VERSION ""

NS_ :

BS_:

BU_: ADAS MRR_L MRR_M MPC CMRR_RL CMRR_RR CMRR_FL CMRR_FR MRR GW AVAP

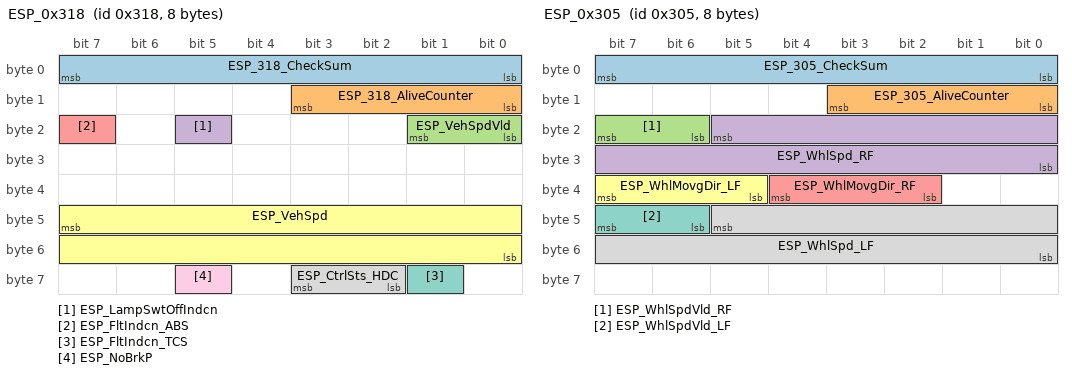
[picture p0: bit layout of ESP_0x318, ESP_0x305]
BO_ 792 ESP_0x318: 8 GW
 SG_ ESP_318_CheckSum : 7|8@0+ (1,0) [0|255] "" ADAS,MRR_L,MRR_M,MPC,CMRR_RL,CMRR_RR,CMRR_FL,CMRR_FR,MRR,AVAP
 SG_ ESP_318_AliveCounter : 11|4@0+ (1,0) [0|15] "" ADAS,MRR_L,MRR_M,MPC,CMRR_RL,CMRR_RR,CMRR_FL,CMRR_FR,MRR,AVAP
 SG_ ESP_VehSpdVld : 17|2@0+ (1,0) [0|3] "" ADAS,MRR_L,MRR_M,MPC,CMRR_RL,CMRR_RR,CMRR_FL,CMRR_FR,MRR,AVAP
 SG_ ESP_LampSwtOffIndcn : 21|1@0+ (1,0) [0|1] "" ADAS,MRR_L,MRR_M,CMRR_RL,CMRR_RR,CMRR_FL,CMRR_FR,MRR,AVAP
 SG_ ESP_FltIndcn_ABS : 23|1@0+ (1,0) [0|1] "" ADAS,MRR_L,MRR_M,MPC,CMRR_RL,CMRR_RR,CMRR_FL,CMRR_FR,MRR
 SG_ ESP_VehSpd : 47|16@0+ (0.1,0) [0|300] "km/h" ADAS,MRR_L,MRR_M,MPC,CMRR_RL,CMRR_RR,CMRR_FL,CMRR_FR,MRR,AVAP
 SG_ ESP_FltIndcn_TCS : 57|1@0+ (1,0) [0|1] "" ADAS,MRR_L,MRR_M,MPC,CMRR_RL,CMRR_RR,CMRR_FL,CMRR_FR,MRR
 SG_ ESP_CtrlSts_HDC : 59|2@0+ (1,0) [0|3] "" ADAS,MRR_L,MRR_M,CMRR_RL,CMRR_RR,CMRR_FL,CMRR_FR,MRR
 SG_ ESP_NoBrkP : 61|1@0+ (1,0) [0|1] "" ADAS,MRR_L,MRR_M,CMRR_RL,CMRR_RR,CMRR_FL,CMRR_FR,MRR

BO_ 609 ESP_0x261: 8 GW
 SG_ ESP_261_CheckSum : 7|8@0+ (1,0) [0|255] "" ADAS,MRR_L,MRR_M,MPC,CMRR_RL,CMRR_RR,CMRR_FL,CMRR_FR,MRR,AVAP
 SG_ ESP_261_AliveCounter : 11|4@0+ (1,0) [0|15] "" ADAS,MRR_L,MRR_M,MPC,CMRR_RL,CMRR_RR,CMRR_FL,CMRR_FR,MRR,AVAP
 SG_ ESP_ActvSig : 16|1@0+ (1,0) [0|1] "" ADAS,MRR_L,MRR_M,MPC,CMRR_RL,CMRR_RR,CMRR_FL,CMRR_FR,MRR,AVAP
 SG_ ESP_ActvSig_TCS : 17|1@0+ (1,0) [0|1] "" ADAS,MRR_L,MRR_M,CMRR_RL,CMRR_RR,CMRR_FL,CMRR_FR,MRR,AVAP
 SG_ ESP_ActvSig_EBD : 19|1@0+ (1,0) [0|1] "" ADAS,MRR_L,MRR_M,CMRR_RL,CMRR_RR,CMRR_FL,CMRR_FR,MRR,AVAP
 SG_ ESP_ActvSig_DTC : 20|1@0+ (1,0) [0|1] "" ADAS,MRR_L,MRR_M,CMRR_RL,CMRR_RR,CMRR_FL,CMRR_FR,MRR
 SG_ ESP_Actvndcn_CDD : 24|1@0+ (1,0) [0|1] "" ADAS,MRR_L,MRR_M
 SG_ ESP_FltIndcn_CDD : 25|1@0+ (1,0) [0|1] "" ADAS,MRR_L,MRR_M
 SG_ ESP_ActvIndcn_ABA : 26|1@0+ (1,0) [0|1] "" ADAS,MRR_L,MRR_M,MRR
 SG_ ESP_FltIndcn_ABA : 27|1@0+ (1,0) [0|1] "" ADAS,MRR_L,MRR_M,MRR
 SG_ ESP_ActvIndcn_ABP : 28|1@0+ (1,0) [0|1] "" ADAS,MRR_L,MRR_M,MRR
 SG_ ESP_FltIndcn_ABP : 29|1@0+ (1,0) [0|1] "" ADAS,MRR_L,MRR_M,MRR
 SG_ ESP_ActvIndcn_AEB : 30|1@0+ (1,0) [0|1] "" ADAS,MRR_L,MRR_M,CMRR_RL,CMRR_RR,MRR
 SG_ ESP_FltIndcn_AEB : 31|1@0+ (1,0) [0|1] "" ADAS,MRR_L,MRR_M,CMRR_RL,CMRR_RR,MRR
 SG_ ESP_ActvIndcn_AWB : 32|1@0+ (1,0) [0|1] "" ADAS,MRR_L,MRR_M,MRR
 SG_ ESP_FltIndcn_AWB : 33|1@0+ (1,0) [0|1] "" ADAS,MRR_L,MRR_M,MRR
 SG_ ESP_VehStandstillIndcn : 35|2@0+ (1,0) [0|3] "" ADAS,MRR_L,MRR_M,CMRR_RL,CMRR_RR,CMRR_FL,CMRR_FR,MRR
 SG_ ESP_BrkOverTIndcn : 36|1@0+ (1,0) [0|1] "" ADAS,MRR_L,MRR_M,MRR

BO_ 773 ESP_0x305: 8 GW
 SG_ ESP_305_CheckSum : 7|8@0+ (1,0) [0|255] "" ADAS,MRR_L,MRR_M,MPC,CMRR_RL,CMRR_RR,CMRR_FL,CMRR_FR,MRR,AVAP
 SG_ ESP_305_AliveCounter : 11|4@0+ (1,0) [0|15] "" ADAS,MRR_L,MRR_M,MPC,CMRR_RL,CMRR_RR,CMRR_FL,CMRR_FR,MRR,AVAP
 SG_ ESP_WhlSpdVld_RF : 23|2@0+ (1,0) [0|3] "" ADAS,MRR_L,MRR_M,MPC,CMRR_RL,CMRR_RR,CMRR_FL,CMRR_FR,MRR,AVAP
 SG_ ESP_WhlSpd_RF : 21|14@0+ (0.0625,0) [0|300] "km/h" ADAS,MRR_L,MRR_M,MPC,CMRR_RL,CMRR_RR,CMRR_FL,CMRR_FR,MRR,AVAP
 SG_ ESP_WhlMovgDir_RF : 36|3@0+ (1,0) [0|7] "" ADAS,MRR_L,MRR_M,MPC,CMRR_RL,CMRR_RR,CMRR_FL,CMRR_FR,MRR,AVAP
 SG_ ESP_WhlMovgDir_LF : 39|3@0+ (1,0) [0|7] "" ADAS,MRR_L,MRR_M,MPC,CMRR_RL,CMRR_RR,CMRR_FL,CMRR_FR,MRR,AVAP
 SG_ ESP_WhlSpdVld_LF : 47|2@0+ (1,0) [0|3] "" ADAS,MRR_L,MRR_M,MPC,CMRR_RL,CMRR_RR,CMRR_FL,CMRR_FR,MRR,AVAP
 SG_ ESP_WhlSpd_LF : 45|14@0+ (0.0625,0) [0|300] "km/h" ADAS,MRR_L,MRR_M,MPC,CMRR_RL,CMRR_RR,CMRR_FL,CMRR_FR,MRR,AVAP

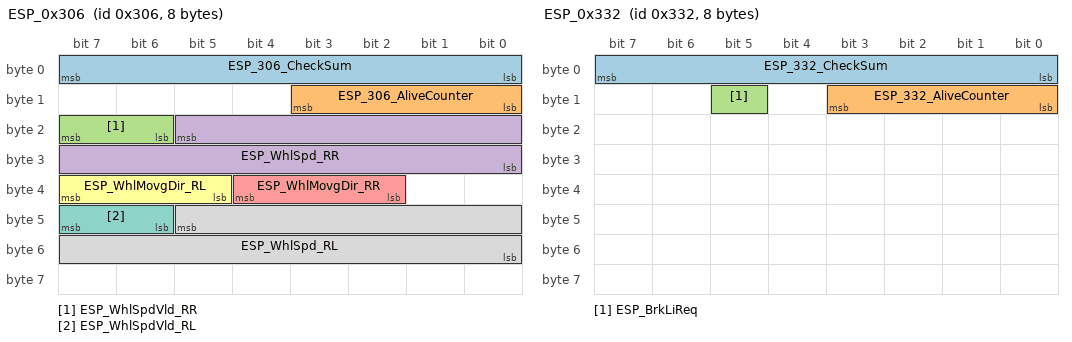
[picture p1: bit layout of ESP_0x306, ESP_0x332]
BO_ 774 ESP_0x306: 8 GW
 SG_ ESP_306_CheckSum : 7|8@0+ (1,0) [0|255] "" ADAS,MRR_L,MRR_M,MPC,CMRR_RL,CMRR_RR,CMRR_FL,CMRR_FR,MRR,AVAP
 SG_ ESP_306_AliveCounter : 11|4@0+ (1,0) [0|15] "" ADAS,MRR_L,MRR_M,MPC,CMRR_RL,CMRR_RR,CMRR_FL,CMRR_FR,MRR,AVAP
 SG_ ESP_WhlSpdVld_RR : 23|2@0+ (1,0) [0|3] "" ADAS,MRR_L,MRR_M,MPC,CMRR_RL,CMRR_RR,CMRR_FL,CMRR_FR,MRR,AVAP
 SG_ ESP_WhlSpd_RR : 21|14@0+ (0.0625,0) [0|300] "km/h" ADAS,MRR_L,MRR_M,MPC,CMRR_RL,CMRR_RR,CMRR_FL,CMRR_FR,MRR,AVAP
 SG_ ESP_WhlMovgDir_RR : 36|3@0+ (1,0) [0|7] "" ADAS,MRR_L,MRR_M,MPC,CMRR_RL,CMRR_RR,CMRR_FL,CMRR_FR,MRR,AVAP
 SG_ ESP_WhlMovgDir_RL : 39|3@0+ (1,0) [0|7] "" ADAS,MRR_L,MRR_M,MPC,CMRR_RL,CMRR_RR,CMRR_FL,CMRR_FR,MRR,AVAP
 SG_ ESP_WhlSpdVld_RL : 47|2@0+ (1,0) [0|3] "" ADAS,MRR_L,MRR_M,MPC,CMRR_RL,CMRR_RR,CMRR_FL,CMRR_FR,MRR,AVAP
 SG_ ESP_WhlSpd_RL : 45|14@0+ (0.0625,0) [0|300] "km/h" ADAS,MRR_L,MRR_M,MPC,CMRR_RL,CMRR_RR,CMRR_FL,CMRR_FR,MRR,AVAP

BO_ 818 ESP_0x332: 8 GW
 SG_ ESP_332_CheckSum : 7|8@0+ (1,0) [0|255] "" ADAS,MRR_L,MRR_M,MRR,AVAP
 SG_ ESP_332_AliveCounter : 11|4@0+ (1,0) [0|15] "" ADAS,MRR_L,MRR_M,MRR,AVAP
 SG_ ESP_BrkLiReq : 13|1@0+ (1,0) [0|1] "" ADAS,MRR_L,MRR_M,MRR

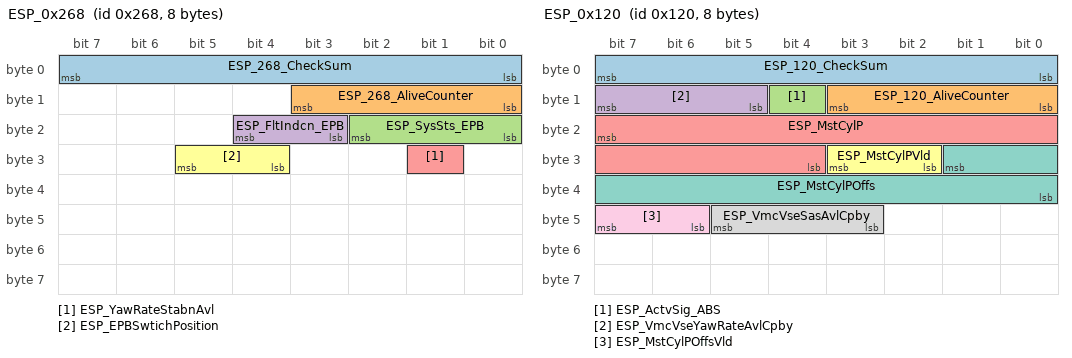
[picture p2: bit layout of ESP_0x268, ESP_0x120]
BO_ 616 ESP_0x268: 8 GW
 SG_ ESP_268_CheckSum : 7|8@0+ (1,0) [0|255] "" ADAS,MRR_L,MRR_M,MRR,AVAP
 SG_ ESP_268_AliveCounter : 11|4@0+ (1,0) [0|15] "" ADAS,MRR_L,MRR_M,MRR,AVAP
 SG_ ESP_SysSts_EPB : 18|3@0+ (1,0) [0|7] "" ADAS,MRR_L,MRR_M,AVAP
 SG_ ESP_FltIndcn_EPB : 20|2@0+ (1,0) [0|3] "" ADAS,MRR_L,MRR_M,AVAP
 SG_ ESP_YawRateStabnAvl : 25|1@0+ (1,0) [0|1] "" ADAS,MRR_L,MRR_M,MRR
 SG_ ESP_EPBSwtichPosition : 29|2@0+ (1,0) [0|3] "" ADAS,MRR_L,MRR_M,AVAP

BO_ 288 ESP_0x120: 8 GW
 SG_ ESP_120_CheckSum : 7|8@0+ (1,0) [0|255] "" ADAS,MRR_L,MRR_M,MPC,CMRR_RL,CMRR_RR,CMRR_FL,CMRR_FR,MRR,AVAP
 SG_ ESP_120_AliveCounter : 11|4@0+ (1,0) [0|15] "" ADAS,MRR_L,MRR_M,MPC,CMRR_RL,CMRR_RR,CMRR_FL,CMRR_FR,MRR,AVAP
 SG_ ESP_ActvSig_ABS : 12|1@0+ (1,0) [0|1] "" ADAS,MRR_L,MRR_M,MPC,CMRR_RL,CMRR_RR,CMRR_FL,CMRR_FR,MRR,AVAP
 SG_ ESP_VmcVseYawRateAvlCpby : 15|3@0+ (1,0) [0|7] "" ADAS,MRR_L,MRR_M,MRR
 SG_ ESP_MstCylP : 23|12@0+ (0.1,-30) [-30|276.6] "bar" ADAS,MRR_L,MRR_M,MPC,CMRR_RL,CMRR_RR,CMRR_FL,CMRR_FR,MRR,AVAP
 SG_ ESP_MstCylPVld : 27|2@0+ (1,0) [0|3] "" ADAS,MRR_L,MRR_M,MPC,CMRR_RL,CMRR_RR,CMRR_FL,CMRR_FR,MRR,AVAP
 SG_ ESP_MstCylPOffs : 25|10@0+ (0.1,-15) [-15|15] "bar" ADAS,MRR_L,MRR_M,MPC,CMRR_RL,CMRR_RR,CMRR_FL,CMRR_FR,MRR,AVAP
 SG_ ESP_VmcVseSasAvlCpby : 45|3@0+ (1,0) [0|7] "" ADAS,MRR_L,MRR_M,MRR
 SG_ ESP_MstCylPOffsVld : 47|2@0+ (1,0) [0|3] "" ADAS,MRR_L,MRR_M,MPC,CMRR_RL,CMRR_RR,CMRR_FL,CMRR_FR,MRR,AVAP

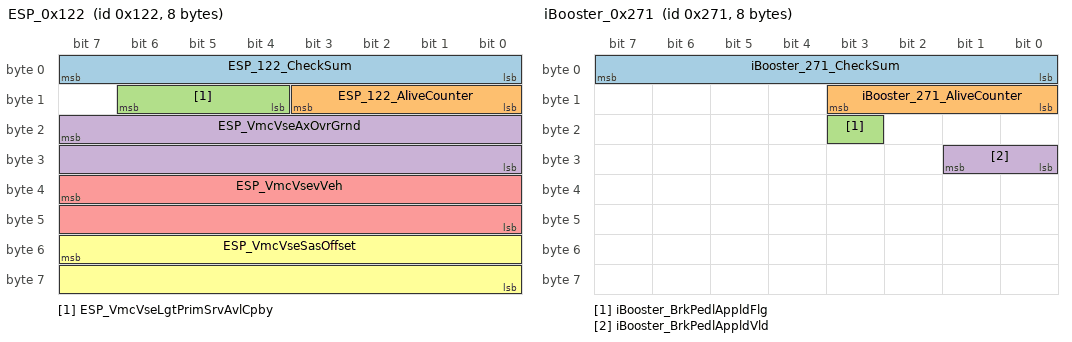
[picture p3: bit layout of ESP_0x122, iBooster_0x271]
BO_ 290 ESP_0x122: 8 GW
 SG_ ESP_122_CheckSum : 7|8@0+ (1,0) [0|255] "" ADAS,MRR_L,MRR_M,MRR,AVAP
 SG_ ESP_122_AliveCounter : 11|4@0+ (1,0) [0|15] "" ADAS,MRR_L,MRR_M,MRR,AVAP
 SG_ ESP_VmcVseLgtPrimSrvAvlCpby : 14|3@0+ (1,0) [0|7] "" ADAS,MRR_L,MRR_M,MRR,AVAP
 SG_ ESP_VmcVseAxOvrGrnd : 23|16@0+ (0.00125,-40.96) [-40.96|40.9575] "m/s2" ADAS,MRR_L,MRR_M,MRR,AVAP
 SG_ ESP_VmcVsevVeh : 39|16@0+ (0.01,-100) [-100|400] "kph" ADAS,MRR_L,MRR_M,MRR,AVAP
 SG_ ESP_VmcVseSasOffset : 55|16@0+ (0.1,-780) [-780|780] "°" ADAS,MRR_L,MRR_M,MRR

BO_ 625 iBooster_0x271: 8 GW
 SG_ iBooster_271_CheckSum : 7|8@0+ (1,0) [0|255] "" ADAS,MRR_L,MRR_M,MPC,CMRR_RL,CMRR_RR,CMRR_FL,CMRR_FR,MRR,AVAP
 SG_ iBooster_271_AliveCounter : 11|4@0+ (1,0) [0|15] "" ADAS,MRR_L,MRR_M,MPC,CMRR_RL,CMRR_RR,CMRR_FL,CMRR_FR,MRR,AVAP
 SG_ iBooster_BrkPedlAppldFlg : 19|1@0+ (1,0) [0|1] "" ADAS,MRR_L,MRR_M,MPC,CMRR_RL,CMRR_RR,CMRR_FL,CMRR_FR,MRR,AVAP
 SG_ iBooster_BrkPedlAppldVld : 25|2@0+ (1,0) [0|3] "" ADAS,MRR_L,MRR_M,MPC,CMRR_RL,CMRR_RR,CMRR_FL,CMRR_FR,MRR,AVAP

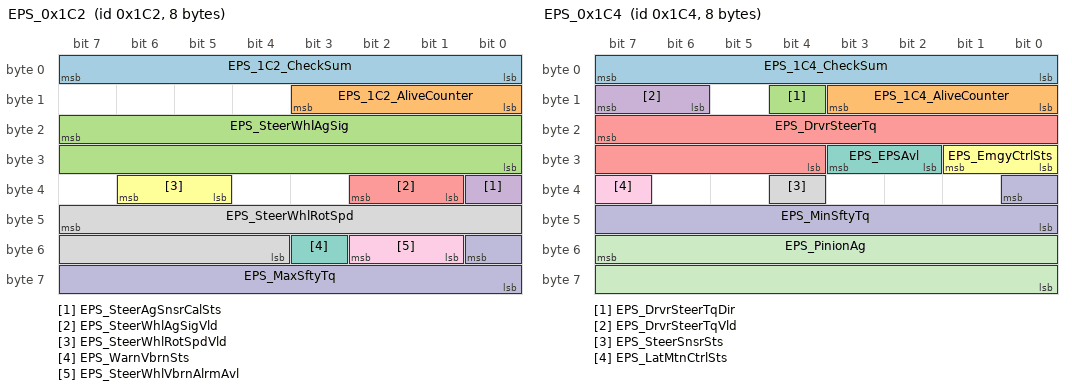
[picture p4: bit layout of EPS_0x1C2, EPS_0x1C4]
BO_ 450 EPS_0x1C2: 8 GW
 SG_ EPS_1C2_CheckSum : 7|8@0+ (1,0) [0|255] "" ADAS,MRR_L,MRR_M,MPC,CMRR_RL,CMRR_RR,CMRR_FL,CMRR_FR,MRR,AVAP
 SG_ EPS_1C2_AliveCounter : 11|4@0+ (1,0) [0|15] "" ADAS,MRR_L,MRR_M,MPC,CMRR_RL,CMRR_RR,CMRR_FL,CMRR_FR,MRR,AVAP
 SG_ EPS_SteerWhlAgSig : 23|16@0+ (0.0625,-780) [-780|780] "°" ADAS,MRR_L,MRR_M,MPC,CMRR_RL,CMRR_RR,CMRR_FL,CMRR_FR,MRR,AVAP
 SG_ EPS_SteerAgSnsrCalSts : 32|1@0+ (1,0) [0|1] "" ADAS,MRR_L,MRR_M,MPC,CMRR_RL,CMRR_RR,CMRR_FL,CMRR_FR,MRR,AVAP
 SG_ EPS_SteerWhlAgSigVld : 34|2@0+ (1,0) [0|3] "" ADAS,MRR_L,MRR_M,MPC,CMRR_RL,CMRR_RR,CMRR_FL,CMRR_FR,MRR,AVAP
 SG_ EPS_SteerWhlRotSpdVld : 38|2@0+ (1,0) [0|3] "" ADAS,MRR_L,MRR_M,MPC,CMRR_RL,CMRR_RR,CMRR_FL,CMRR_FR,MRR
 SG_ EPS_WarnVbrnSts : 51|1@0+ (1,0) [0|1] "" ADAS,MRR_L,MRR_M
 SG_ EPS_SteerWhlRotSpd : 47|12@0+ (0.5,-1016) [-1016|1016] "°/s" ADAS,MRR_L,MRR_M,MPC,CMRR_RL,CMRR_RR,CMRR_FL,CMRR_FR,MRR
 SG_ EPS_SteerWhlVbrnAlrmAvl : 50|2@0+ (1,0) [0|3] "" ADAS,MRR_L,MRR_M
 SG_ EPS_MaxSftyTq : 48|9@0+ (0.02,0) [0|10.22] "N·m" ADAS,MRR_L,MRR_M

BO_ 452 EPS_0x1C4: 8 GW
 SG_ EPS_1C4_CheckSum : 7|8@0+ (1,0) [0|255] "" ADAS,MRR_L,MRR_M,MPC,CMRR_RL,CMRR_RR,CMRR_FL,CMRR_FR,MRR,AVAP
 SG_ EPS_1C4_AliveCounter : 11|4@0+ (1,0) [0|15] "" ADAS,MRR_L,MRR_M,MPC,CMRR_RL,CMRR_RR,CMRR_FL,CMRR_FR,MRR,AVAP
 SG_ EPS_DrvrSteerTqDir : 12|1@0+ (1,0) [0|1] "" ADAS,MRR_L,MRR_M
 SG_ EPS_DrvrSteerTqVld : 15|2@0+ (1,0) [0|3] "" ADAS,MRR_L,MRR_M
 SG_ EPS_DrvrSteerTq : 23|12@0+ (0.01,0) [0|8] "N·m" ADAS,MRR_L,MRR_M
 SG_ EPS_EmgyCtrlSts : 25|2@0+ (1,0) [0|3] "" ADAS,MRR_L,MRR_M
 SG_ EPS_EPSAvl : 27|2@0+ (1,0) [0|3] "" ADAS,MRR_L,MRR_M
 SG_ EPS_SteerSnsrSts : 36|1@0+ (1,0) [0|1] "" ADAS,MRR_L,MRR_M,MPC,CMRR_RL,CMRR_RR,CMRR_FL,CMRR_FR,MRR,AVAP
 SG_ EPS_LatMtnCtrlSts : 39|1@0+ (1,0) [0|1] "" ADAS,MRR_L,MRR_M
 SG_ EPS_MinSftyTq : 32|9@0+ (0.02,-10.22) [-10.22|0] "N·m" ADAS,MRR_L,MRR_M
 SG_ EPS_PinionAg : 55|16@0+ (0.0625,-780) [-780|780] "°" ADAS,MRR_L,MRR_M

BO_ 1141 EPS_0x475: 8 GW
 SG_ EPS_ModSts : 10|2@0+ (1,0) [0|3] "" ADAS,MRR_L,MRR_M

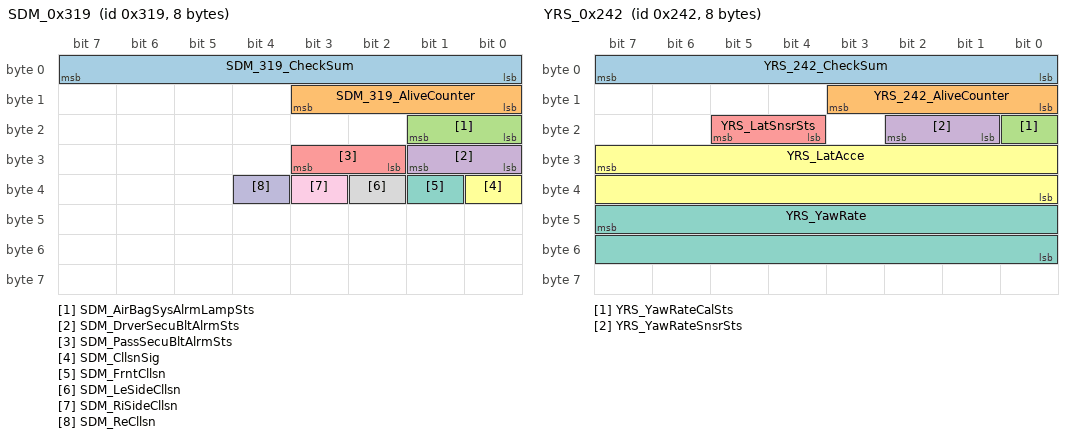
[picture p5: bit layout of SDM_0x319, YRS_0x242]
BO_ 793 SDM_0x319: 8 GW
 SG_ SDM_319_CheckSum : 7|8@0+ (1,0) [0|255] "" ADAS,MRR,AVAP
 SG_ SDM_319_AliveCounter : 11|4@0+ (1,0) [0|15] "" ADAS,MRR,AVAP
 SG_ SDM_AirBagSysAlrmLampSts : 17|2@0+ (1,0) [0|3] "" ADAS
 SG_ SDM_DrverSecuBltAlrmSts : 25|2@0+ (1,0) [0|3] "" ADAS,MRR_L,MRR_M,MRR,AVAP
 SG_ SDM_PassSecuBltAlrmSts : 27|2@0+ (1,0) [0|3] "" ADAS,AVAP
 SG_ SDM_CllsnSig : 32|1@0+ (1,0) [0|1] "" ADAS
 SG_ SDM_FrntCllsn : 33|1@0+ (1,0) [0|1] "" ADAS
 SG_ SDM_LeSideCllsn : 34|1@0+ (1,0) [0|1] "" ADAS
 SG_ SDM_RiSideCllsn : 35|1@0+ (1,0) [0|1] "" ADAS
 SG_ SDM_ReCllsn : 36|1@0+ (1,0) [0|1] "" ADAS

BO_ 578 YRS_0x242: 8 GW
 SG_ YRS_242_CheckSum : 7|8@0+ (1,0) [0|255] "" ADAS,MRR_L,MRR_M,MPC,CMRR_RL,CMRR_RR,CMRR_FL,CMRR_FR,MRR,AVAP
 SG_ YRS_242_AliveCounter : 11|4@0+ (1,0) [0|15] "" ADAS,MRR_L,MRR_M,MPC,CMRR_RL,CMRR_RR,CMRR_FL,CMRR_FR,MRR,AVAP
 SG_ YRS_YawRateCalSts : 16|1@0+ (1,0) [0|1] "" ADAS,MRR_L,MRR_M,CMRR_RL,CMRR_RR,CMRR_FL,CMRR_FR,MRR,AVAP
 SG_ YRS_YawRateSnsrSts : 18|2@0+ (1,0) [0|3] "" ADAS,MRR_L,MRR_M,MPC,CMRR_RL,CMRR_RR,CMRR_FL,CMRR_FR,MRR,AVAP
 SG_ YRS_LatSnsrSts : 21|2@0+ (1,0) [0|3] "" ADAS,MRR_L,MRR_M,MPC,CMRR_RL,CMRR_RR,CMRR_FL,CMRR_FR,MRR,AVAP
 SG_ YRS_LatAcce : 31|16@0+ (0.001,-2) [-2|2] "g" ADAS,MRR_L,MRR_M,MPC,CMRR_RL,CMRR_RR,CMRR_FL,CMRR_FR,MRR,AVAP
 SG_ YRS_YawRate : 47|16@0+ (0.01,-180) [-180|180] "°/s" ADAS,MRR_L,MRR_M,MPC,CMRR_RL,CMRR_RR,CMRR_FL,CMRR_FR,MRR,AVAP

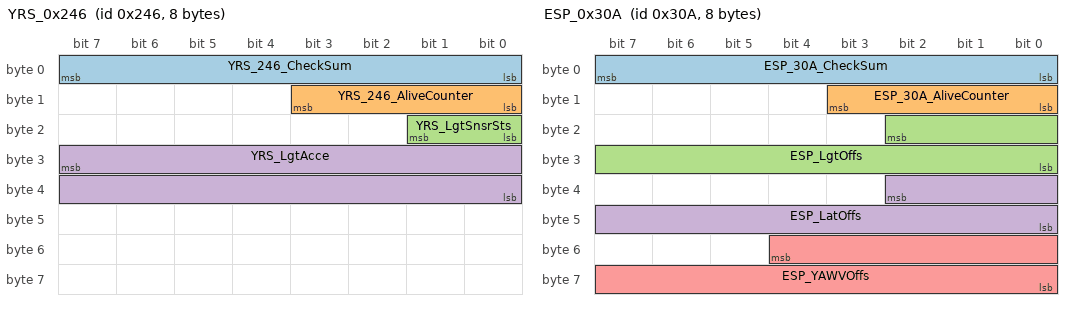
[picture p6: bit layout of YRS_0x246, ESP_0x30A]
BO_ 582 YRS_0x246: 8 GW
 SG_ YRS_246_CheckSum : 7|8@0+ (1,0) [0|255] "" ADAS,MRR_L,MRR_M,MPC,CMRR_RL,CMRR_RR,CMRR_FL,CMRR_FR,MRR,AVAP
 SG_ YRS_246_AliveCounter : 11|4@0+ (1,0) [0|15] "" ADAS,MRR_L,MRR_M,MPC,CMRR_RL,CMRR_RR,CMRR_FL,CMRR_FR,MRR,AVAP
 SG_ YRS_LgtSnsrSts : 17|2@0+ (1,0) [0|3] "" ADAS,MRR_L,MRR_M,MPC,CMRR_RL,CMRR_RR,CMRR_FL,CMRR_FR,MRR,AVAP
 SG_ YRS_LgtAcce : 31|16@0+ (0.001,-2) [-2|2] "g" ADAS,MRR_L,MRR_M,MPC,CMRR_RL,CMRR_RR,CMRR_FL,CMRR_FR,MRR,AVAP

BO_ 778 ESP_0x30A: 8 GW
 SG_ ESP_30A_CheckSum : 7|8@0+ (1,0) [0|255] "" ADAS,MRR_L,MRR_M,MPC,CMRR_RL,CMRR_RR,CMRR_FL,CMRR_FR,MRR,AVAP
 SG_ ESP_30A_AliveCounter : 11|4@0+ (1,0) [0|15] "" ADAS,MRR_L,MRR_M,MPC,CMRR_RL,CMRR_RR,CMRR_FL,CMRR_FR,MRR,AVAP
 SG_ ESP_LgtOffs : 18|11@0+ (0.0027127,-2.15928) [-2.15928|2.15928] "g" ADAS,MRR_L,MRR_M,MPC,MRR,AVAP
 SG_ ESP_LatOffs : 34|11@0+ (0.0027127,-2.15928) [-2.15928|2.15928] "g" ADAS,MRR_L,MRR_M,MPC,MRR,AVAP
 SG_ ESP_YAWVOffs : 52|13@0+ (0.056,-120) [-120|120] "°/s" ADAS,MRR_L,MRR_M,MPC,MRR,AVAP

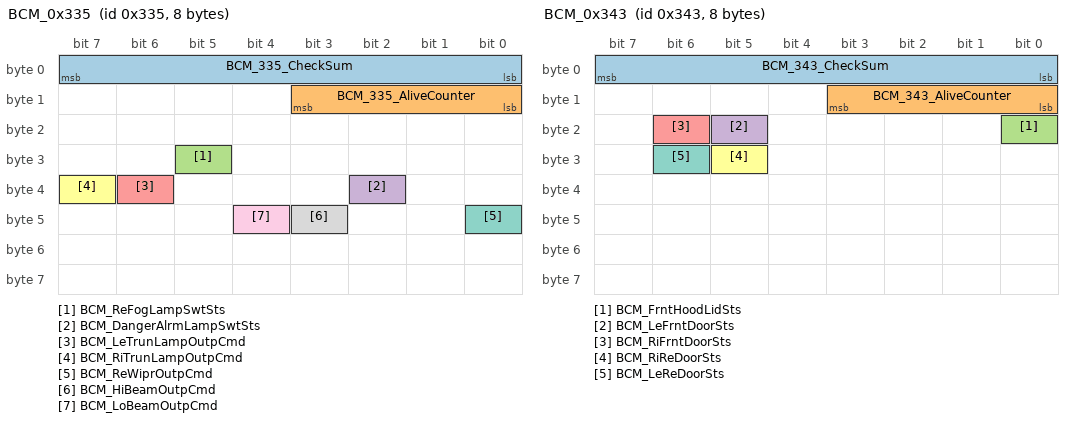
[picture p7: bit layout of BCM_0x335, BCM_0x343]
BO_ 821 BCM_0x335: 8 GW
 SG_ BCM_335_CheckSum : 7|8@0+ (1,0) [0|255] "" ADAS,MRR_L,MRR_M,MPC,CMRR_RL,CMRR_RR,MRR,AVAP
 SG_ BCM_335_AliveCounter : 11|4@0+ (1,0) [0|15] "" ADAS,MRR_L,MRR_M,MPC,CMRR_RL,CMRR_RR,MRR,AVAP
 SG_ BCM_ReFogLampSwtSts : 29|1@0+ (1,0) [0|1] "" ADAS,MPC
 SG_ BCM_DangerAlrmLampSwtSts : 34|1@0+ (1,0) [0|1] "" ADAS,MRR_L,MRR_M,MRR,AVAP
 SG_ BCM_LeTrunLampOutpCmd : 38|1@0+ (1,0) [0|1] "" ADAS,AVAP
 SG_ BCM_RiTrunLampOutpCmd : 39|1@0+ (1,0) [0|1] "" ADAS,AVAP
 SG_ BCM_ReWiprOutpCmd : 40|1@0+ (1,0) [0|1] "" ADAS,AVAP
 SG_ BCM_HiBeamOutpCmd : 43|1@0+ (1,0) [0|1] "" ADAS,MPC,AVAP
 SG_ BCM_LoBeamOutpCmd : 44|1@0+ (1,0) [0|1] "" ADAS,MPC,AVAP

BO_ 835 BCM_0x343: 8 GW
 SG_ BCM_343_CheckSum : 7|8@0+ (1,0) [0|255] "" ADAS,MRR_L,MRR_M,CMRR_RL,CMRR_RR,MRR,AVAP
 SG_ BCM_343_AliveCounter : 11|4@0+ (1,0) [0|15] "" ADAS,MRR_L,MRR_M,CMRR_RL,CMRR_RR,MRR,AVAP
 SG_ BCM_FrntHoodLidSts : 16|1@0+ (1,0) [0|1] "" ADAS,MRR_L,MRR_M,AVAP
 SG_ BCM_LeFrntDoorSts : 21|1@0+ (1,0) [0|1] "" ADAS,MRR_L,MRR_M,CMRR_RL,MRR,AVAP
 SG_ BCM_RiFrntDoorSts : 22|1@0+ (1,0) [0|1] "" ADAS,MRR_L,MRR_M,CMRR_RR,AVAP
 SG_ BCM_RiReDoorSts : 29|1@0+ (1,0) [0|1] "" ADAS,MRR_L,MRR_M,CMRR_RR,AVAP
 SG_ BCM_LeReDoorSts : 30|1@0+ (1,0) [0|1] "" ADAS,MRR_L,MRR_M,CMRR_RL,AVAP

BO_ 883 ECC_0x373: 8 GW
 SG_ ECC_OutdT : 47|8@0+ (0.5,-48) [-48|79.5] "℃" ADAS,MRR_L,MRR_M,MPC,CMRR_RL,CMRR_RR,CMRR_FL,CMRR_FR,MRR,AVAP
 SG_ ECC_OutdTVld : 49|2@0+ (1,0) [0|3] "" ADAS,MRR_L,MRR_M,MPC,CMRR_RL,CMRR_RR,CMRR_FL,CMRR_FR,MRR,AVAP

BO_ 1410 ECC_0x582: 8 GW
 SG_ ECC_InsdT : 7|8@0+ (0.5,-48) [-48|79] "℃" ADAS

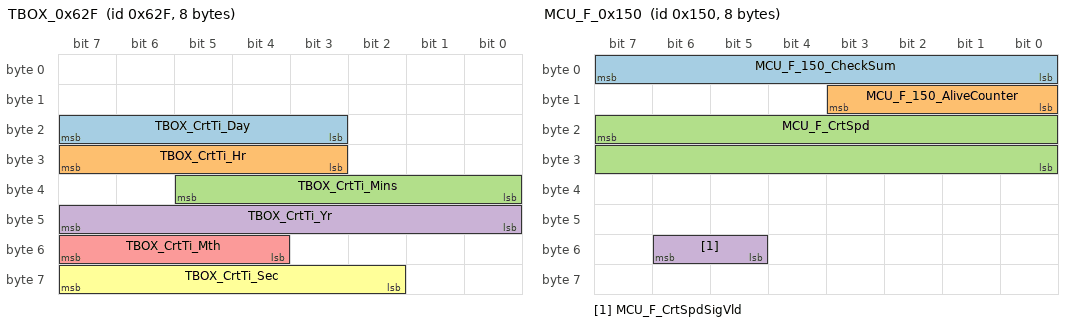
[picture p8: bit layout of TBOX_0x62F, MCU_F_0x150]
BO_ 1583 TBOX_0x62F: 8 GW
 SG_ TBOX_CrtTi_Day : 23|5@0+ (1,1) [1|31] "day" ADAS,MRR_L,MRR_M,MPC,CMRR_RL,CMRR_RR,CMRR_FL,CMRR_FR,MRR,AVAP
 SG_ TBOX_CrtTi_Hr : 31|5@0+ (1,0) [0|23] "hour" ADAS,MRR_L,MRR_M,MPC,CMRR_RL,CMRR_RR,CMRR_FL,CMRR_FR,MRR,AVAP
 SG_ TBOX_CrtTi_Mins : 37|6@0+ (1,0) [0|59] "mintue" ADAS,MRR_L,MRR_M,MPC,CMRR_RL,CMRR_RR,CMRR_FL,CMRR_FR,MRR,AVAP
 SG_ TBOX_CrtTi_Yr : 47|8@0+ (1,2015) [2015|2270] "year" ADAS,MRR_L,MRR_M,MPC,CMRR_RL,CMRR_RR,CMRR_FL,CMRR_FR,MRR,AVAP
 SG_ TBOX_CrtTi_Mth : 55|4@0+ (1,1) [1|12] "month" ADAS,MRR_L,MRR_M,MPC,CMRR_RL,CMRR_RR,CMRR_FL,CMRR_FR,MRR,AVAP
 SG_ TBOX_CrtTi_Sec : 63|6@0+ (1,0) [0|59] "second" ADAS,MRR_L,MRR_M,MPC,CMRR_RL,CMRR_RR,CMRR_FL,CMRR_FR,MRR,AVAP

BO_ 336 MCU_F_0x150: 8 GW
 SG_ MCU_F_150_CheckSum : 7|8@0+ (1,0) [0|255] "" ADAS,MRR_L,MRR_M
 SG_ MCU_F_150_AliveCounter : 11|4@0+ (1,0) [0|15] "" ADAS,MRR_L,MRR_M
 SG_ MCU_F_CrtSpd : 23|16@0+ (1,-32768) [-32768|32767] "rpm" ADAS,MRR_L,MRR_M
 SG_ MCU_F_CrtSpdSigVld : 54|2@0+ (1,0) [0|3] "" ADAS,MRR_L,MRR_M

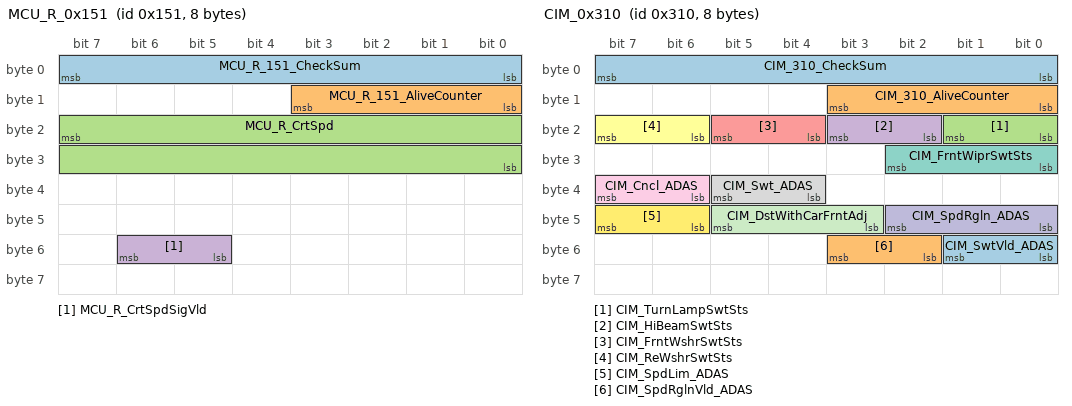
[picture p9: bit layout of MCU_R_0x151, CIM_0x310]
BO_ 337 MCU_R_0x151: 8 GW
 SG_ MCU_R_151_CheckSum : 7|8@0+ (1,0) [0|255] "" ADAS
 SG_ MCU_R_151_AliveCounter : 11|4@0+ (1,0) [0|15] "" ADAS
 SG_ MCU_R_CrtSpd : 23|16@0+ (1,-32768) [-32768|32767] "rpm" ADAS
 SG_ MCU_R_CrtSpdSigVld : 54|2@0+ (1,0) [0|3] "" ADAS

BO_ 1137 PLG_0x471: 8 GW
 SG_ PLG_TrSwtStsIndcn : 36|3@0+ (1,0) [0|7] "" ADAS,MRR_L,MRR_M,MRR,AVAP

BO_ 784 CIM_0x310: 8 GW
 SG_ CIM_310_CheckSum : 7|8@0+ (1,0) [0|255] "" ADAS,MRR_L,MRR_M,MPC,CMRR_RL,CMRR_RR,CMRR_FL,CMRR_FR,MRR,AVAP
 SG_ CIM_310_AliveCounter : 11|4@0+ (1,0) [0|15] "" ADAS,MRR_L,MRR_M,MPC,CMRR_RL,CMRR_RR,CMRR_FL,CMRR_FR,MRR,AVAP
 SG_ CIM_TurnLampSwtSts : 17|2@0+ (1,0) [0|3] "" ADAS,MRR_L,MRR_M,MPC,CMRR_RL,CMRR_RR,CMRR_FL,CMRR_FR,MRR,AVAP
 SG_ CIM_HiBeamSwtSts : 19|2@0+ (1,0) [0|3] "" ADAS,MPC
 SG_ CIM_FrntWshrSwtSts : 21|2@0+ (1,0) [0|3] "" ADAS,MPC
 SG_ CIM_ReWshrSwtSts : 23|2@0+ (1,0) [0|3] "" ADAS
 SG_ CIM_FrntWiprSwtSts : 26|3@0+ (1,0) [0|7] "" ADAS,MPC
 SG_ CIM_Swt_ADAS : 37|2@0+ (1,0) [0|3] "" ADAS,MRR_L,MRR_M
 SG_ CIM_Cncl_ADAS : 39|2@0+ (1,0) [0|3] "" ADAS,MRR_L,MRR_M
 SG_ CIM_SpdRgln_ADAS : 42|3@0+ (1,0) [0|7] "" ADAS,MRR_L,MRR_M
 SG_ CIM_DstWithCarFrntAdj : 45|3@0+ (1,0) [0|7] "" ADAS,MRR_L,MRR_M
 SG_ CIM_SpdLim_ADAS : 47|2@0+ (1,0) [0|3] "" ADAS,MRR_L,MRR_M,MPC
 SG_ CIM_SwtVld_ADAS : 49|2@0+ (1,0) [0|3] "" ADAS,MRR_L,MRR_M
 SG_ CIM_SpdRglnVld_ADAS : 51|2@0+ (1,0) [0|3] "" ADAS,MRR_L,MRR_M

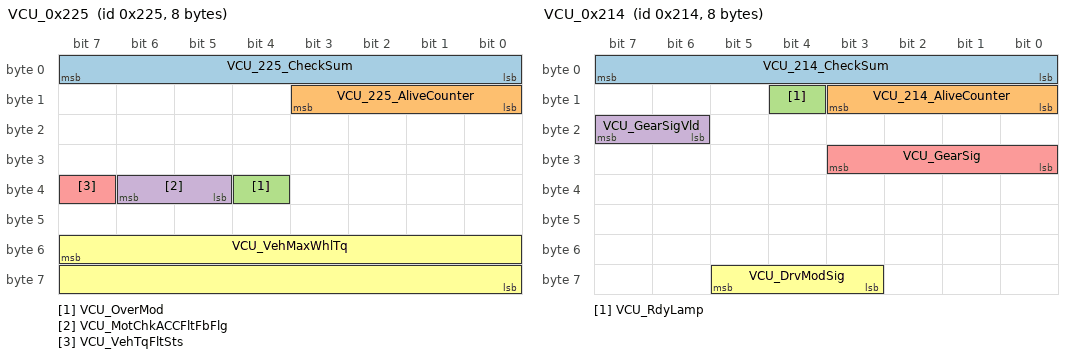
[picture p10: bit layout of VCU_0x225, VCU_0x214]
BO_ 549 VCU_0x225: 8 GW
 SG_ VCU_225_CheckSum : 7|8@0+ (1,0) [0|255] "" ADAS,MRR_L,MRR_M,MRR,AVAP
 SG_ VCU_225_AliveCounter : 11|4@0+ (1,0) [0|15] "" ADAS,MRR_L,MRR_M,MRR,AVAP
 SG_ VCU_OverMod : 36|1@0+ (1,0) [0|1] "" ADAS,MRR_L,MRR_M,MRR
 SG_ VCU_MotChkACCFltFbFlg : 38|2@0+ (1,0) [0|3] "" ADAS,MRR_L,MRR_M
 SG_ VCU_VehTqFltSts : 39|1@0+ (1,0) [0|1] "" ADAS,MRR_L,MRR_M
 SG_ VCU_VehMaxWhlTq : 55|16@0+ (1,-32768) [-32768|32767] "N·m" ADAS,MRR_L,MRR_M

BO_ 532 VCU_0x214: 8 GW
 SG_ VCU_214_CheckSum : 7|8@0+ (1,0) [0|255] "" ADAS,MRR_L,MRR_M,CMRR_RL,CMRR_RR,CMRR_FL,CMRR_FR,MRR,AVAP
 SG_ VCU_214_AliveCounter : 11|4@0+ (1,0) [0|15] "" ADAS,MRR_L,MRR_M,CMRR_RL,CMRR_RR,CMRR_FL,CMRR_FR,MRR,AVAP
 SG_ VCU_RdyLamp : 12|1@0+ (1,0) [0|1] "" ADAS,MRR_L,MRR_M,CMRR_RL,CMRR_RR,CMRR_FL,CMRR_FR,MRR,AVAP
 SG_ VCU_GearSigVld : 23|2@0+ (1,0) [0|3] "" ADAS,MRR_L,MRR_M,CMRR_RL,CMRR_RR,CMRR_FL,CMRR_FR,MRR,AVAP
 SG_ VCU_GearSig : 27|4@0+ (1,0) [0|15] "" ADAS,MRR_L,MRR_M,CMRR_RL,CMRR_RR,CMRR_FL,CMRR_FR,MRR,AVAP
 SG_ VCU_DrvModSig : 61|3@0+ (1,0) [0|7] "" ADAS,MRR_L,MRR_M

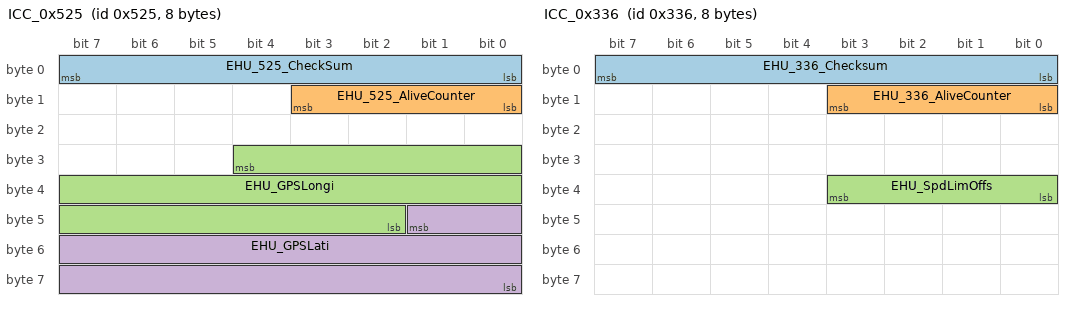
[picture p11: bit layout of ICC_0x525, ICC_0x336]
BO_ 1317 ICC_0x525: 8 GW
 SG_ EHU_525_CheckSum : 7|8@0+ (1,0) [0|255] "" ADAS,MRR_L,MRR_M,MRR
 SG_ EHU_525_AliveCounter : 11|4@0+ (1,0) [0|15] "" ADAS,MRR_L,MRR_M,MRR
 SG_ EHU_GPSLongi : 28|19@0+ (0.001,-180) [-180|179.99] "°" ADAS,MRR_L,MRR_M,MRR
 SG_ EHU_GPSLati : 41|18@0+ (0.001,-90) [-90|90] "°" ADAS,MRR_L,MRR_M,MRR

BO_ 822 ICC_0x336: 8 GW
 SG_ EHU_336_Checksum : 7|8@0+ (1,0) [0|255] "" ADAS,MRR_L,MRR_M,MPC
 SG_ EHU_336_AliveCounter : 11|4@0+ (1,0) [0|15] "" ADAS,MRR_L,MRR_M,MPC
 SG_ EHU_SpdLimOffs : 35|4@0+ (1,0) [0|15] "" ADAS,MRR_L,MRR_M,MPC

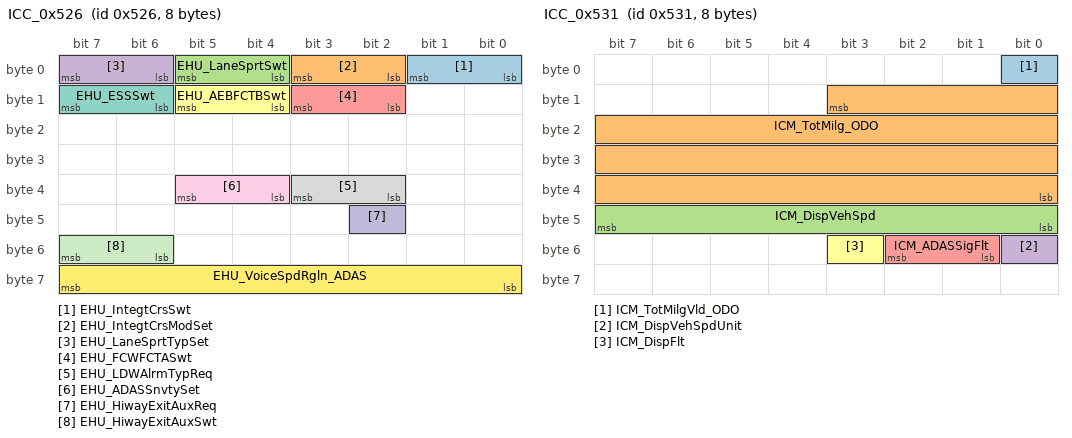
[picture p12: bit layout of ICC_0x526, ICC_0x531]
BO_ 1318 ICC_0x526: 8 GW
 SG_ EHU_IntegtCrsSwt : 1|2@0+ (1,0) [0|3] "" ADAS,MRR_L,MRR_M
 SG_ EHU_IntegtCrsModSet : 3|2@0+ (1,0) [0|3] "" ADAS,MRR_L,MRR_M
 SG_ EHU_LaneSprtSwt : 5|2@0+ (1,0) [0|3] "" ADAS,MRR_L,MRR_M
 SG_ EHU_LaneSprtTypSet : 7|2@0+ (1,0) [0|3] "" ADAS,MRR_L,MRR_M
 SG_ EHU_FCWFCTASwt : 11|2@0+ (1,0) [0|3] "" ADAS,MRR_L,MRR_M,CMRR_FL,CMRR_FR,MRR
 SG_ EHU_AEBFCTBSwt : 13|2@0+ (1,0) [0|3] "" ADAS,MRR_L,MRR_M,CMRR_FL,CMRR_FR,MRR,AVAP
 SG_ EHU_ESSSwt : 15|2@0+ (1,0) [0|3] "" ADAS
 SG_ EHU_LDWAlrmTypReq : 35|2@0+ (1,0) [0|3] "" ADAS,MRR_L,MRR_M
 SG_ EHU_ADASSnvtySet : 37|2@0+ (1,0) [0|3] "" ADAS,MRR_L,MRR_M,MPC
 SG_ EHU_HiwayExitAuxReq : 42|1@0+ (1,0) [0|1] "" ADAS
 SG_ EHU_HiwayExitAuxSwt : 55|2@0+ (1,0) [0|3] "" ADAS
 SG_ EHU_VoiceSpdRgln_ADAS : 63|8@0+ (1,20) [20|275] "" ADAS,MRR_L,MRR_M

BO_ 1329 ICC_0x531: 8 GW
 SG_ ICM_TotMilgVld_ODO : 0|1@0+ (1,0) [0|1] "" ADAS,MRR_L,MRR_M,MPC,CMRR_RL,CMRR_RR,CMRR_FL,CMRR_FR,MRR,AVAP
 SG_ ICM_TotMilg_ODO : 11|28@0+ (0.01,0) [0|2000000] "km" ADAS,MRR_L,MRR_M,MPC,CMRR_RL,CMRR_RR,CMRR_FL,CMRR_FR,MRR,AVAP
 SG_ ICM_DispVehSpd : 47|8@0+ (1,0) [0|255] "" ADAS,MRR_L,MRR_M,MPC,CMRR_RL,CMRR_RR,CMRR_FL,CMRR_FR
 SG_ ICM_DispVehSpdUnit : 48|1@0+ (1,0) [0|1] "" ADAS,MRR_L,MRR_M,MPC,CMRR_RL,CMRR_RR,CMRR_FL,CMRR_FR
 SG_ ICM_ADASSigFlt : 50|2@0+ (1,0) [0|3] "" ADAS,MRR_L,MRR_M,MPC,CMRR_RL,CMRR_RR,CMRR_FL,CMRR_FR,MRR
 SG_ ICM_DispFlt : 51|1@0+ (1,0) [0|1] "" ADAS,MRR_L,MRR_M,MPC,CMRR_RL,CMRR_RR,CMRR_FL,CMRR_FR,MRR,AVAP

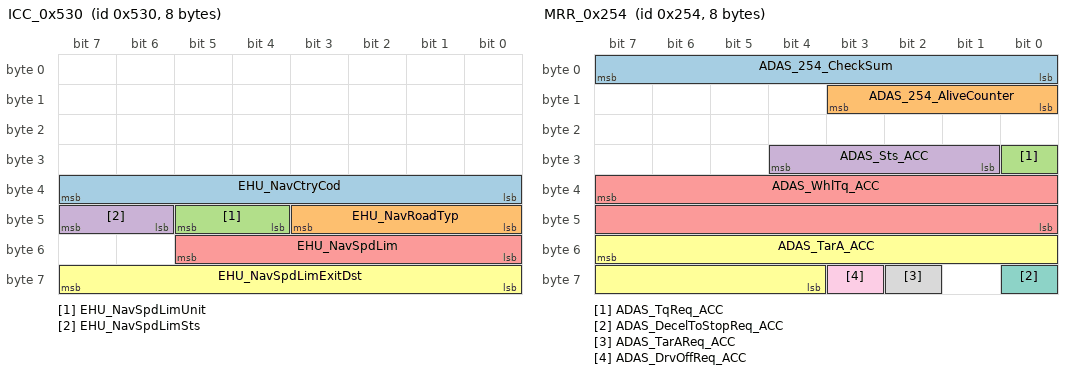
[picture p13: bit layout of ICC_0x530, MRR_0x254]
BO_ 1328 ICC_0x530: 8 GW
 SG_ EHU_NavCtryCod : 39|8@0+ (1,0) [0|255] "" ADAS,MPC
 SG_ EHU_NavRoadTyp : 43|4@0+ (1,0) [0|15] "" ADAS,MPC
 SG_ EHU_NavSpdLimUnit : 45|2@0+ (1,0) [0|3] "" ADAS,MPC
 SG_ EHU_NavSpdLimSts : 47|2@0+ (1,0) [0|3] "" ADAS,MPC
 SG_ EHU_NavSpdLim : 53|6@0+ (1,0) [0|63] "" ADAS,MPC
 SG_ EHU_NavSpdLimExitDst : 63|8@0+ (10,0) [0|2550] "m" ADAS

BO_ 596 MRR_0x254: 8 ADAS
 SG_ ADAS_254_CheckSum : 7|8@0+ (1,0) [0|255] "" GW
 SG_ ADAS_254_AliveCounter : 11|4@0+ (1,0) [0|15] "" GW
 SG_ ADAS_TqReq_ACC : 24|1@0+ (1,0) [0|1] "" GW
 SG_ ADAS_Sts_ACC : 28|4@0+ (1,0) [0|15] "" GW,AVAP
 SG_ ADAS_WhlTq_ACC : 39|16@0+ (1,-32768) [-32768|32767] "N·m" GW
 SG_ ADAS_TarA_ACC : 55|12@0+ (0.005,-7.22) [-7.22|3.015] "m/s2" GW
 SG_ ADAS_DecelToStopReq_ACC : 56|1@0+ (1,0) [0|1] "" GW
 SG_ ADAS_TarAReq_ACC : 58|1@0+ (1,0) [0|1] "" GW
 SG_ ADAS_DrvOffReq_ACC : 59|1@0+ (1,0) [0|1] "" GW

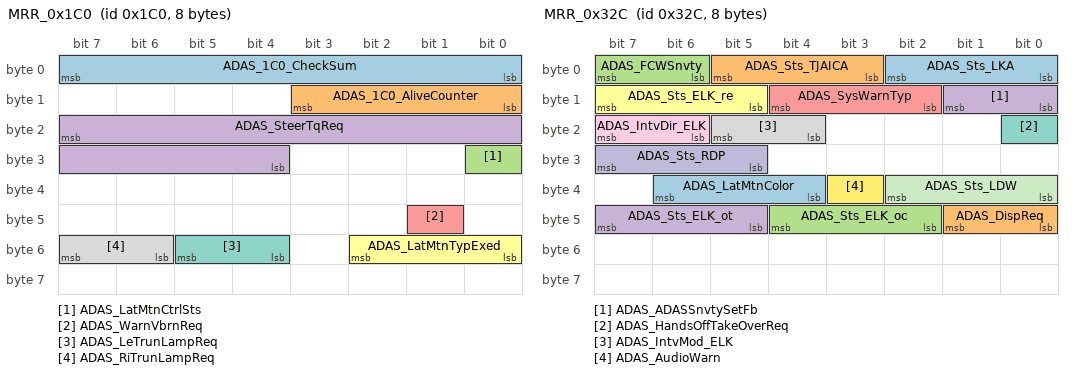
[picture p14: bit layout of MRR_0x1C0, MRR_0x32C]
BO_ 448 MRR_0x1C0: 8 ADAS
 SG_ ADAS_1C0_CheckSum : 7|8@0+ (1,0) [0|255] "" GW
 SG_ ADAS_1C0_AliveCounter : 11|4@0+ (1,0) [0|15] "" GW
 SG_ ADAS_LatMtnCtrlSts : 24|1@0+ (1,0) [0|1] "" GW
 SG_ ADAS_SteerTqReq : 23|12@0+ (0.01,-8) [-8|8] "N·m" GW
 SG_ ADAS_WarnVbrnReq : 41|1@0+ (1,0) [0|1] "" GW
 SG_ ADAS_LatMtnTypExed : 50|3@0+ (1,0) [0|7] "" GW
 SG_ ADAS_LeTrunLampReq : 53|2@0+ (1,0) [0|3] "" GW
 SG_ ADAS_RiTrunLampReq : 55|2@0+ (1,0) [0|3] "" GW

BO_ 812 MRR_0x32C: 8 ADAS
 SG_ ADAS_Sts_LKA : 2|3@0+ (1,0) [0|7] "" GW
 SG_ ADAS_Sts_TJAICA : 5|3@0+ (1,0) [0|7] "" GW,AVAP
 SG_ ADAS_FCWSnvty : 7|2@0+ (1,0) [0|3] "" GW
 SG_ ADAS_ADASSnvtySetFb : 9|2@0+ (1,0) [0|3] "" GW
 SG_ ADAS_SysWarnTyp : 12|3@0+ (1,0) [0|7] "" GW
 SG_ ADAS_Sts_ELK_re : 15|3@0+ (1,0) [0|7] "" GW
 SG_ ADAS_HandsOffTakeOverReq : 16|1@0+ (1,0) [0|1] "" GW
 SG_ ADAS_IntvMod_ELK : 21|2@0+ (1,0) [0|3] "" GW
 SG_ ADAS_IntvDir_ELK : 23|2@0+ (1,0) [0|3] "" GW
 SG_ ADAS_Sts_RDP : 31|3@0+ (1,0) [0|7] "" GW
 SG_ ADAS_Sts_LDW : 34|3@0+ (1,0) [0|7] "" GW
 SG_ ADAS_AudioWarn : 35|1@0+ (1,0) [0|1] "" GW
 SG_ ADAS_LatMtnColor : 38|3@0+ (1,0) [0|7] "" GW
 SG_ ADAS_DispReq : 41|2@0+ (1,0) [0|3] "" GW
 SG_ ADAS_Sts_ELK_oc : 44|3@0+ (1,0) [0|7] "" GW
 SG_ ADAS_Sts_ELK_ot : 47|3@0+ (1,0) [0|7] "" GW

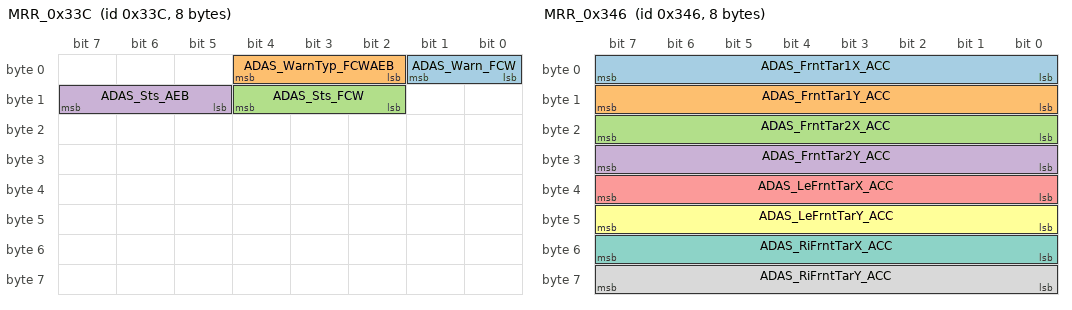
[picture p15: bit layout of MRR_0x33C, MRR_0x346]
BO_ 828 MRR_0x33C: 8 ADAS
 SG_ ADAS_Warn_FCW : 1|2@0+ (1,0) [0|3] "" GW
 SG_ ADAS_WarnTyp_FCWAEB : 4|3@0+ (1,0) [0|7] "" GW
 SG_ ADAS_Sts_FCW : 12|3@0+ (1,0) [0|7] "" GW
 SG_ ADAS_Sts_AEB : 15|3@0+ (1,0) [0|7] "" GW,AVAP

BO_ 830 MRR_0x33E: 8 MRR_L
 SG_ MRR_FrntSnsrFlt : 1|2@0+ (1,0) [0|3] "" ADAS,GW
 SG_ MRR_FrntSnsrBli : 3|2@0+ (1,0) [0|3] "" ADAS,GW

BO_ 838 MRR_0x346: 8 ADAS
 SG_ ADAS_FrntTar1X_ACC : 7|8@0+ (1,0) [0|255] "" GW
 SG_ ADAS_FrntTar1Y_ACC : 15|8@0+ (0.1,-12.7) [-12.7|12.8] "" GW
 SG_ ADAS_FrntTar2X_ACC : 23|8@0+ (1,0) [0|255] "" GW
 SG_ ADAS_FrntTar2Y_ACC : 31|8@0+ (0.1,-12.7) [-12.7|12.8] "" GW
 SG_ ADAS_LeFrntTarX_ACC : 39|8@0+ (1,0) [0|255] "" GW
 SG_ ADAS_LeFrntTarY_ACC : 47|8@0+ (0.1,-12.7) [-12.7|12.8] "" GW
 SG_ ADAS_RiFrntTarX_ACC : 55|8@0+ (1,0) [0|255] "" GW
 SG_ ADAS_RiFrntTarY_ACC : 63|8@0+ (0.1,-12.7) [-12.7|12.8] "" GW

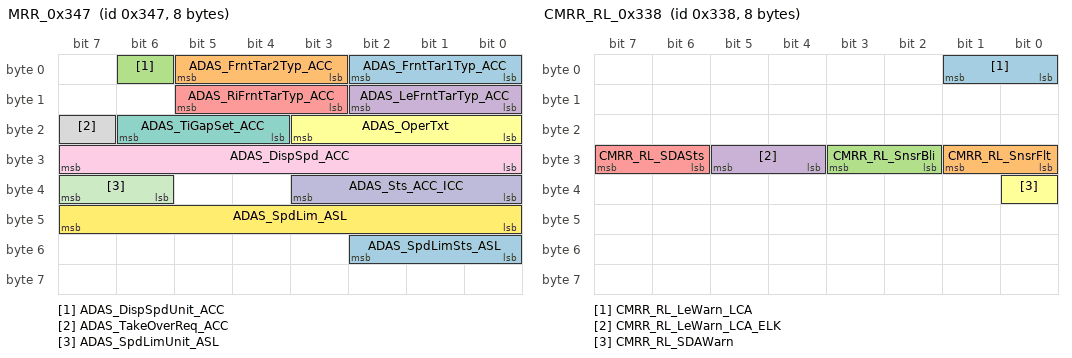
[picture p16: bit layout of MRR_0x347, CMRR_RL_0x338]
BO_ 839 MRR_0x347: 8 ADAS
 SG_ ADAS_FrntTar1Typ_ACC : 2|3@0+ (1,0) [0|7] "" GW
 SG_ ADAS_FrntTar2Typ_ACC : 5|3@0+ (1,0) [0|7] "" GW
 SG_ ADAS_DispSpdUnit_ACC : 6|1@0+ (1,0) [0|1] "" GW
 SG_ ADAS_LeFrntTarTyp_ACC : 10|3@0+ (1,0) [0|7] "" GW
 SG_ ADAS_RiFrntTarTyp_ACC : 13|3@0+ (1,0) [0|7] "" GW
 SG_ ADAS_OperTxt : 19|4@0+ (1,0) [0|15] "" GW
 SG_ ADAS_TiGapSet_ACC : 22|3@0+ (1,0) [0|7] "" GW
 SG_ ADAS_TakeOverReq_ACC : 23|1@0+ (1,0) [0|1] "" GW
 SG_ ADAS_DispSpd_ACC : 31|8@0+ (1,0) [0|255] "" GW
 SG_ ADAS_Sts_ACC_ICC : 35|4@0+ (1,0) [0|15] "" GW
 SG_ ADAS_SpdLimUnit_ASL : 39|2@0+ (1,0) [0|3] "" GW
 SG_ ADAS_SpdLim_ASL : 47|8@0+ (1,0) [0|255] "" GW
 SG_ ADAS_SpdLimSts_ASL : 50|3@0+ (1,0) [0|7] "" MPC,GW

BO_ 842 ADAS_0x34A: 8 ADAS
 SG_ ADAS_Sts_HWA : 2|3@0+ (1,0) [0|7] "" GW
 SG_ ADAS_HiwayExitAuxSts : 5|3@0+ (1,0) [0|7] "" GW
 SG_ ADAS_ActvBtnDispReq_HEA : 7|2@0+ (1,0) [0|3] "" GW
 SG_ ADAS_Sts_ALC : 11|4@0+ (1,0) [0|15] "" CMRR_RR,GW
 SG_ ADAS_HandsOffTakeOverReq_ALC : 15|1@0+ (1,0) [0|1] "" GW
 SG_ ADAS_OverMod_ALC : 16|1@0+ (1,0) [0|1] "" GW
 SG_ ADAS_ALCAudioWarnLe : 17|1@0+ (1,0) [0|1] "" GW
 SG_ ADAS_LCReturnToLane : 19|2@0+ (1,0) [0|3] "" GW
 SG_ ADAS_LeLaneOccupied : 20|1@0+ (1,0) [0|1] "" GW
 SG_ ADAS_RiLaneOccupied : 21|1@0+ (1,0) [0|1] "" GW
 SG_ ADAS_LeLCArrow : 23|2@0+ (1,0) [0|3] "" GW
 SG_ ADAS_ALCAudioWarnRi : 24|1@0+ (1,0) [0|1] "" GW
 SG_ ADAS_LeLaneOccupiedWarn : 25|1@0+ (1,0) [0|1] "" GW
 SG_ ADAS_RiLaneOccupiedWarn : 26|1@0+ (1,0) [0|1] "" GW
 SG_ ADAS_ALCTakeOverReq : 27|1@0+ (1,0) [0|1] "" GW
 SG_ ADAS_LCSysFlt : 28|1@0+ (1,0) [0|1] "" GW
 SG_ ADAS_TurnLampOff : 30|2@0+ (1,0) [0|3] "" GW
 SG_ ADAS_CtrlrFlt : 41|2@0+ (1,0) [0|3] "" MPC,CMRR_RL,CMRR_RR,CMRR_FL,CMRR_FR,MRR,GW
 SG_ ADAS_RiLCArrow : 49|2@0+ (1,0) [0|3] "" GW
 SG_ ADAS_Sts_ESS : 52|3@0+ (1,0) [0|7] "" GW
 SG_ ADAS_Warn_ESS : 54|2@0+ (1,0) [0|3] "" GW
 SG_ ADAS_DrvrOccpyReq : 55|1@0+ (1,0) [0|1] "" GW

BO_ 820 MPC_0x334: 8 MPC
 SG_ MPC_FrntCamBli : 23|2@0+ (1,0) [0|3] "" ADAS,MRR_L,MRR_M,MRR,GW
 SG_ MPC_FrntCamFlt : 31|2@0+ (1,0) [0|3] "" ADAS,MRR_L,MRR_M,MRR,GW

BO_ 832 MRR_0x340: 8 ADAS
 SG_ ADAS_LaneCrvt : 7|8@0+ (50,-3150) [-3150|3200] "m" GW
 SG_ ADAS_LeLineTyp : 9|2@0+ (1,0) [0|3] "" GW
 SG_ ADAS_RiLineTyp : 11|2@0+ (1,0) [0|3] "" GW
 SG_ ADAS_LeLineColor : 13|2@0+ (1,0) [0|3] "" GW
 SG_ ADAS_RiLineColor : 15|2@0+ (1,0) [0|3] "" GW
 SG_ ADAS_LeLineDst : 22|7@0+ (0.1,-6.2) [-6.2|6.2] "m" GW
 SG_ ADAS_RiLineDst : 30|7@0+ (0.1,-6.2) [-6.2|6.2] "m" GW
 SG_ ADAS_LeLineFlash : 33|2@0+ (1,0) [0|3] "" GW
 SG_ ADAS_RiLineFlash : 35|2@0+ (1,0) [0|3] "" GW
 SG_ ADAS_ESSSwtFb : 39|2@0+ (1,0) [0|3] "" GW
 SG_ ADAS_IntegtCrsSwtFb : 41|2@0+ (1,0) [0|3] "" GW
 SG_ ADAS_IntegtCrsModSetFb : 43|2@0+ (1,0) [0|3] "" GW
 SG_ ADAS_LaneSprtSwtFb : 45|2@0+ (1,0) [0|3] "" GW
 SG_ ADAS_LaneSprtTypSetFb : 47|2@0+ (1,0) [0|3] "" GW
 SG_ ADAS_FCWFCTASwtFb : 49|2@0+ (1,0) [0|3] "" GW
 SG_ ADAS_AEBFCTBSwtFb : 51|2@0+ (1,0) [0|3] "" GW
 SG_ ADAS_FltIndcr : 53|2@0+ (1,0) [0|3] "" GW
 SG_ ADAS_VoiceSpdRglnFb : 55|2@0+ (1,0) [0|3] "" GW
 SG_ ADAS_IntegtCrsFltTxt : 56|1@0+ (1,0) [0|1] "" GW
 SG_ ADAS_LaneSprtFltTxt : 57|1@0+ (1,0) [0|1] "" GW
 SG_ ADAS_FwdWarnFltTxt : 58|1@0+ (1,0) [0|1] "" GW
 SG_ ADAS_IntecnFltTxt : 59|1@0+ (1,0) [0|1] "" GW
 SG_ ADAS_ACCIconDisp : 62|3@0+ (1,0) [0|7] "" GW

BO_ 824 CMRR_RL_0x338: 8 CMRR_RL
 SG_ CMRR_RL_LeWarn_LCA : 1|2@0+ (1,0) [0|3] "" ADAS,MRR_L,MRR_M,GW
 SG_ CMRR_RL_SnsrFlt : 25|2@0+ (1,0) [0|3] "" ADAS,MRR_M,CMRR_RR,GW
 SG_ CMRR_RL_SnsrBli : 27|2@0+ (1,0) [0|3] "" ADAS,MRR_M,CMRR_RR,GW
 SG_ CMRR_RL_LeWarn_LCA_ELK : 29|2@0+ (1,0) [0|3] "" ADAS,MRR_M,GW
 SG_ CMRR_RL_SDASts : 31|2@0+ (1,0) [0|3] "" ADAS,MRR_M,GW
 SG_ CMRR_RL_SDAWarn : 32|1@0+ (1,0) [0|1] "" ADAS,MRR_M,GW

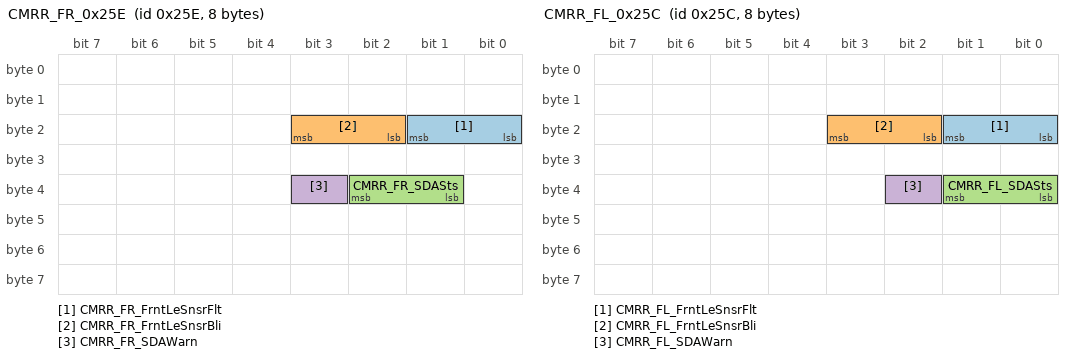
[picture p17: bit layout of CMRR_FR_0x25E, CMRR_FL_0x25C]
BO_ 606 CMRR_FR_0x25E: 8 CMRR_FR
 SG_ CMRR_FR_FrntLeSnsrFlt : 17|2@0+ (1,0) [0|3] "" ADAS,CMRR_FL,GW
 SG_ CMRR_FR_FrntLeSnsrBli : 19|2@0+ (1,0) [0|3] "" ADAS,CMRR_FL,GW
 SG_ CMRR_FR_SDASts : 34|2@0+ (1,0) [0|3] "" ADAS,GW
 SG_ CMRR_FR_SDAWarn : 35|1@0+ (1,0) [0|1] "" ADAS,GW

BO_ 604 CMRR_FL_0x25C: 8 CMRR_FL
 SG_ CMRR_FL_FrntLeSnsrFlt : 17|2@0+ (1,0) [0|3] "" ADAS,CMRR_FR,GW
 SG_ CMRR_FL_FrntLeSnsrBli : 19|2@0+ (1,0) [0|3] "" ADAS,CMRR_FR,GW
 SG_ CMRR_FL_SDASts : 33|2@0+ (1,0) [0|3] "" ADAS,GW
 SG_ CMRR_FL_SDAWarn : 34|1@0+ (1,0) [0|1] "" ADAS,GW

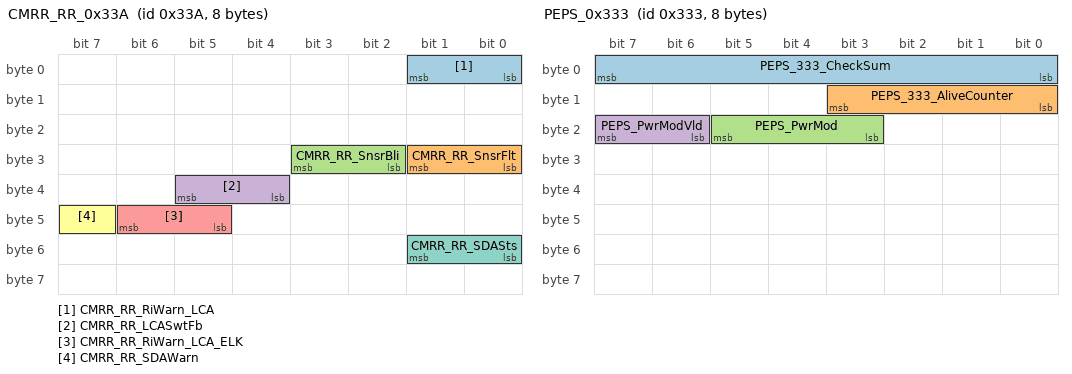
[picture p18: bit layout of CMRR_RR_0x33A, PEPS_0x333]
BO_ 826 CMRR_RR_0x33A: 8 CMRR_RR
 SG_ CMRR_RR_RiWarn_LCA : 1|2@0+ (1,0) [0|3] "" ADAS,MRR_L,MRR_M,GW
 SG_ CMRR_RR_SnsrFlt : 25|2@0+ (1,0) [0|3] "" ADAS,MRR_M,CMRR_RL,GW
 SG_ CMRR_RR_SnsrBli : 27|2@0+ (1,0) [0|3] "" ADAS,MRR_M,CMRR_RL,GW
 SG_ CMRR_RR_LCASwtFb : 37|2@0+ (1,0) [0|3] "" ADAS,MRR_M,CMRR_RL,GW
 SG_ CMRR_RR_RiWarn_LCA_ELK : 46|2@0+ (1,0) [0|3] "" ADAS,MRR_L,MRR_M,GW
 SG_ CMRR_RR_SDAWarn : 47|1@0+ (1,0) [0|1] "" ADAS,MRR_M,GW
 SG_ CMRR_RR_SDASts : 49|2@0+ (1,0) [0|3] "" ADAS,MRR_M,GW

BO_ 819 PEPS_0x333: 8 GW
 SG_ PEPS_333_CheckSum : 7|8@0+ (1,0) [0|255] "" ADAS,MRR_L,MRR_M,MPC,CMRR_RL,CMRR_RR,CMRR_FL,CMRR_FR,MRR,AVAP
 SG_ PEPS_333_AliveCounter : 11|4@0+ (1,0) [0|15] "" ADAS,MRR_L,MRR_M,MPC,CMRR_RL,CMRR_RR,CMRR_FL,CMRR_FR,MRR,AVAP
 SG_ PEPS_PwrMod : 21|3@0+ (1,0) [0|7] "" ADAS,MRR_L,MRR_M,MPC,CMRR_RL,CMRR_RR,CMRR_FL,CMRR_FR,MRR,AVAP
 SG_ PEPS_PwrModVld : 23|2@0+ (1,0) [0|3] "" ADAS,MRR_L,MRR_M,MPC,CMRR_RL,CMRR_RR,CMRR_FL,CMRR_FR,MRR,AVAP

BO_ 1417 TPMS_0x589: 8 GW
 SG_ TPMS_TirePosn : 2|3@0+ (1,0) [0|7] "" ADAS,MRR_L,MRR_M
 SG_ TPMS_SngTirePSts : 11|2@0+ (1,0) [0|3] "" ADAS,MRR_L,MRR_M

BO_ 1319 ICC_0x527: 8 GW
 SG_ EHU_DrvrSts : 42|3@0+ (1,0) [0|7] "" ADAS
 SG_ EHU_DrvrOccpy : 47|2@0+ (1,0) [0|3] "" ADAS,AVAP

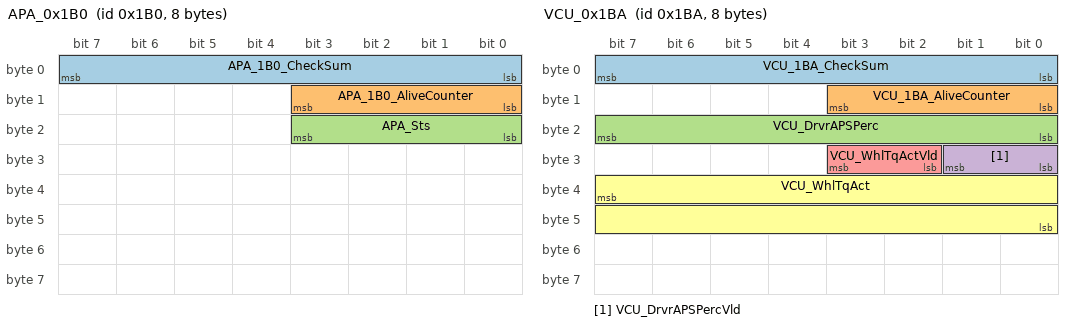
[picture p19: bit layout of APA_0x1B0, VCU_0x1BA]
BO_ 432 APA_0x1B0: 8 AVAP
 SG_ APA_1B0_CheckSum : 7|8@0+ (1,0) [0|255] "" ADAS,MRR_M,CMRR_RL,CMRR_RR,CMRR_FL,CMRR_FR,GW
 SG_ APA_1B0_AliveCounter : 11|4@0+ (1,0) [0|15] "" ADAS,MRR_M,CMRR_RL,CMRR_RR,CMRR_FL,CMRR_FR,GW
 SG_ APA_Sts : 19|4@0+ (1,0) [0|15] "" ADAS,MRR_M,CMRR_RL,CMRR_RR,CMRR_FL,CMRR_FR,GW

BO_ 658 APA_0x292: 8 AVAP
 SG_ APA_292_CheckSum : 7|8@0+ (1,0) [0|255] "" ADAS,MRR_M,CMRR_RL,CMRR_RR,CMRR_FL,CMRR_FR,GW
 SG_ APA_292_AliveCounter : 11|4@0+ (1,0) [0|15] "" ADAS,MRR_M,CMRR_RL,CMRR_RR,CMRR_FL,CMRR_FR,GW
 SG_ APA_CrtPrkgTyp : 41|2@0+ (1,0) [0|3] "" ADAS,MRR_M,CMRR_RL,CMRR_RR,CMRR_FL,CMRR_FR,GW

BO_ 1368 APA_0x558: 8 AVAP
 SG_ APA_558_CheckSum : 7|8@0+ (1,0) [0|255] "" ADAS,MRR_M,CMRR_RL,CMRR_RR,CMRR_FL,CMRR_FR,GW
 SG_ APA_558_AliveCounter : 11|4@0+ (1,0) [0|15] "" ADAS,MRR_M,CMRR_RL,CMRR_RR,CMRR_FL,CMRR_FR,GW
 SG_ APA_Sts_PAS : 35|2@0+ (1,0) [0|3] "" ADAS,MRR_M,CMRR_RL,CMRR_RR,CMRR_FL,CMRR_FR,GW

BO_ 672 APA_0x2A0: 8 AVAP
 SG_ APA_FMEBSts : 47|4@0+ (1,0) [0|15] "" ADAS,CMRR_RL,CMRR_RR,CMRR_FL,CMRR_FR,GW
 SG_ APA_RMEBSts : 53|4@0+ (1,0) [0|15] "" ADAS,MRR_M,CMRR_RL,CMRR_RR,CMRR_FL,CMRR_FR,GW

BO_ 1300 MFS_0x514: 8 GW
 SG_ MFS_LeRollPress : 15|2@0+ (1,0) [0|3] "" ADAS,MRR_L,MRR_M
 SG_ MFS_RiRollPress : 31|2@0+ (1,0) [0|3] "" ADAS,MRR_L,MRR_M

BO_ 592 ICC_0x250: 8 GW
 SG_ EHU_SegFuncRoadClass : 34|3@0+ (1,0) [0|7] "" ADAS,MPC
 SG_ EHU_SegEffSpdLmtType : 50|3@0+ (1,0) [0|7] "" ADAS,MPC

BO_ 593 ICC_0x251: 8 GW
 SG_ EHU_StubFuncRoadClass : 34|3@0+ (1,0) [0|7] "" ADAS,MPC
 SG_ EHU_StubTurnAngl : 55|8@0+ (1.417,0) [0|358] "degrees" ADAS,MPC

BO_ 442 VCU_0x1BA: 8 GW
 SG_ VCU_1BA_CheckSum : 7|8@0+ (1,0) [0|255] "" ADAS,MRR_L,MRR_M,CMRR_RL,CMRR_RR,CMRR_FL,CMRR_FR,MRR,AVAP
 SG_ VCU_1BA_AliveCounter : 11|4@0+ (1,0) [0|15] "" ADAS,MRR_L,MRR_M,CMRR_RL,CMRR_RR,CMRR_FL,CMRR_FR,MRR,AVAP
 SG_ VCU_DrvrAPSPerc : 23|8@0+ (0.4,0) [0|100] "%" ADAS,MRR_L,MRR_M,CMRR_RL,CMRR_RR,CMRR_FL,CMRR_FR,MRR,AVAP
 SG_ VCU_DrvrAPSPercVld : 25|2@0+ (1,0) [0|3] "" ADAS,MRR_L,MRR_M,CMRR_RL,CMRR_RR,CMRR_FL,CMRR_FR,MRR,AVAP
 SG_ VCU_WhlTqActVld : 27|2@0+ (1,0) [0|3] "" ADAS,MRR_L,MRR_M
 SG_ VCU_WhlTqAct : 39|16@0+ (1,-32768) [-32768|32767] "N·m" ADAS,MRR_L,MRR_M

BO_ 440 ESP_0x1B8: 8 GW
 SG_ ESP_RoadSlop : 50|11@0+ (0.01,-10) [-10|10] "m/s2" ADAS,MRR_L,MRR_M,MRR,AVAP

BO_ 1625 ADAS_0x659: 8 ADAS
 SG_ ADAS_SwVersS : 15|8@0+ (1,0) [0|255] "" GW
 SG_ ADAS_PartVers : 23|32@0+ (1,0) [0|4294967295] "" GW
 SG_ ADAS_HwVers : 55|8@0+ (1,0) [0|255] "" GW
 SG_ ADAS_SwVersM : 63|8@0+ (1,0) [0|255] "" GW

BO_ 1153 ADAS_0x481: 8 ADAS
 SG_ ADAS_ECUUnexpectedRst : 0|1@0+ (1,0) [0|1] "" GW
 SG_ ADAS_ChkBattVoltFlt : 1|1@0+ (1,0) [0|1] "" GW
 SG_ ADAS_1V25UnderOrOverVolt : 2|1@0+ (1,0) [0|1] "" GW
 SG_ ADAS_3V3UnderOrOverVolt : 3|1@0+ (1,0) [0|1] "" GW
 SG_ ADAS_5V0UnderOrOverVolt : 4|1@0+ (1,0) [0|1] "" GW
 SG_ ADAS_BusHwErr : 5|1@0+ (1,0) [0|1] "" GW
 SG_ ADAS_BusHwErr_MPC : 6|1@0+ (1,0) [0|1] "" GW
 SG_ ADAS_BusHwErr_MRR : 7|1@0+ (1,0) [0|1] "" GW
 SG_ ADAS_BusHwErr_CMRR_FL : 8|1@0+ (1,0) [0|1] "" GW
 SG_ ADAS_BusDiagHwErr_CMRR_FR : 9|1@0+ (1,0) [0|1] "" GW
 SG_ ADAS_ChkInvldSig_MPC : 10|1@0+ (1,0) [0|1] "" GW
 SG_ ADAS_ChkInvldSig_CMRR_RL : 11|1@0+ (1,0) [0|1] "" GW
 SG_ ADAS_ChkInvldSig_CMRR_FR : 12|1@0+ (1,0) [0|1] "" GW
 SG_ ADAS_ChkInvldSig_CMRR_FL : 13|1@0+ (1,0) [0|1] "" GW
 SG_ ADAS_ChkInvldSig_CMRR_RR : 14|1@0+ (1,0) [0|1] "" GW
 SG_ ADAS_ChkInvldSig_MRR : 15|1@0+ (1,0) [0|1] "" GW
 SG_ ADAS_ChkInvldSig_ESP : 16|1@0+ (1,0) [0|1] "" GW
 SG_ ADAS_ChkInvldSig_SDM : 17|1@0+ (1,0) [0|1] "" GW
 SG_ ADAS_ChkInvldSig_EPS : 18|1@0+ (1,0) [0|1] "" GW
 SG_ ADAS_ChkInvldSig_iBooster : 19|1@0+ (1,0) [0|1] "" GW
 SG_ ADAS_ChkInvldSig_YRS : 20|1@0+ (1,0) [0|1] "" GW
 SG_ ADAS_ChkInvldSig_BCM : 21|1@0+ (1,0) [0|1] "" GW
 SG_ ADAS_ChkInvldSig_ECC : 22|1@0+ (1,0) [0|1] "" GW
 SG_ ADAS_ChkInvldSig_TBOX : 23|1@0+ (1,0) [0|1] "" GW
 SG_ ADAS_ChkInvldSig_MCU_F : 24|1@0+ (1,0) [0|1] "" GW
 SG_ ADAS_ChkInvldSig_MCU_R : 25|1@0+ (1,0) [0|1] "" GW
 SG_ ADAS_ChkInvldSig_PLG : 26|1@0+ (1,0) [0|1] "" GW
 SG_ ADAS_ChkInvldSig_CIM : 27|1@0+ (1,0) [0|1] "" GW
 SG_ ADAS_ChkInvldSig_VCU : 28|1@0+ (1,0) [0|1] "" GW
 SG_ ADAS_ChkInvldSig_ICC : 29|1@0+ (1,0) [0|1] "" GW
 SG_ ADAS_ChkInvldSig_PEPS : 30|1@0+ (1,0) [0|1] "" GW
 SG_ ADAS_ChkInvldSig_TPMS : 31|1@0+ (1,0) [0|1] "" GW
 SG_ ADAS_ChkInvldSig_AVAP : 32|1@0+ (1,0) [0|1] "" GW
 SG_ ADAS_ComE2EFlt : 33|1@0+ (1,0) [0|1] "" GW
 SG_ ADAS_ComLostFlt_MPC : 34|1@0+ (1,0) [0|1] "" GW
 SG_ ADAS_ComLostFlt_CMRR_RL : 35|1@0+ (1,0) [0|1] "" GW
 SG_ ADAS_ComLostFlt_CMRR_FL : 36|1@0+ (1,0) [0|1] "" GW
 SG_ ADAS_ComLostFlt_CMRR_RR : 37|1@0+ (1,0) [0|1] "" GW
 SG_ ADAS_ComLostFlt_CMRR_FR : 38|1@0+ (1,0) [0|1] "" GW
 SG_ ADAS_ComLostFlt_MRR : 39|1@0+ (1,0) [0|1] "" GW
 SG_ ADAS_ComLostFlt_ESP : 40|1@0+ (1,0) [0|1] "" GW
 SG_ ADAS_ComLostFlt_SDM : 41|1@0+ (1,0) [0|1] "" GW
 SG_ ADAS_ComLostFlt_EPS : 42|1@0+ (1,0) [0|1] "" GW
 SG_ ADAS_ComLostFlt_iBooster : 43|1@0+ (1,0) [0|1] "" GW
 SG_ ADAS_ComLostFlt_YRS : 44|1@0+ (1,0) [0|1] "" GW
 SG_ ADAS_ComLostFlt_BCM : 45|1@0+ (1,0) [0|1] "" GW
 SG_ ADAS_ComLostFlt_ECC : 46|1@0+ (1,0) [0|1] "" GW
 SG_ ADAS_ComLostFlt_TBOX : 47|1@0+ (1,0) [0|1] "" GW
 SG_ ADAS_ComLostFlt_MCU_F : 48|1@0+ (1,0) [0|1] "" GW
 SG_ ADAS_ComLostFlt_MCU_R : 49|1@0+ (1,0) [0|1] "" GW
 SG_ ADAS_ComLostFlt_PLG : 50|1@0+ (1,0) [0|1] "" GW
 SG_ ADAS_ComLostFlt_CIM : 51|1@0+ (1,0) [0|1] "" GW
 SG_ ADAS_ComLostFlt_VCU : 52|1@0+ (1,0) [0|1] "" GW
 SG_ ADAS_ComLostFlt_ICC : 53|1@0+ (1,0) [0|1] "" GW
 SG_ ADAS_ComLostFlt_PEPS : 54|1@0+ (1,0) [0|1] "" GW
 SG_ ADAS_ComLostFlt_TPMS : 55|1@0+ (1,0) [0|1] "" GW
 SG_ ADAS_ComLostFlt_AVAP : 56|1@0+ (1,0) [0|1] "" GW
 SG_ ADAS_ChkPublicCANBusOff : 57|1@0+ (1,0) [0|1] "" GW
 SG_ ADAS_MstRAMTestErr : 58|1@0+ (1,0) [0|1] "" GW
 SG_ ADAS_MstNVRAMTestErr : 59|1@0+ (1,0) [0|1] "" GW
 SG_ ADAS_NVMChipErr : 60|1@0+ (1,0) [0|1] "" GW
 SG_ ADAS_NVMStructErr : 61|1@0+ (1,0) [0|1] "" GW
 SG_ ADAS_MstWdgErr : 62|1@0+ (1,0) [0|1] "" GW
 SG_ ADAS_MstSOPTErr : 63|1@0+ (1,0) [0|1] "" GW

BO_ 1154 ADAS_0x482: 8 ADAS
 SG_ ADAS_MstHwstartupErr : 0|1@0+ (1,0) [0|1] "" GW
 SG_ ADAS_MstHwCycTest : 1|1@0+ (1,0) [0|1] "" GW
 SG_ ADAS_EOLCalOutOfRng : 2|1@0+ (1,0) [0|1] "" GW
 SG_ ADAS_ECUTFlt : 3|1@0+ (1,0) [0|1] "" GW
 SG_ ADAS_PwrModFlt : 4|1@0+ (1,0) [0|1] "" GW
 SG_ ADAS_ComLostFlt_MFS : 5|1@0+ (1,0) [0|1] "" GW
 SG_ ADAS_PrivateCANComE2EFlt_MPC : 6|1@0+ (1,0) [0|1] "" GW
 SG_ ADAS_PrivateCANComE2EFlt_MRR : 7|1@0+ (1,0) [0|1] "" GW
 SG_ ADAS_PrivateCANComE2EFlt_CMRR_FL : 8|1@0+ (1,0) [0|1] "" GW
 SG_ ADAS_PrivateCANComE2EFlt_CMRR_FR : 9|1@0+ (1,0) [0|1] "" GW
 SG_ ADAS_PrivateCANComE2EFlt_CMRR_RL : 10|1@0+ (1,0) [0|1] "" GW
 SG_ ADAS_PrivateCANComE2EFlt_CMRR_RR : 11|1@0+ (1,0) [0|1] "" GW
 SG_ ADAS_PrivateCANComLostFlt_MPC : 12|1@0+ (1,0) [0|1] "" GW
 SG_ ADAS_PrivateCANComLostFlt_MRR : 13|1@0+ (1,0) [0|1] "" GW
 SG_ ADAS_PrivateCANComLost_CMRR_FL : 14|1@0+ (1,0) [0|1] "" GW
 SG_ ADAS_PrivateCANComLost_CMRR_FR : 15|1@0+ (1,0) [0|1] "" GW
 SG_ ADAS_PrivateCANComLost_CMRR_RL : 16|1@0+ (1,0) [0|1] "" GW
 SG_ ADAS_PrivateCANComLost_CMRR_RR : 17|1@0+ (1,0) [0|1] "" GW
 SG_ ADAS_PERChkIntFltInfo : 18|1@0+ (1,0) [0|1] "" GW
 SG_ ADAS_HWAActvFlg : 19|1@0+ (1,0) [0|1] "" GW
 SG_ ADAS_HWASucFlg : 20|1@0+ (1,0) [0|1] "" GW

BO_ 1162 ADAS_0x48A: 8 ADAS
 SG_ ADAS_RDPActvFlg : 0|1@0+ (1,0) [0|1] "" GW
 SG_ ADAS_ELKActvFlg : 1|1@0+ (1,0) [0|1] "" GW

BO_ 1966 Diag_ADAS_Resp: 64 ADAS

BO_ 1958 Diag_ADAS_Req: 64 GW

BO_ 2015 Diag_FUN_Req: 8 GW

BO_TX_BU_ 596 : ADAS,MRR_L,MRR_M;

BO_TX_BU_ 448 : ADAS,MRR_L,MRR_M;

BO_TX_BU_ 812 : ADAS,MRR_L,MRR_M;

BO_TX_BU_ 828 : ADAS,MRR_L,MRR_M;

BO_TX_BU_ 830 : MRR_L,MRR_M,MRR;

BO_TX_BU_ 838 : ADAS,MRR_L,MRR_M;

BO_TX_BU_ 839 : ADAS,MRR_L,MRR_M;

BO_TX_BU_ 832 : ADAS,MRR_L,MRR_M;

BO_TX_BU_ 1162 : ADAS,MRR_L,MRR_M;

CM_ "Version:V1.0,Date:2019/4/25,Author:李国萌,Review:,Approval:,Description:(ADAS)基于《BJEV_N60AB(EP1-3)_ADASBUS_Matrix_CANFD_V3.2_20190315》，编制EP2阶段初版协议。;
Version:V1.0,Date:2019/4/25,Author:李国萌,Review:,Approval:,Description:(ADAS)MRR增加发送报文MRR_0x259；ADAS取消发送报文MRR_0x259。（变更来源：201900403闫石OA变更单）;
Version:V1.0,Date:2019/4/25,Author:李国萌,Review:,Approval:,Description:(ADAS)CMRR_FR_0x34E,周期由50ms改为20ms，ID改为25E
CMRR_FL_0x34C,周期由50ms改为20ms，ID改为25C。
(变更来源：201900403闫石OA变更单）;
Version:V1.0,Date:2019/4/25,Author:李国萌,Review:,Approval:,Description:(ADAS)ADAS_0x34A，删除信号“ADAS_DrvrSuppressionLC  驾驶员主动抑制变道功能(观测)”。(变更来源：201900403闫石OA变更单）;
Version:V1.0,Date:2019/4/25,Author:李国萌,Review:,Approval:,Description:(ADAS)ICC_0x84、ICC_0x85、ICC_0x88、ICC_0x89由事件型报文改为周期型报文，周期20ms，ID依次更新为ICC_0x250、ICC_0x251、ICC_0x252、ICC_0x253。(变更来源：201900329杨凯OA变更单）;
Version:V1.0,Date:2019/4/25,Author:李国萌,Review:,Approval:,Description:(ADAS)新增信号接收BCM_0x335的“BCM_LeTrunLampOutpCmd  左转向灯输出命令”、“BCM_RiTrunLampOutpCmd 右转向灯输出命令”。(变更来源：201900403闫石OA变更单）;
Version:V1.0,Date:2019/4/25,Author:李国萌,Review:,Approval:,Description:(ADAS)ESP_0x122，“ESP_VmcVseSasOffset  方向盘转角偏移量”信号值描述删除“0x3CF0~0xFFFE:Reserved”。(变更来源：201900403闫石OA变更单）;
Version:V1.1,Date:2019/5/20,Author:李国萌,Review:,Approval:,Description:(ADAS)MFS_0x82，方向盘开关信号中英文信号名更新。（变更来源：20190422杨凯OA变更单）;
Version:V1.1,Date:2019/5/20,Author:李国萌,Review:,Approval:,Description:(ADAS)ICC_0x251,信号英文名称更新。（变更来源：20190422杨凯OA变更单）;
Version:V1.1,Date:2019/5/20,Author:李国萌,Review:,Approval:,Description:(ADAS)ICC_0x250,信号英文名称更新。（变更来源：20190422杨凯OA变更单）;
Version:V1.1,Date:2019/5/20,Author:李国萌,Review:,Approval:,Description:(ADAS)MRR_0x340，“ADAS_FltIndcr ADAS故障灯指示 ”信号值描述更新。（变更来源：20190423杨凯OA变更单）;
Version:V1.1,Date:2019/5/20,Author:李国萌,Review:,Approval:,Description:(ADAS)MFS_0x82，事件型报文改为周期型，ID改为514该帧报文方向盘开关信号中英文信号名称及信号值描述更新。（变更来源：20180525郑国臣OA变更单;
Version:V1.1,Date:2019/6/29,Author:李国萌,Review:,Approval:,Description:(ADAS)MFS_0x514,'左侧滚轮(按下)'、“右侧滚轮(按下)”信号值描述更新；“右侧滚轮(下滚)”英文信号名更新。（变更来源：20190629杨凯邮箱反馈）;
Version:V1.2,Date:2019/8/1,Author:李国萌,Review:,Approval:,Description:(ADAS)CMRR_FL_0x25C,新增信号“CMRR_FL_SDASts  SDA状态”、“CMRR_FL_SDAWarn   SDA报警”，ADAS收。(变更来源：20190701鲁卫申OA变更单);
Version:V1.2,Date:2019/8/1,Author:李国萌,Review:,Approval:,Description:(ADAS)CMRR_FR_0x25E,新增信号“CMRR_FR_SDASts  SDA状态”、“CMRR_FR_SDAWarn   SDA报警”，ADAS收。(变更来源：20190701鲁卫申OA变更单);
Version:V1.2,Date:2019/8/1,Author:李国萌,Review:,Approval:,Description:(ADAS)CMRR_RL_0x338,新增信号“CMRR_RL_SDASts  SDA状态”、“CMRR_RL_SDAWarn   SDA报警”，ADAS,MRR_M收。(变更来源：20190701鲁卫申OA变更单);
Version:V1.2,Date:2019/8/1,Author:李国萌,Review:,Approval:,Description:(ADAS)CMRR_RR_0x33A,新增信号“CMRR_RR_SDASts  SDA状态”、“CMRR_RR_SDAWarn   SDA报警”，ADAS,MRR_M收。(变更来源：20190701鲁卫申OA变更单);
Version:V1.2,Date:2019/8/1,Author:李国萌,Review:,Approval:,Description:(ADAS)MRR_0x32C“ELK-oc状态(观测量)”、“ELK-ot状态(观测量)”、“ELK-re 状态(观测量)”、“LDW状态(观测量)”、“RDP状态(观测量)”信号值描述更新。(变更来源：20190701鲁卫申OA变更单);
Version:V2.0,Date:2019/11/15,Author:李国萌,Review:,Approval:,Description:(ADAS)修正版本信息报文主次软件版本号信号英文名称。;
Version:V2.0,Date:2019/11/15,Author:李国萌,Review:,Approval:,Description:(ADAS)VCU_0x214“VCU_DrvModSig  驾驶模式信号”信号值描述更新。
（变更来源：20191110邓立军OA变更单）;
Version:V2.0,Date:2019/11/15,Author:李国萌,Review:,Approval:,Description:(ADAS)ADAS_0x34A的“ADAS_Sts_ALC ALC状态”信号值描述更新。
（变更来源：20191106刘炳炳OA变更单）;
Version:V2.0,Date:2019/11/15,Author:李国萌,Review:,Approval:,Description:(ADAS)MRR_0x347的“ADAS_FrntTar1Typ_ACC ACC前目标1类型 ”、“ADAS_FrntTar2Typ_ACC ACC前目标2类型 ”、“ADAS_LeFrntTarTyp_ACC  ACC左前目标类型”、“ADAS_RiFrntTarTyp_ACC  ACC右前目标类型”信号值描述更新。
（变更来源：20191106刘炳炳OA变更单）;
Version:V2.0,Date:2019/11/15,Author:李国萌,Review:,Approval:,Description:(ADAS)ICC_0x250“EHU_SegFuncRoadClass ”信号值描述更新。
（变更来源：20191106刘炳炳OA变更单）;
Version:V2.0,Date:2019/11/15,Author:李国萌,Review:,Approval:,Description:(ADAS)ICC_0x526“EHU_VoiceSpdRgln_ADAS 语音设置ACC车速 ”初始值由0x0改为0xFF。
（变更来源:20191122杨凯OA变更单）;
Version:V2.1,Date:2019/12/21,Author:李国萌,Review:,Approval:,Description:(ADAS)修正7DF诊断报文长度。;
Version:V2.1,Date:2020/2/28,Author:李国萌,Review:,Approval:,Description:(ADAS)增加诊断报文长度信号解释;
Version:V2.1,Date:2020/2/28,Author:李国萌,Review:,Approval:,Description:(ADAS)ICC_0x527“驾驶员状态”信号值描述、初始值无效值更新；'驾驶员座椅坐人确认(预留)'初始值无效值更新。
（变更来源:20200218杨凯OA变更单）;
Version:V2.1,Date:2020/2/28,Author:李国萌,Review:,Approval:,Description:(ADAS)ICC_0x336“速度限值偏差(预留)”初始值无效值更新。
（变更来源:20200218杨凯OA变更单）;
Version:V2.1,Date:2020/2/28,Author:李国萌,Review:,Approval:,Description:(ADAS)ICC_0x526'报警类型(LDW)请求'信号值描述0x3变更。
（变更来源:20200218杨凯OA变更单）;
Version:V2.1,Date:2020/2/28,Author:李国萌,Review:,Approval:,Description:(ADAS)MRR_0x32C'车道辅助警示类型'信号值描述0x3变更。
（变更来源:20200218杨凯OA变更单）;
Version:V2.2,Date:2020/4/20,Author:李国萌,Review:,Approval:,Description:(ADAS)VCU_0x214“VCU_DrvModSig 驾驶模式信号”信号值描述更新。
（变更来源:20200415邓立军OA变更单）;
Version:V2.3,Date:2020/5/28,Author:李国萌,Review:,Approval:,Description:(ADAS)新增AVAP_0x480、ADAS_0x481、ADAS_0x482、CMRR_FL_0x483、CMRR_FR_0x484、CMRR_RL_0x485、CMRR_RR_0x486、MPC_0x487、MRR_0x488、MRR_0x489、ADAS_0x48A；
（变更来源:20200516卢兰琦OA变更单）;
Version:V2.3,Date:2020/5/28,Author:李国萌,Review:,Approval:,Description:(ADAS)ICC_0x361、ICC_0x362、ICC_0x250、ICC_0x251、ICC_0x252初始值更新；
（变更来源:20200516卢兰琦OA变更单）;
Version:V2.3,Date:2020/5/28,Author:李国萌,Review:,Approval:,Description:(ADAS)“EHU_SegEffSpdLmtType  segment有效限速类型信息”、“EHU_StubFuncRoadClass”、“EHU_ProfLongProfType”、“ICC_0x253_ProfShortProfType”信号值描述更新。
（变更来源:20200516卢兰琦OA变更单）;
 ";

CM_ BO_ 1966 "矩阵中诊断报文的DLC仅用于适配DBC文件的生成，ECU实际开发采用的DLC长度应满足UDS技术要求。";
CM_ BO_ 1958 "矩阵中诊断报文的DLC仅用于适配DBC文件的生成，ECU实际开发采用的DLC长度应满足UDS技术要求。";
CM_ SG_ 596 ADAS_254_CheckSum "ADAS_254_报文校验和(0x48)ADAS_254_CheckSum";
CM_ SG_ 596 ADAS_254_AliveCounter "ADAS_254_报文计数器ADAS_254_AliveCounter";
CM_ SG_ 596 ADAS_TqReq_ACC "ACC扭矩请求";
CM_ SG_ 596 ADAS_Sts_ACC "ACC状态";
CM_ SG_ 596 ADAS_WhlTq_ACC "ACC轮端扭矩";
CM_ SG_ 596 ADAS_TarA_ACC "ACC目标减速度";
CM_ SG_ 596 ADAS_DecelToStopReq_ACC "ACC减速至停止请求ACC request the VLC to decelerate to stop.";
CM_ SG_ 596 ADAS_TarAReq_ACC "ACC目标减速度请求";
CM_ SG_ 596 ADAS_DrvOffReq_ACC "ACC起步请求ACC request the VLC to drive off.";
CM_ SG_ 448 ADAS_1C0_CheckSum "ADAS_1C0_报文校验和(0xC3)ADAS_1C0_CheckSum";
CM_ SG_ 448 ADAS_1C0_AliveCounter "ADAS_1C0_报文计数器ADAS_1C0_AliveCounter";
CM_ SG_ 448 ADAS_LatMtnCtrlSts "ADAS横向控制请求位";
CM_ SG_ 448 ADAS_SteerTqReq "ADAS转向力矩请求";
CM_ SG_ 448 ADAS_WarnVbrnReq "ADAS振动报警请求";
CM_ SG_ 448 ADAS_LatMtnTypExed "ADAS横向控制请求(Reserved)";
CM_ SG_ 448 ADAS_LeTrunLampReq "左转向灯请求";
CM_ SG_ 448 ADAS_RiTrunLampReq "右转向灯请求";
CM_ SG_ 812 ADAS_Sts_LKA "LKA状态(观测量)";
CM_ SG_ 812 ADAS_Sts_TJAICA "TJAICA状态";
CM_ SG_ 812 ADAS_FCWSnvty "FCW灵敏度";
CM_ SG_ 812 ADAS_ADASSnvtySetFb "ADAS灵敏度设置反馈";
CM_ SG_ 812 ADAS_SysWarnTyp "车道辅助警示类型";
CM_ SG_ 812 ADAS_Sts_ELK_re "ELK-re 状态(观测量)";
CM_ SG_ 812 ADAS_HandsOffTakeOverReq "横向功能接管请求";
CM_ SG_ 812 ADAS_IntvMod_ELK "ELK干预模式";
CM_ SG_ 812 ADAS_IntvDir_ELK "ELK干预方向";
CM_ SG_ 812 ADAS_Sts_RDP "RDP状态(观测量)";
CM_ SG_ 812 ADAS_Sts_LDW "LDW状态(观测量)";
CM_ SG_ 812 ADAS_AudioWarn "ADAS声音报警";
CM_ SG_ 812 ADAS_LatMtnColor "横向控制显示颜色";
CM_ SG_ 812 ADAS_DispReq "ADAS界面显示请求";
CM_ SG_ 812 ADAS_Sts_ELK_oc "ELK-oc状态(观测量)";
CM_ SG_ 812 ADAS_Sts_ELK_ot "ELK-ot状态(观测量)";
CM_ SG_ 828 ADAS_Warn_FCW "FCW报警";
CM_ SG_ 828 ADAS_WarnTyp_FCWAEB "FCWAEB报警类型";
CM_ SG_ 828 ADAS_Sts_FCW "FCW状态";
CM_ SG_ 828 ADAS_Sts_AEB "AEB状态";
CM_ SG_ 838 ADAS_FrntTar1X_ACC "ACC前目标1坐标X自车与ACC正前方目标1或AEB目标的x方向距离";
CM_ SG_ 838 ADAS_FrntTar1Y_ACC "ACC前目标1坐标Y自车与ACC正前方目标1或AEB目标y方向距离";
CM_ SG_ 838 ADAS_FrntTar2X_ACC "ACC前目标2坐标X自车与ACC正前方目标2的x方向距离，目标2是目标1前面的目标";
CM_ SG_ 838 ADAS_FrntTar2Y_ACC "ACC前目标2坐标Y自车与ACC正前方目标2的y方向距离，目标2是目标1前面的目标";
CM_ SG_ 838 ADAS_LeFrntTarX_ACC "ACC左前目标坐标X自车与左前方的x方向上的距离";
CM_ SG_ 838 ADAS_LeFrntTarY_ACC "ACC左前目标坐标Y自车与左前方的y方向上的距离";
CM_ SG_ 838 ADAS_RiFrntTarX_ACC "ACC右前目标坐标X自车与右前方的x方向上的距离";
CM_ SG_ 838 ADAS_RiFrntTarY_ACC "ACC右前目标坐标Y自车与右前方的y方向上的距离";
CM_ SG_ 839 ADAS_FrntTar1Typ_ACC "ACC前目标1类型指示探测到正前方目标1的类型";
CM_ SG_ 839 ADAS_FrntTar2Typ_ACC "ACC前目标2类型指示探测到正前方目标2的类型";
CM_ SG_ 839 ADAS_DispSpdUnit_ACC "ACC显示速度单位";
CM_ SG_ 839 ADAS_LeFrntTarTyp_ACC "ACC左前目标类型指示探测到左前方目标的类型";
CM_ SG_ 839 ADAS_RiFrntTarTyp_ACC "ACC右前目标类型指示探测到右前方目标的类型";
CM_ SG_ 839 ADAS_OperTxt "ADAS操作文本提示";
CM_ SG_ 839 ADAS_TiGapSet_ACC "ACC时距设定N60AB定义为5档";
CM_ SG_ 839 ADAS_TakeOverReq_ACC "ACC接管请求";
CM_ SG_ 839 ADAS_DispSpd_ACC "ACC目标速度显示需仪表显示的ACC设定巡航车速，当驾驶员操作ACC进入active状态时，控制器选择仪表显示车速vSet为vSetDis。在ACC实际控制中，巡航车速为对应的实际车速。";
CM_ SG_ 839 ADAS_Sts_ACC_ICC "ACC状态_ICC";
CM_ SG_ 839 ADAS_SpdLimUnit_ASL "ASL智能限速单位";
CM_ SG_ 839 ADAS_SpdLim_ASL "ASL智能限速速度";
CM_ SG_ 839 ADAS_SpdLimSts_ASL "ASL智能限速状态";
CM_ SG_ 842 ADAS_Sts_HWA "HWA状态(观测量)";
CM_ SG_ 842 ADAS_HiwayExitAuxSts "高速公路出口辅助状态";
CM_ SG_ 842 ADAS_ActvBtnDispReq_HEA "HEA激活按钮显示请求";
CM_ SG_ 842 ADAS_Sts_ALC "ALC状态";
CM_ SG_ 842 ADAS_HandsOffTakeOverReq_ALC "ALC脱手接管请求(预留)";
CM_ SG_ 842 ADAS_OverMod_ALC "ALC超越模式(预留，ICC暂不处理)";
CM_ SG_ 842 ADAS_ALCAudioWarnLe "ADAS主动换道的声音警告左侧";
CM_ SG_ 842 ADAS_LCReturnToLane "目标车道被占用，变道回本车道";
CM_ SG_ 842 ADAS_LeLaneOccupied "ADAS主动换道左侧占用";
CM_ SG_ 842 ADAS_RiLaneOccupied "ADAS主动换道右侧占用";
CM_ SG_ 842 ADAS_LeLCArrow "左变道箭头";
CM_ SG_ 842 ADAS_ALCAudioWarnRi "ADAS主动换道的声音警告右侧";
CM_ SG_ 842 ADAS_LeLaneOccupiedWarn "左车道被占用，等待空闲再变道";
CM_ SG_ 842 ADAS_RiLaneOccupiedWarn "右车道被占用，等待空闲再变道";
CM_ SG_ 842 ADAS_ALCTakeOverReq "ALC请求驾驶员接管(预留，ICC暂不处理)";
CM_ SG_ 842 ADAS_LCSysFlt "变道过程中的系统故障(观测)";
CM_ SG_ 842 ADAS_TurnLampOff "关闭转向灯提示";
CM_ SG_ 842 ADAS_CtrlrFlt "ADAS控制器故障";
CM_ SG_ 842 ADAS_RiLCArrow "右变道箭头";
CM_ SG_ 842 ADAS_Sts_ESS "ESS状态(预留)";
CM_ SG_ 842 ADAS_Warn_ESS "ESS报警(预留)";
CM_ SG_ 842 ADAS_DrvrOccpyReq "ADAS请求DMC座椅做人检测(预留)";
CM_ SG_ 832 ADAS_LaneCrvt "车道曲率The radium of the ego cars lane.";
CM_ SG_ 832 ADAS_LeLineTyp "左车道线类型The type of the left line.";
CM_ SG_ 832 ADAS_RiLineTyp "右车道线类型The type of the Right line.";
CM_ SG_ 832 ADAS_LeLineColor "左车道线颜色The color of the left line.";
CM_ SG_ 832 ADAS_RiLineColor "右车道线颜色The color of the Right line.";
CM_ SG_ 832 ADAS_LeLineDst "自车到左车道线距离indicate the y distance between the leftline and the ego car center.";
CM_ SG_ 832 ADAS_RiLineDst "自车到右车道线距离indicate the y distance between the Rightline and the ego car center.";
CM_ SG_ 832 ADAS_LeLineFlash "左车道线闪烁";
CM_ SG_ 832 ADAS_RiLineFlash "右车道线闪烁";
CM_ SG_ 832 ADAS_ESSSwtFb "紧急转向辅助开关反馈(预留)";
CM_ SG_ 832 ADAS_IntegtCrsSwtFb "智能巡航系统开关反馈";
CM_ SG_ 832 ADAS_IntegtCrsModSetFb "智能巡航系统模式设置反馈";
CM_ SG_ 832 ADAS_LaneSprtSwtFb "车道辅助系统开关反馈";
CM_ SG_ 832 ADAS_LaneSprtTypSetFb "车道辅助类型设置反馈";
CM_ SG_ 832 ADAS_FCWFCTASwtFb "前碰撞预警开关反馈";
CM_ SG_ 832 ADAS_AEBFCTBSwtFb "自动紧急制动开关反馈";
CM_ SG_ 832 ADAS_FltIndcr "ADAS故障灯指示(MRR/ADAS接收所有功能的故障、硬件遮挡和故障、发出此信号)";
CM_ SG_ 832 ADAS_VoiceSpdRglnFb "语音车速设置反馈";
CM_ SG_ 832 ADAS_IntegtCrsFltTxt "智能巡航系统失效";
CM_ SG_ 832 ADAS_LaneSprtFltTxt "车道辅助系统失效";
CM_ SG_ 832 ADAS_FwdWarnFltTxt "前方预警保护系统失效";
CM_ SG_ 832 ADAS_IntecnFltTxt "相关系统故障，驾驶辅助系统失效";
CM_ SG_ 832 ADAS_ACCIconDisp "ACC图标颜色";
CM_ SG_ 1625 ADAS_SwVersS "ADAS次软件版本号后两位";
CM_ SG_ 1625 ADAS_PartVers "ADAS零部件号";
CM_ SG_ 1625 ADAS_HwVers "ADAS硬件版本号后两位";
CM_ SG_ 1625 ADAS_SwVersM "ADAS主软件版本号后两位";
CM_ SG_ 1153 ADAS_ECUUnexpectedRst "ADAS ECU意外复位_C12A005_E00";
CM_ SG_ 1153 ADAS_ChkBattVoltFlt "ADAS检蓄电池电压异常_U32201C_E00";
CM_ SG_ 1153 ADAS_1V25UnderOrOverVolt "ADAS 1V25欠压或过压故障_C12A116_E00";
CM_ SG_ 1153 ADAS_3V3UnderOrOverVolt "ADAS 3V3欠压或过压故障_C12A216_E00";
CM_ SG_ 1153 ADAS_5V0UnderOrOverVolt "ADAS 5V0欠压或过压故障_C12A316_E00";
CM_ SG_ 1153 ADAS_BusHwErr "ADASBUS总线硬件错误_C12A409_E00";
CM_ SG_ 1153 ADAS_BusHwErr_MPC "ADAS与MPC通信总线硬件错误_C12A509_E00";
CM_ SG_ 1153 ADAS_BusHwErr_MRR "ADAS与MRR通信总线硬件错误_C12A609_E00";
CM_ SG_ 1153 ADAS_BusHwErr_CMRR_FL "ADAS与CMRR-FL通信总线硬件错误_C12A709_E00";
CM_ SG_ 1153 ADAS_BusDiagHwErr_CMRR_FR "ADAS与CMRR-FR通信总线硬件错误_C12A809_E00";
CM_ SG_ 1153 ADAS_ChkInvldSig_MPC "ADAS检MPC信号无效_C12A986_E00";
CM_ SG_ 1153 ADAS_ChkInvldSig_CMRR_RL "ADAS检CMRR-RL信号无效_C12AA86_E00";
CM_ SG_ 1153 ADAS_ChkInvldSig_CMRR_FR "ADAS检CMRR-FR信号无效_C12AB86_E00";
CM_ SG_ 1153 ADAS_ChkInvldSig_CMRR_FL "ADAS检CMRR-FL信号无效_C12AC86_E00";
CM_ SG_ 1153 ADAS_ChkInvldSig_CMRR_RR "ADAS检CMRR-RR信号无效_C12AD86_E00";
CM_ SG_ 1153 ADAS_ChkInvldSig_MRR "ADAS检MRR信号无效_C12AE86_E00";
CM_ SG_ 1153 ADAS_ChkInvldSig_ESP "ADAS检ESP信号无效_C12AF86_E00";
CM_ SG_ 1153 ADAS_ChkInvldSig_SDM "ADAS检SDM信号无效_C12B086_E00";
CM_ SG_ 1153 ADAS_ChkInvldSig_EPS "ADAS检EPS信号无效_C12B186_E00";
CM_ SG_ 1153 ADAS_ChkInvldSig_iBooster "ADAS检iBooster信号无效_C12B286_E00";
CM_ SG_ 1153 ADAS_ChkInvldSig_YRS "ADAS检YRS信号无效_C12B386_E00";
CM_ SG_ 1153 ADAS_ChkInvldSig_BCM "ADAS检BCM信号无效_C12B486_E00";
CM_ SG_ 1153 ADAS_ChkInvldSig_ECC "ADAS检ECC信号无效_C12B586_E00";
CM_ SG_ 1153 ADAS_ChkInvldSig_TBOX "ADAS检TBOX信号无效_C12B686_E00";
CM_ SG_ 1153 ADAS_ChkInvldSig_MCU_F "ADAS检MCU_F信号无效_C12B786_E00";
CM_ SG_ 1153 ADAS_ChkInvldSig_MCU_R "ADAS检MCU_R信号无效_C12B886_E00";
CM_ SG_ 1153 ADAS_ChkInvldSig_PLG "ADAS检PLG信号无效_C12B986_E00";
CM_ SG_ 1153 ADAS_ChkInvldSig_CIM "ADAS检CIM信号无效_C12BA86_E00";
CM_ SG_ 1153 ADAS_ChkInvldSig_VCU "ADAS检VCU信号无效_C12BB86_E00";
CM_ SG_ 1153 ADAS_ChkInvldSig_ICC "ADAS检ICC信号无效_C12BC86_E00";
CM_ SG_ 1153 ADAS_ChkInvldSig_PEPS "ADAS检PEPS信号无效_C12BD86_E00";
CM_ SG_ 1153 ADAS_ChkInvldSig_TPMS "ADAS检TPMS信号无效_C12BE86_E00";
CM_ SG_ 1153 ADAS_ChkInvldSig_AVAP "ADAS检AVAP信号无效_C12BF86_E00";
CM_ SG_ 1153 ADAS_ComE2EFlt "ADAS通讯校验故障_C12A608_E00";
CM_ SG_ 1153 ADAS_ComLostFlt_MPC "ADAS与MPC通讯丢失故障_U322187_E00";
CM_ SG_ 1153 ADAS_ComLostFlt_CMRR_RL "ADAS与CMRR-RL通讯丢失故障_U322287_E00";
CM_ SG_ 1153 ADAS_ComLostFlt_CMRR_FL "ADAS与CMRR-FL通讯丢失故障_U322387_E00";
CM_ SG_ 1153 ADAS_ComLostFlt_CMRR_RR "ADAS与CMRR-RR通讯丢失故障_U322487_E00";
CM_ SG_ 1153 ADAS_ComLostFlt_CMRR_FR "ADAS与CMRR-FR通讯丢失故障_U322587_E00";
CM_ SG_ 1153 ADAS_ComLostFlt_MRR "ADAS与MRR通讯丢失故障_U322687_E00";
CM_ SG_ 1153 ADAS_ComLostFlt_ESP "ADAS与ESP通讯丢失故障_U322787_E00";
CM_ SG_ 1153 ADAS_ComLostFlt_SDM "ADAS与SDM通讯丢失故障_U322887_E00";
CM_ SG_ 1153 ADAS_ComLostFlt_EPS "ADAS与EPS通讯丢失故障_U322987_E00";
CM_ SG_ 1153 ADAS_ComLostFlt_iBooster "ADAS与iBooster通讯丢失故障_U322A87_E00";
CM_ SG_ 1153 ADAS_ComLostFlt_YRS "ADAS与YRS通讯丢失故障_U322B87_E00";
CM_ SG_ 1153 ADAS_ComLostFlt_BCM "ADAS与BCM通讯丢失故障_U322C87_E00";
CM_ SG_ 1153 ADAS_ComLostFlt_ECC "ADAS与ECC通讯丢失故障_U322D87_E00";
CM_ SG_ 1153 ADAS_ComLostFlt_TBOX "ADAS与TBOX通讯丢失故障_U322F87_E00";
CM_ SG_ 1153 ADAS_ComLostFlt_MCU_F "ADAS与MCU_F通讯丢失故障_U134087_E00";
CM_ SG_ 1153 ADAS_ComLostFlt_MCU_R "ADAS与MCU_R通讯丢失故障_U134187_E00";
CM_ SG_ 1153 ADAS_ComLostFlt_PLG "ADAS与PLG通讯丢失故障_U134287_E00";
CM_ SG_ 1153 ADAS_ComLostFlt_CIM "ADAS与CIM通讯丢失故障_U134387_E00";
CM_ SG_ 1153 ADAS_ComLostFlt_VCU "ADAS与VCU通讯丢失故障_U134487_E00";
CM_ SG_ 1153 ADAS_ComLostFlt_ICC "ADAS与ICC通讯丢失故障_U134587_E00";
CM_ SG_ 1153 ADAS_ComLostFlt_PEPS "ADAS与PEPS通讯丢失故障_U134687_E00";
CM_ SG_ 1153 ADAS_ComLostFlt_TPMS "ADAS与TPMS通讯丢失故障_U134787_E00";
CM_ SG_ 1153 ADAS_ComLostFlt_AVAP "ADAS与AVAP通讯丢失故障_U134887_E00";
CM_ SG_ 1153 ADAS_ChkPublicCANBusOff "ADAS检公CAN BUSOFF_U134988_E00";
CM_ SG_ 1153 ADAS_MstRAMTestErr "ADAS主控制器RAM测试错误_C12C042_E00";
CM_ SG_ 1153 ADAS_MstNVRAMTestErr "ADAS主控制器NVRAM测试错误_C12C043_E00";
CM_ SG_ 1153 ADAS_NVMChipErr "ADAS NVM芯片错误_C12C149_E00";
CM_ SG_ 1153 ADAS_NVMStructErr "ADAS NVM结构错误_C12C176_E00";
CM_ SG_ 1153 ADAS_MstWdgErr "ADAS主控制器看门狗错误_C12C247_E00";
CM_ SG_ 1153 ADAS_MstSOPTErr "ADAS主控制器SOPT错误_C12C204_E00";
CM_ SG_ 1154 ADAS_MstHwstartupErr "ADAS主控制器硬件启动错误_C12C249_E00";
CM_ SG_ 1154 ADAS_MstHwCycTest "ADAS主控制器硬件循环测试错误_C12C200_E00";
CM_ SG_ 1154 ADAS_EOLCalOutOfRng "ADAS EOL校准结果越界_C12C378_E00";
CM_ SG_ 1154 ADAS_ECUTFlt "ADAS ECU温度异常_C12C44B_E00";
CM_ SG_ 1154 ADAS_PwrModFlt "ADAS电源模式异常_C12C501_E00";
CM_ SG_ 1154 ADAS_ComLostFlt_MFS "ADAS与MFS通讯丢失故障_U134987_E00";
CM_ SG_ 1154 ADAS_PrivateCANComE2EFlt_MPC "ADAS检MPC私CAN通讯校验故障_U134A82_E00";
CM_ SG_ 1154 ADAS_PrivateCANComE2EFlt_MRR "ADAS检MRR私CAN通讯校验故障_U134B82_E00";
CM_ SG_ 1154 ADAS_PrivateCANComE2EFlt_CMRR_FL "ADAS检CMRR-FL私CAN通讯校验故障_U134C82_E00";
CM_ SG_ 1154 ADAS_PrivateCANComE2EFlt_CMRR_FR "ADAS检CMRR-FR私CAN通讯校验故障_U134D82_E00";
CM_ SG_ 1154 ADAS_PrivateCANComE2EFlt_CMRR_RL "ADAS检CMRR-RL私CAN通讯校验故障_U134F82_E00";
CM_ SG_ 1154 ADAS_PrivateCANComE2EFlt_CMRR_RR "ADAS检CMRR-RR私CAN通讯校验故障_U135082_E00";
CM_ SG_ 1154 ADAS_PrivateCANComLostFlt_MPC "ADAS与MPC私CAN通讯丢失_U134A87_E00";
CM_ SG_ 1154 ADAS_PrivateCANComLostFlt_MRR "ADAS与MRR私CAN通讯丢失_U134B87_E00";
CM_ SG_ 1154 ADAS_PrivateCANComLost_CMRR_FL "ADAS与CMRR-FL私CAN通讯丢失_U134C87_E00";
CM_ SG_ 1154 ADAS_PrivateCANComLost_CMRR_FR "ADAS与CMRR-FR私CAN通讯丢失_U134D87_E00";
CM_ SG_ 1154 ADAS_PrivateCANComLost_CMRR_RL "ADAS与CMRR-RL私CAN通讯丢失_U134E87_E00";
CM_ SG_ 1154 ADAS_PrivateCANComLost_CMRR_RR "ADAS与CMRR-RR私CAN通讯丢失_U135087_E00";
CM_ SG_ 1154 ADAS_PERChkIntFltInfo "PER 检测到内部故障信息_C12C768_E00";
CM_ SG_ 1154 ADAS_HWAActvFlg "HWA-功能激活标志位_ADA0006_E03";
CM_ SG_ 1154 ADAS_HWASucFlg "HWA-功能变道成功标志位_ADA0007_E03";
CM_ SG_ 1162 ADAS_RDPActvFlg "RDP功能激活标志位_ADA0004_E03";
CM_ SG_ 1162 ADAS_ELKActvFlg "ELK功能激活标志位_ADA0005_E03";
CM_ SG_ 792 ESP_318_CheckSum "ESP_318_报文检验和(0x79)ESP_318_CheckSum";
CM_ SG_ 792 ESP_318_AliveCounter "ESP_318_报文计数器ESP_318_AliveCounter";
CM_ SG_ 792 ESP_VehSpdVld "ABS_ESC信号提示车速是否有效When the diagnostic have set the failure code on this signal the value wil be 2.";
CM_ SG_ 792 ESP_LampSwtOffIndcn "ESP关闭指示Signal indicates to light up 'TCS/ESP off' lamp.



-manual switch off of ESP function (on/off switch).



Not used for ABS.";
CM_ SG_ 792 ESP_FltIndcn_ABS "ABS故障指示Signal indicates to light up ABS lamp.";
CM_ SG_ 792 ESP_VehSpd "车速信号";
CM_ SG_ 792 ESP_FltIndcn_TCS "ESP/TCS故障指示Signal indicates failure monitoring of ESP function. Not used for ABS";
CM_ SG_ 792 ESP_CtrlSts_HDC "指示HDC处于开/关或工作状态，另外ADAS接收此信号判断ACC是否关闭。HDC control(Off/On, not active braking/On, active braking).";
CM_ SG_ 792 ESP_NoBrkP "车辆静止情况下，功能目前有没有制动力，是否在制动。no brake pressure applied; generally it regards wheel cylinder presure.";
CM_ SG_ 609 ESP_261_CheckSum "ESP_261_报文检验和(0x72)ESP_261_CheckSum";
CM_ SG_ 609 ESP_261_AliveCounter "ESP_261_报文计数器ESP_261_AliveCounter";
CM_ SG_ 609 ESP_ActvSig "ESP激活信号VDC operating



When ESP is active shall the system send out a bus signal.



Not used for ABS.";
CM_ SG_ 609 ESP_ActvSig_TCS "TCS激活信号TCS operating(including DTC operating)



When TCS is active shall the system send out a bus signal.



Not used for ABS.";
CM_ SG_ 609 ESP_ActvSig_EBD "EBD激活信号indicating EBD in active control or not.";
CM_ SG_ 609 ESP_ActvSig_DTC "DTC激活信号indicate DTC in active control or not.";
CM_ SG_ 609 ESP_Actvndcn_CDD "CDD工作指示indicating CDD is working or not.";
CM_ SG_ 609 ESP_FltIndcn_CDD "CDD故障指示indicating CDD is available or not.";
CM_ SG_ 609 ESP_ActvIndcn_ABA "ABA工作指示ABA is active.";
CM_ SG_ 609 ESP_FltIndcn_ABA "ABA故障指示the ABA function is available.";
CM_ SG_ 609 ESP_ActvIndcn_ABP "ABP工作指示Prefill (ABP) is active.";
CM_ SG_ 609 ESP_FltIndcn_ABP "ABP故障指示Prefill (ABP) is available.";
CM_ SG_ 609 ESP_ActvIndcn_AEB "AEB工作指示ESP is excuting AEB  braking function.";
CM_ SG_ 609 ESP_FltIndcn_AEB "AEB故障指示AEB is available.";
CM_ SG_ 609 ESP_ActvIndcn_AWB "AWB工作指示AWB is active(brake jerk).";
CM_ SG_ 609 ESP_FltIndcn_AWB "AWB故障指示AWB is available. Feedback of AWB activation for ACC.";
CM_ SG_ 609 ESP_VehStandstillIndcn "车辆停止指示indicating whether the vehicle is standstill or not;must not be set until standstill is surely reached.";
CM_ SG_ 609 ESP_BrkOverTIndcn "制动盘高温指示，置1会退出ACC功能indicating brake temperature too high or not.";
CM_ SG_ 773 ESP_305_CheckSum "ESP_305_报文检验和(0x8A)ESP_305_CheckSum";
CM_ SG_ 773 ESP_305_AliveCounter "ESP_305_报文计数器ESP_305_AliveCounter";
CM_ SG_ 773 ESP_WhlSpdVld_RF "右前轮速度有效位Validty of signal 'WHEEL_SPEED_FRONT_RIGHT_ACC '";
CM_ SG_ 773 ESP_WhlSpd_RF "右前轮速度Wheel speed of the front right wheel.";
CM_ SG_ 773 ESP_WhlMovgDir_RF "右前轮移动方向(向前为正，向后为负)Front Right wheel Moving direction.";
CM_ SG_ 773 ESP_WhlMovgDir_LF "左前轮移动方向(向前为正，向后为负)Front left wheel Moving direction.";
CM_ SG_ 773 ESP_WhlSpdVld_LF "左前轮速度有效位Validty of signal 'WHEEL_SPEED_FRONT_LEFT_ACC'";
CM_ SG_ 773 ESP_WhlSpd_LF "左前轮速度Wheel speed of the front left wheel.";
CM_ SG_ 774 ESP_306_CheckSum "ESP_306_报文检验和(0x9F)ESP_306_CheckSum";
CM_ SG_ 774 ESP_306_AliveCounter "ESP_306_报文计数器ESP_306_AliveCounter";
CM_ SG_ 774 ESP_WhlSpdVld_RR "右后轮速度有效位Validty of signal 'WHEEL_SPEED_REAR_RIGHT_ACC'.";
CM_ SG_ 774 ESP_WhlSpd_RR "右后轮速Wheel speed of the rear right wheel.";
CM_ SG_ 774 ESP_WhlMovgDir_RR "右后轮移动方向(向前为正，向后为负)Rear Right wheel Moving direction.";
CM_ SG_ 774 ESP_WhlMovgDir_RL "左后轮移动方向(向前为正，向后为负)Rear left wheel Moving direction.";
CM_ SG_ 774 ESP_WhlSpdVld_RL "左后轮速度有效位Validty of signal 'WHEEL_SPEED_REAR_LEFT_ACC'.";
CM_ SG_ 774 ESP_WhlSpd_RL "左后轮速度Wheel speed of the rear left wheel.";
CM_ SG_ 818 ESP_332_CheckSum "ESP_332_报文检验和(0x8C)ESP_332_CheckSum";
CM_ SG_ 818 ESP_332_AliveCounter "ESP_332_报文计数器ESP_332_AliveCounter";
CM_ SG_ 818 ESP_BrkLiReq "制动灯请求requires to illuminate brake light.";
CM_ SG_ 616 ESP_268_CheckSum "ESP_268_报文检验和(0x7B)ESP_268_CheckSum";
CM_ SG_ 616 ESP_268_AliveCounter "ESP_268_报文计数器ESP_268_AliveCounter";
CM_ SG_ 616 ESP_SysSts_EPB "EPB状态Status of EPB system.";
CM_ SG_ 616 ESP_FltIndcn_EPB "EPB系统错误指示indicating EPB is available or not.";
CM_ SG_ 616 ESP_YawRateStabnAvl "横向稳定性信号(表针横向稳定性是否可用。如果0x0:None，表针横向VMC功能不可用) ";
CM_ SG_ 616 ESP_EPBSwtichPosition "EPB 开关状态";
CM_ SG_ 288 ESP_120_CheckSum "ESP_120_报文检验和(0xB1)ESP_120_CheckSum";
CM_ SG_ 288 ESP_120_AliveCounter "ESP_120_报文计数器ESP_120_AliveCounter";
CM_ SG_ 288 ESP_ActvSig_ABS "ABS激活信号ABS operating



When ABS is active shall the system send out a bus signal.";
CM_ SG_ 288 ESP_VmcVseYawRateAvlCpby "横摆角速度信号质量";
CM_ SG_ 288 ESP_MstCylP "主缸压力(Real value = raw value - offset)Current pressure of the master cylinder pressure sensor in the ESP. Raw value without offset compensation.";
CM_ SG_ 288 ESP_MstCylPVld "主缸压力有效位Information about signal quality of pMC1.";
CM_ SG_ 288 ESP_MstCylPOffs "主缸压力偏移Master cylinder pressure offset.(Real value = raw value – offset)";
CM_ SG_ 288 ESP_VmcVseSasAvlCpby "方向盘转角信号质量";
CM_ SG_ 288 ESP_MstCylPOffsVld " 主缸压力偏移有效位Valid Information of the signal.";
CM_ SG_ 290 ESP_122_CheckSum "ESP_122_报文检验和(0xF4)ESP_122_CheckSum";
CM_ SG_ 290 ESP_122_AliveCounter "ESP_122_报文计数器ESP_122_AliveCounter";
CM_ SG_ 290 ESP_VmcVseLgtPrimSrvAvlCpby "(VmcVseAxOvrGrnd, VmcVsevVeh, VmcVseSlope,VmcVseStandstill)的质量";
CM_ SG_ 290 ESP_VmcVseAxOvrGrnd "实际路面纵向加速度";
CM_ SG_ 290 ESP_VmcVsevVeh "实际车速";
CM_ SG_ 290 ESP_VmcVseSasOffset "方向盘转角偏移量";
CM_ SG_ 625 iBooster_271_CheckSum "iBooster_271_报文检验和(0xA4)iBooster_271_CheckSum";
CM_ SG_ 625 iBooster_271_AliveCounter "iBooster_271_报文计数器iBooster_271_AliveCounter";
CM_ SG_ 625 iBooster_BrkPedlAppldFlg "制动踏板踩下标志位information about the driver attendance.";
CM_ SG_ 625 iBooster_BrkPedlAppldVld "制动踏板踩下标志位的状态位Qualifier for BrakePedalApplied.";
CM_ SG_ 450 EPS_1C2_CheckSum "EPS_1C2_报文检验和(0x90)EPS_1C2_CheckSum";
CM_ SG_ 450 EPS_1C2_AliveCounter "EPS_1C2_报文计数器EPS_1C2_AliveCounter";
CM_ SG_ 450 EPS_SteerWhlAgSig "方向盘转角信号(逆时针为正，顺时针为负)Steering wheel angle left is positive，right is negative.";
CM_ SG_ 450 EPS_SteerAgSnsrCalSts "转角传感器标定状态SAS Calibration status.";
CM_ SG_ 450 EPS_SteerWhlAgSigVld "方向盘转角信号有效位indicate Steer Wheel Angle signal valid or not.";
CM_ SG_ 450 EPS_SteerWhlRotSpdVld "方向盘转速有效位";
CM_ SG_ 450 EPS_WarnVbrnSts "EPS振动报警激活状态";
CM_ SG_ 450 EPS_SteerWhlRotSpd "方向盘转速(逆时针为正，顺时针为负)Rotation speed of the steering wheel.";
CM_ SG_ 450 EPS_SteerWhlVbrnAlrmAvl "方向盘震动报警是否可用";
CM_ SG_ 450 EPS_MaxSftyTq "最大安全限制扭矩";
CM_ SG_ 452 EPS_1C4_CheckSum "EPS_1C4_报文检验和(0x9C)EPS_1C4_CheckSum";
CM_ SG_ 452 EPS_1C4_AliveCounter "EPS_1C4_报文计数器EPS_1C4_AliveCounter";
CM_ SG_ 452 EPS_DrvrSteerTqDir "驾驶员转向力矩方向(逆时针为0，顺时针为1)";
CM_ SG_ 452 EPS_DrvrSteerTqVld "驾驶员转向力矩有效位";
CM_ SG_ 452 EPS_DrvrSteerTq "驾驶员转向力矩";
CM_ SG_ 452 EPS_EmgyCtrlSts "EPS紧急控制状态(Reserved)";
CM_ SG_ 452 EPS_EPSAvl "EPS可不可用";
CM_ SG_ 452 EPS_SteerSnsrSts "转角传感器状态SAS_Failure_Status.";
CM_ SG_ 452 EPS_LatMtnCtrlSts "EPS横向控制激活状态";
CM_ SG_ 452 EPS_MinSftyTq "最小安全限制扭矩";
CM_ SG_ 452 EPS_PinionAg "小齿轮转角(逆时针为正，顺时针为负)";
CM_ SG_ 1141 EPS_ModSts "EPS模式状态";
CM_ SG_ 793 SDM_319_CheckSum "SDM_319_报文检验和(0x98)SDM_319_CheckSum";
CM_ SG_ 793 SDM_319_AliveCounter "SDM_319_报文计数器SDM_319_AliveCounter";
CM_ SG_ 793 SDM_AirBagSysAlrmLampSts "安全气囊系统报警灯状态";
CM_ SG_ 793 SDM_DrverSecuBltAlrmSts "驾驶员安全带报警状态";
CM_ SG_ 793 SDM_PassSecuBltAlrmSts "副驾驶安全带报警状态";
CM_ SG_ 793 SDM_CllsnSig "碰撞信号";
CM_ SG_ 793 SDM_FrntCllsn "正面碰撞";
CM_ SG_ 793 SDM_LeSideCllsn "左侧面碰撞";
CM_ SG_ 793 SDM_RiSideCllsn "右侧面碰撞";
CM_ SG_ 793 SDM_ReCllsn "后面碰撞";
CM_ SG_ 578 YRS_242_CheckSum "YRS_242_报文检验和(0xA1)YRS_242_CheckSum";
CM_ SG_ 578 YRS_242_AliveCounter "YRS_242_报文计数器YRS_242_AliveCounter";
CM_ SG_ 578 YRS_YawRateCalSts "偏航率传感器标定状态Indicates YawRate Sensor Calibration State.";
CM_ SG_ 578 YRS_YawRateSnsrSts "偏航率传感器的状态Indicates YawRate Sensor State.";
CM_ SG_ 578 YRS_LatSnsrSts "横向传感器的状态Indicates Lateral Sensor State.";
CM_ SG_ 578 YRS_LatAcce "横向加速度(左侧为正,右侧为负,Real Value = raw value -offset)Indicates Lateral Acceleration.";
CM_ SG_ 578 YRS_YawRate "指示偏航率(逆时针为正,顺时针为负,Real Value = raw value -offset)Indicates Yaw Rate.";
CM_ SG_ 582 YRS_246_CheckSum "YRS_246_报文检验和(0xB8)";
CM_ SG_ 582 YRS_246_AliveCounter "YRS_246_报文计数器";
CM_ SG_ 582 YRS_LgtSnsrSts "纵向传感器的状态Indicates Longitudinal Sensor State";
CM_ SG_ 582 YRS_LgtAcce "纵向加速度(向前为正,向后为负,Real Value = raw value -offset)Indicates Longitudinal Acceleration";
CM_ SG_ 778 ESP_30A_CheckSum "ESP_30A_报文检验和(0x74)ESP_30A_CheckSum";
CM_ SG_ 778 ESP_30A_AliveCounter "ESP_30A_报文计数器ESP_30A_AliveCounter";
CM_ SG_ 778 ESP_LgtOffs "纵向加速度偏移量It is used with Longitudinal acceleration raw data (Real value = raw value – offset).";
CM_ SG_ 778 ESP_LatOffs "侧向加速度偏移量It is used with Lateral acceleration raw data (Real value = raw value – offset).";
CM_ SG_ 778 ESP_YAWVOffs "横摆角速度偏移量It is used with YAW veloctity raw data (Real value = raw value – offset).";
CM_ SG_ 821 BCM_335_CheckSum "BCM_335_报文校验和(0xD4)BCM_335_CheckSum";
CM_ SG_ 821 BCM_335_AliveCounter "BCM_335_报文计数器BCM_335_AliveCounter";
CM_ SG_ 821 BCM_ReFogLampSwtSts "后雾灯开关状态";
CM_ SG_ 821 BCM_DangerAlrmLampSwtSts "危险报警灯开关状态";
CM_ SG_ 821 BCM_LeTrunLampOutpCmd "左转向灯输出命令";
CM_ SG_ 821 BCM_RiTrunLampOutpCmd "右转向灯输出命令";
CM_ SG_ 821 BCM_ReWiprOutpCmd "后雨刮输出命令";
CM_ SG_ 821 BCM_HiBeamOutpCmd "远光灯输出命令";
CM_ SG_ 821 BCM_LoBeamOutpCmd "近光灯输出命令";
CM_ SG_ 835 BCM_343_CheckSum "BCM_343_报文校验和(0xD7)BCM_343_CheckSum";
CM_ SG_ 835 BCM_343_AliveCounter "BCM_343_报文计数器BCM_343_AliveCounter";
CM_ SG_ 835 BCM_FrntHoodLidSts "前机舱盖状态";
CM_ SG_ 835 BCM_LeFrntDoorSts "左前门状态";
CM_ SG_ 835 BCM_RiFrntDoorSts "右前门状态";
CM_ SG_ 835 BCM_RiReDoorSts "右后门状态";
CM_ SG_ 835 BCM_LeReDoorSts "左后门状态";
CM_ SG_ 883 ECC_OutdT "车外环境温度";
CM_ SG_ 883 ECC_OutdTVld "车外环境温度有效位";
CM_ SG_ 1410 ECC_InsdT "车内温度";
CM_ SG_ 1583 TBOX_CrtTi_Day "当前时间_日";
CM_ SG_ 1583 TBOX_CrtTi_Hr "当前时间_小时";
CM_ SG_ 1583 TBOX_CrtTi_Mins "当前时间_分钟";
CM_ SG_ 1583 TBOX_CrtTi_Yr "当前时间_年";
CM_ SG_ 1583 TBOX_CrtTi_Mth "当前时间_月";
CM_ SG_ 1583 TBOX_CrtTi_Sec "当前时间_秒";
CM_ SG_ 336 MCU_F_150_CheckSum "前MCU_150_报文校验和(0x29)MCU_F_150_CheckSum";
CM_ SG_ 336 MCU_F_150_AliveCounter "前MCU_150_报文计数器MCU_F_150_AliveCounter";
CM_ SG_ 336 MCU_F_CrtSpd "前驱动电机当前转速MotorFSpeed";
CM_ SG_ 336 MCU_F_CrtSpdSigVld "前驱动电机当前转速信号有效位MotorFSpeedsignalvalidflag";
CM_ SG_ 337 MCU_R_151_CheckSum "后MCU_151_报文校验和(0x34)MCU_R_151_CheckSum";
CM_ SG_ 337 MCU_R_151_AliveCounter "后MCU_151_报文计数器MCU_R_151_AliveCounter";
CM_ SG_ 337 MCU_R_CrtSpd "后驱动电机当前转速MotorRSpeed";
CM_ SG_ 337 MCU_R_CrtSpdSigVld "后驱动电机当前转速信号有效位MotorRSpeedsignalvalidflag";
CM_ SG_ 1137 PLG_TrSwtStsIndcn "后尾门开关状态信号Indicate trunk status.";
CM_ SG_ 784 CIM_310_CheckSum "CIM_310_报文校验和(0xC8)CIM_310_CheckSum";
CM_ SG_ 784 CIM_310_AliveCounter "CIM_310_报文计数器CIM_310_AliveCounter";
CM_ SG_ 784 CIM_TurnLampSwtSts "转向灯开关状态turn signal lever status.";
CM_ SG_ 784 CIM_HiBeamSwtSts "远光灯开关状态High beam switch status.";
CM_ SG_ 784 CIM_FrntWshrSwtSts "前洗涤开关状态WasherFrontCommand.";
CM_ SG_ 784 CIM_ReWshrSwtSts "后洗涤开关状态WasherRearCommand.";
CM_ SG_ 784 CIM_FrntWiprSwtSts "前雨刮刮水开关状态Wiper front command.";
CM_ SG_ 784 CIM_Swt_ADAS "手柄朝向靠近驾驶员方向拨";
CM_ SG_ 784 CIM_Cncl_ADAS "手柄朝向远离驾驶员方向拨";
CM_ SG_ 784 CIM_SpdRgln_ADAS "对应巡航手柄上下拨(各两档)ADAS speed regulation.";
CM_ SG_ 784 CIM_DstWithCarFrntAdj "跟车时距调节distance with the car front adjust. ";
CM_ SG_ 784 CIM_SpdLim_ADAS "顶端按键(智能限速)ADAS speed limit.";
CM_ SG_ 784 CIM_SwtVld_ADAS "对应巡航手柄前拨有效位(ACC、LKA、TJA、ICA开关)";
CM_ SG_ 784 CIM_SpdRglnVld_ADAS "对应巡航手柄上下拨有效位(各两档)ADAS speed regulation.";
CM_ SG_ 549 VCU_225_CheckSum "VCU_225_报文校验和(0x2A)VCU_225_CheckSum ";
CM_ SG_ 549 VCU_225_AliveCounter "VCU_225_报文计数器VCU_225_AliveCounter";
CM_ SG_ 549 VCU_OverMod "超越模式";
CM_ SG_ 549 VCU_MotChkACCFltFbFlg "电机检测ACC故障反馈标志位";
CM_ SG_ 549 VCU_VehTqFltSts "整车扭矩故障状态";
CM_ SG_ 549 VCU_VehMaxWhlTq "整车允许最大轮端扭矩(总和)";
CM_ SG_ 532 VCU_214_CheckSum "VCU_214_报文校验和(0x12)VCU_214_CheckSum";
CM_ SG_ 532 VCU_214_AliveCounter "VCU_214_报文计数器VCU_214_AliveCounter";
CM_ SG_ 532 VCU_RdyLamp "READY灯";
CM_ SG_ 532 VCU_GearSigVld "挡位信号有效位";
CM_ SG_ 532 VCU_GearSig "挡位信号";
CM_ SG_ 532 VCU_DrvModSig "驾驶模式信号";
CM_ SG_ 1317 EHU_525_CheckSum "EHU_525_报文校验和(0xF9)EHU_525_CheckSum";
CM_ SG_ 1317 EHU_525_AliveCounter "EHU_525_报文计数器EHU_525_AliveCounterr";
CM_ SG_ 1317 EHU_GPSLongi "经度(东经为正，西经为负。)Longitude";
CM_ SG_ 1317 EHU_GPSLati "纬度(北纬为正，南纬为负。)Latitude";
CM_ SG_ 822 EHU_336_Checksum "EHU_336_报文校验和(0xE5)EHU_336_Checksum";
CM_ SG_ 822 EHU_336_AliveCounter "EHU_336_消息计数器EHU_336_AliveCounter";
CM_ SG_ 822 EHU_SpdLimOffs "速度限值偏差(预留)";
CM_ SG_ 1318 EHU_IntegtCrsSwt "智能巡航系统开关";
CM_ SG_ 1318 EHU_IntegtCrsModSet "智能巡航系统模式设置(预留)";
CM_ SG_ 1318 EHU_LaneSprtSwt "车道辅助系统开关";
CM_ SG_ 1318 EHU_LaneSprtTypSet "车道辅助类型设置";
CM_ SG_ 1318 EHU_FCWFCTASwt "前碰撞预警开关";
CM_ SG_ 1318 EHU_AEBFCTBSwt "自动紧急制动开关";
CM_ SG_ 1318 EHU_ESSSwt "紧急转向辅助开关";
CM_ SG_ 1318 EHU_LDWAlrmTypReq "报警类型(LDW)请求";
CM_ SG_ 1318 EHU_ADASSnvtySet "ADAS灵敏度设置";
CM_ SG_ 1318 EHU_HiwayExitAuxReq "高速公路出口辅助请求";
CM_ SG_ 1318 EHU_HiwayExitAuxSwt "高速公路出口辅助开关";
CM_ SG_ 1318 EHU_VoiceSpdRgln_ADAS "语音设置ACC车速";
CM_ SG_ 1329 ICM_TotMilgVld_ODO "ODO总里程有效位";
CM_ SG_ 1329 ICM_TotMilg_ODO "ODO总里程";
CM_ SG_ 1329 ICM_DispVehSpd "显示车速";
CM_ SG_ 1329 ICM_DispVehSpdUnit "显示车速单位";
CM_ SG_ 1329 ICM_ADASSigFlt "仪表ADAS信号故障";
CM_ SG_ 1329 ICM_DispFlt "仪表显示故障";
CM_ SG_ 1328 EHU_NavCtryCod "导航-国家代码";
CM_ SG_ 1328 EHU_NavRoadTyp "导航-道路类型Road type from navigation.";
CM_ SG_ 1328 EHU_NavSpdLimUnit "导航-限速单位Speed limit unit from naviation.";
CM_ SG_ 1328 EHU_NavSpdLimSts "导航-限速状态Navigation state.";
CM_ SG_ 1328 EHU_NavSpdLim "导航-限速Speed limit from navigation.";
CM_ SG_ 1328 EHU_NavSpdLimExitDst "导航-限速出口距离";
CM_ SG_ 830 MRR_FrntSnsrFlt "前雷达故障(ICC暂不处理)";
CM_ SG_ 830 MRR_FrntSnsrBli "前雷达遮挡(ICC暂不处理)";
CM_ SG_ 820 MPC_FrntCamBli "前摄像头遮挡";
CM_ SG_ 820 MPC_FrntCamFlt "前摄像头故障(ICC暂不处理)";
CM_ SG_ 824 CMRR_RL_LeWarn_LCA "LCA左侧报警";
CM_ SG_ 824 CMRR_RL_SnsrFlt "后左雷达故障(ICC暂不处理)";
CM_ SG_ 824 CMRR_RL_SnsrBli "后左雷达遮挡(ICC暂不处理)";
CM_ SG_ 824 CMRR_RL_LeWarn_LCA_ELK "LCA左侧报警_ELK";
CM_ SG_ 824 CMRR_RL_SDASts "SDA状态";
CM_ SG_ 824 CMRR_RL_SDAWarn "SDA报警";
CM_ SG_ 606 CMRR_FR_FrntLeSnsrFlt "前右雷达故障(ICC暂不处理)";
CM_ SG_ 606 CMRR_FR_FrntLeSnsrBli "前右角雷达遮挡(ICC暂不处理)";
CM_ SG_ 606 CMRR_FR_SDASts "SDA状态";
CM_ SG_ 606 CMRR_FR_SDAWarn "SDA报警";
CM_ SG_ 604 CMRR_FL_FrntLeSnsrFlt "前左雷达故障(ICC暂不处理)";
CM_ SG_ 604 CMRR_FL_FrntLeSnsrBli "前左角雷达遮挡(ICC暂不处理)";
CM_ SG_ 604 CMRR_FL_SDASts "SDA状态";
CM_ SG_ 604 CMRR_FL_SDAWarn "SDA报警";
CM_ SG_ 826 CMRR_RR_RiWarn_LCA "LCA右侧报警";
CM_ SG_ 826 CMRR_RR_SnsrFlt "后右雷达故障(ICC暂不处理)";
CM_ SG_ 826 CMRR_RR_SnsrBli "后右雷达遮挡(ICC暂不处理)";
CM_ SG_ 826 CMRR_RR_LCASwtFb "变道预警开关反馈";
CM_ SG_ 826 CMRR_RR_RiWarn_LCA_ELK "LCA右侧报警_ELK";
CM_ SG_ 826 CMRR_RR_SDAWarn "SDA报警";
CM_ SG_ 826 CMRR_RR_SDASts "SDA状态";
CM_ SG_ 819 PEPS_333_CheckSum "PEPS_333_报文校验和(0xCB)PEPS_333_CheckSum";
CM_ SG_ 819 PEPS_333_AliveCounter "PEPS_333_报文计数器PEPS_333_AliveCounter";
CM_ SG_ 819 PEPS_PwrMod "电源模式";
CM_ SG_ 819 PEPS_PwrModVld "电源模式有效值";
CM_ SG_ 1417 TPMS_TirePosn "轮胎位置";
CM_ SG_ 1417 TPMS_SngTirePSts "轮胎压力状态";
CM_ SG_ 1319 EHU_DrvrSts "驾驶员状态";
CM_ SG_ 1319 EHU_DrvrOccpy "驾驶员座椅坐人确认(预留)";
CM_ SG_ 432 APA_1B0_CheckSum "APA_1B0_报文检验和(0x2B)APA_1B0_CheckSum";
CM_ SG_ 432 APA_1B0_AliveCounter "APA_1B0_报文计数器APA_1B0_AliveCounter";
CM_ SG_ 432 APA_Sts "APA功能状态APA Status - System provides the current state of the Active Feature.";
CM_ SG_ 658 APA_292_CheckSum "APA_292_报文检验和(0xA3)APA_292_CheckSum";
CM_ SG_ 658 APA_292_AliveCounter "APA_292_报文计数器APA_292_AliveCounter";
CM_ SG_ 658 APA_CrtPrkgTyp "当前泊车控制方式(自动/遥控)Indicates current parking type, as APA, RPA, Assist.";
CM_ SG_ 1368 APA_558_CheckSum "APA_558_报文检验和(0xCF)APA_558_CheckSum";
CM_ SG_ 1368 APA_558_AliveCounter "APA_558_报文计数器APA_558_AliveCounter";
CM_ SG_ 1368 APA_Sts_PAS "PAS工作状态Parking Assistant  System Status.";
CM_ SG_ 672 APA_FMEBSts "前低速辅助制动系统状态信号";
CM_ SG_ 672 APA_RMEBSts "后低速辅助制动系统状态信号";
CM_ SG_ 1300 MFS_LeRollPress "左侧滚轮(按下)";
CM_ SG_ 1300 MFS_RiRollPress "右侧滚轮(按下)";
CM_ SG_ 592 EHU_SegFuncRoadClass "segment FRC信息(对应道路类型，主路)Functional Road Class indicates relative importance of the road in the routing network and lower values indicate higher priority. This information is usually map-provider specific. ";
CM_ SG_ 592 EHU_SegEffSpdLmtType "segment有效限速类型信息";
CM_ SG_ 593 EHU_StubFuncRoadClass "stub FRC信息(对应道路类型)Functional Road Class of new path indicates relative importance of the road in the routing network and lower values indicate higher priority. This information is usually map-provider specific. Regular values are 1-6; value 0 is unknown, value 7 indicates N/A.";
CM_ SG_ 593 EHU_StubTurnAngl "新路径相对于主路径的角度";
CM_ SG_ 442 VCU_1BA_CheckSum "VCU_1BA_报文校验和(0x75)VCU_1BA_CheckSum";
CM_ SG_ 442 VCU_1BA_AliveCounter "VCU_1BA_报文计数器VCU_1BA_AliveCounter";
CM_ SG_ 442 VCU_DrvrAPSPerc "驾驶员加速踏板开度";
CM_ SG_ 442 VCU_DrvrAPSPercVld "驾驶员加速踏板开度有效位";
CM_ SG_ 442 VCU_WhlTqActVld "VCU轮端总扭矩有效位";
CM_ SG_ 442 VCU_WhlTqAct "VCU轮端总扭矩";
CM_ SG_ 440 ESP_RoadSlop "路面坡度";

BA_DEF_ BO_  "DiagState" ENUM  "No","Yes";
BA_DEF_ BO_  "DiagResponse" ENUM  "No","Yes";
BA_DEF_ BO_  "GenMsgSendType" ENUM  "cyclic","NoMsgSendType","IfActive","Event","CA","CE";
BA_DEF_ BO_  "GenMsgCycleTime" INT 0 0;
BA_DEF_ SG_  "GenSigSendType" ENUM  "cyclic","OnChange","OnWrite","IfActive","OnChangeWithRepetition","OnWriteWithRepetition","IfActiveWithRepetition","CA","CE","Event";
BA_DEF_ SG_  "GenSigStartValue" INT 0 0;
BA_DEF_ BO_  "GenMsgCycleTimeFast" INT 0 0;
BA_DEF_ BO_  "GenMsgNrOfRepetition" INT 0 0;
BA_DEF_ BO_  "GenMsgDelayTime" INT 0 0;
BA_DEF_  "DBName" STRING ;
BA_DEF_ BO_  "CANFD_BRS" ENUM  "0","1";
BA_DEF_ BO_  "VFrameFormat" ENUM  "StandardCAN","ExtendedCAN","reserved","reserved","reserved","reserved","reserved","reserved","reserved","reserved","reserved","reserved","reserved","reserved","StandardCAN_FD","ExtendedCAN_FD";
BA_DEF_  "BusBaudateData" INT 0 10000;
BA_DEF_  "BusBaudateOther" INT 0 10000;
BA_DEF_ BO_  "GenMsgILSupport" ENUM  "No","Yes";
BA_DEF_  "NmBaseAddress" HEX 1024 1087;
BA_DEF_  "BusType" STRING ;
BA_DEF_ SG_ "sigDespEng" STRING;
BA_DEF_ SG_ "sigSecLevel" STRING;
BA_DEF_ SG_ "sigConfig" STRING;
BA_DEF_ SG_ "sigExplanation" STRING;

BA_DEF_DEF_  "DiagState" "No";
BA_DEF_DEF_  "DiagResponse" "No";
BA_DEF_DEF_  "GenMsgSendType" "cyclic";
BA_DEF_DEF_  "GenMsgCycleTime" 0;
BA_DEF_DEF_  "GenSigSendType" "cyclic";
BA_DEF_DEF_  "GenSigStartValue" 0;
BA_DEF_DEF_  "GenMsgCycleTimeFast" 0;
BA_DEF_DEF_  "GenMsgNrOfRepetition" 0;
BA_DEF_DEF_  "GenMsgDelayTime" 0;
BA_DEF_DEF_  "DBName" "";
BA_DEF_DEF_  "CANFD_BRS" "1";
BA_DEF_DEF_  "VFrameFormat" "StandardCAN";
BA_DEF_DEF_  "BusBaudateData" 2;
BA_DEF_DEF_  "BusBaudateOther" 500;
BA_DEF_DEF_  "GenMsgILSupport" "Yes";
BA_DEF_DEF_  "NmBaseAddress" 1024;
BA_DEF_DEF_  "BusType" "CAN FD";
BA_DEF_DEF_ "sigDespEng" "" ;
BA_DEF_DEF_ "sigSecLevel" "QM" ;
BA_DEF_DEF_ "sigConfig" "" ;
BA_DEF_DEF_ "sigExplanation" "" ;
BA_ "DBName" "BJEV_N60AB(EP2)_ADASBUS_Matrix_CANFD_V2.3_20200528";
BA_ "GenMsgCycleTime" BO_ 792 20;
BA_ "VFrameFormat" BO_ 792 14;
BA_ "sigSecLevel"  SG_ 792 ESP_318_CheckSum "";
BA_ "sigSecLevel"  SG_ 792 ESP_318_AliveCounter "";
BA_ "sigSecLevel"  SG_ 792 ESP_VehSpdVld "";
BA_ "sigSecLevel"  SG_ 792 ESP_LampSwtOffIndcn "";
BA_ "sigSecLevel"  SG_ 792 ESP_FltIndcn_ABS "";
BA_ "sigSecLevel"  SG_ 792 ESP_VehSpd "";
BA_ "sigSecLevel"  SG_ 792 ESP_FltIndcn_TCS "";
BA_ "sigSecLevel"  SG_ 792 ESP_CtrlSts_HDC "";
BA_ "sigSecLevel"  SG_ 792 ESP_NoBrkP "";
BA_ "GenMsgCycleTime" BO_ 609 20;
BA_ "VFrameFormat" BO_ 609 14;
BA_ "sigSecLevel"  SG_ 609 ESP_261_CheckSum "";
BA_ "sigSecLevel"  SG_ 609 ESP_261_AliveCounter "";
BA_ "sigSecLevel"  SG_ 609 ESP_ActvSig "";
BA_ "sigSecLevel"  SG_ 609 ESP_ActvSig_TCS "";
BA_ "sigSecLevel"  SG_ 609 ESP_ActvSig_EBD "";
BA_ "sigSecLevel"  SG_ 609 ESP_ActvSig_DTC "";
BA_ "sigSecLevel"  SG_ 609 ESP_Actvndcn_CDD "";
BA_ "sigSecLevel"  SG_ 609 ESP_FltIndcn_CDD "";
BA_ "sigSecLevel"  SG_ 609 ESP_ActvIndcn_ABA "";
BA_ "sigSecLevel"  SG_ 609 ESP_FltIndcn_ABA "";
BA_ "sigSecLevel"  SG_ 609 ESP_ActvIndcn_ABP "";
BA_ "sigSecLevel"  SG_ 609 ESP_FltIndcn_ABP "";
BA_ "sigSecLevel"  SG_ 609 ESP_ActvIndcn_AEB "";
BA_ "sigSecLevel"  SG_ 609 ESP_FltIndcn_AEB "";
BA_ "sigSecLevel"  SG_ 609 ESP_ActvIndcn_AWB "";
BA_ "sigSecLevel"  SG_ 609 ESP_FltIndcn_AWB "";
BA_ "sigSecLevel"  SG_ 609 ESP_VehStandstillIndcn "";
BA_ "sigSecLevel"  SG_ 609 ESP_BrkOverTIndcn "";
BA_ "GenMsgCycleTime" BO_ 773 20;
BA_ "VFrameFormat" BO_ 773 14;
BA_ "sigSecLevel"  SG_ 773 ESP_305_CheckSum "";
BA_ "sigSecLevel"  SG_ 773 ESP_305_AliveCounter "";
BA_ "sigSecLevel"  SG_ 773 ESP_WhlSpdVld_RF "";
BA_ "sigSecLevel"  SG_ 773 ESP_WhlSpd_RF "";
BA_ "sigSecLevel"  SG_ 773 ESP_WhlMovgDir_RF "";
BA_ "sigSecLevel"  SG_ 773 ESP_WhlMovgDir_LF "";
BA_ "sigSecLevel"  SG_ 773 ESP_WhlSpdVld_LF "";
BA_ "sigSecLevel"  SG_ 773 ESP_WhlSpd_LF "";
BA_ "GenMsgCycleTime" BO_ 774 20;
BA_ "VFrameFormat" BO_ 774 14;
BA_ "sigSecLevel"  SG_ 774 ESP_306_CheckSum "";
BA_ "sigSecLevel"  SG_ 774 ESP_306_AliveCounter "";
BA_ "sigSecLevel"  SG_ 774 ESP_WhlSpdVld_RR "";
BA_ "sigSecLevel"  SG_ 774 ESP_WhlSpd_RR "";
BA_ "sigSecLevel"  SG_ 774 ESP_WhlMovgDir_RR "";
BA_ "sigSecLevel"  SG_ 774 ESP_WhlMovgDir_RL "";
BA_ "sigSecLevel"  SG_ 774 ESP_WhlSpdVld_RL "";
BA_ "sigSecLevel"  SG_ 774 ESP_WhlSpd_RL "";
BA_ "GenMsgCycleTime" BO_ 818 50;
BA_ "VFrameFormat" BO_ 818 14;
BA_ "sigSecLevel"  SG_ 818 ESP_332_CheckSum "";
BA_ "sigSecLevel"  SG_ 818 ESP_332_AliveCounter "";
BA_ "sigSecLevel"  SG_ 818 ESP_BrkLiReq "";
BA_ "GenMsgCycleTime" BO_ 616 20;
BA_ "VFrameFormat" BO_ 616 14;
BA_ "sigSecLevel"  SG_ 616 ESP_268_CheckSum "";
BA_ "sigSecLevel"  SG_ 616 ESP_268_AliveCounter "";
BA_ "sigSecLevel"  SG_ 616 ESP_SysSts_EPB "";
BA_ "sigSecLevel"  SG_ 616 ESP_FltIndcn_EPB "";
BA_ "sigSecLevel"  SG_ 616 ESP_YawRateStabnAvl "";
BA_ "sigSecLevel"  SG_ 616 ESP_EPBSwtichPosition "";
BA_ "GenMsgCycleTime" BO_ 288 10;
BA_ "VFrameFormat" BO_ 288 14;
BA_ "sigSecLevel"  SG_ 288 ESP_120_CheckSum "";
BA_ "sigSecLevel"  SG_ 288 ESP_120_AliveCounter "";
BA_ "sigSecLevel"  SG_ 288 ESP_ActvSig_ABS "";
BA_ "sigSecLevel"  SG_ 288 ESP_VmcVseYawRateAvlCpby "";
BA_ "GenSigStartValue" SG_ 288 ESP_MstCylP 300;
BA_ "sigSecLevel"  SG_ 288 ESP_MstCylP "";
BA_ "sigSecLevel"  SG_ 288 ESP_MstCylPVld "";
BA_ "sigSecLevel"  SG_ 288 ESP_MstCylPOffs "";
BA_ "sigSecLevel"  SG_ 288 ESP_VmcVseSasAvlCpby "";
BA_ "sigSecLevel"  SG_ 288 ESP_MstCylPOffsVld "";
BA_ "GenMsgCycleTime" BO_ 290 10;
BA_ "VFrameFormat" BO_ 290 14;
BA_ "sigSecLevel"  SG_ 290 ESP_122_CheckSum "";
BA_ "sigSecLevel"  SG_ 290 ESP_122_AliveCounter "";
BA_ "sigSecLevel"  SG_ 290 ESP_VmcVseLgtPrimSrvAvlCpby "";
BA_ "GenSigStartValue" SG_ 290 ESP_VmcVseAxOvrGrnd 32768;
BA_ "sigSecLevel"  SG_ 290 ESP_VmcVseAxOvrGrnd "";
BA_ "GenSigStartValue" SG_ 290 ESP_VmcVsevVeh 10000;
BA_ "sigSecLevel"  SG_ 290 ESP_VmcVsevVeh "";
BA_ "GenSigStartValue" SG_ 290 ESP_VmcVseSasOffset 7800;
BA_ "sigSecLevel"  SG_ 290 ESP_VmcVseSasOffset "";
BA_ "GenMsgCycleTime" BO_ 625 20;
BA_ "VFrameFormat" BO_ 625 14;
BA_ "sigSecLevel"  SG_ 625 iBooster_271_CheckSum "";
BA_ "sigSecLevel"  SG_ 625 iBooster_271_AliveCounter "";
BA_ "sigSecLevel"  SG_ 625 iBooster_BrkPedlAppldFlg "";
BA_ "sigSecLevel"  SG_ 625 iBooster_BrkPedlAppldVld "";
BA_ "GenMsgCycleTime" BO_ 450 10;
BA_ "VFrameFormat" BO_ 450 14;
BA_ "sigSecLevel"  SG_ 450 EPS_1C2_CheckSum "";
BA_ "sigSecLevel"  SG_ 450 EPS_1C2_AliveCounter "";
BA_ "GenSigStartValue" SG_ 450 EPS_SteerWhlAgSig 12480;
BA_ "sigSecLevel"  SG_ 450 EPS_SteerWhlAgSig "";
BA_ "sigSecLevel"  SG_ 450 EPS_SteerAgSnsrCalSts "";
BA_ "sigSecLevel"  SG_ 450 EPS_SteerWhlAgSigVld "";
BA_ "sigSecLevel"  SG_ 450 EPS_SteerWhlRotSpdVld "";
BA_ "sigSecLevel"  SG_ 450 EPS_WarnVbrnSts "";
BA_ "GenSigStartValue" SG_ 450 EPS_SteerWhlRotSpd 2032;
BA_ "sigSecLevel"  SG_ 450 EPS_SteerWhlRotSpd "";
BA_ "sigSecLevel"  SG_ 450 EPS_SteerWhlVbrnAlrmAvl "";
BA_ "sigSecLevel"  SG_ 450 EPS_MaxSftyTq "";
BA_ "GenMsgCycleTime" BO_ 452 10;
BA_ "VFrameFormat" BO_ 452 14;
BA_ "sigSecLevel"  SG_ 452 EPS_1C4_CheckSum "";
BA_ "sigSecLevel"  SG_ 452 EPS_1C4_AliveCounter "";
BA_ "sigSecLevel"  SG_ 452 EPS_DrvrSteerTqDir "";
BA_ "sigSecLevel"  SG_ 452 EPS_DrvrSteerTqVld "";
BA_ "sigSecLevel"  SG_ 452 EPS_DrvrSteerTq "";
BA_ "sigSecLevel"  SG_ 452 EPS_EmgyCtrlSts "";
BA_ "sigSecLevel"  SG_ 452 EPS_EPSAvl "";
BA_ "sigSecLevel"  SG_ 452 EPS_SteerSnsrSts "";
BA_ "sigSecLevel"  SG_ 452 EPS_LatMtnCtrlSts "";
BA_ "sigSecLevel"  SG_ 452 EPS_MinSftyTq "";
BA_ "GenSigStartValue" SG_ 452 EPS_PinionAg 12480;
BA_ "sigSecLevel"  SG_ 452 EPS_PinionAg "";
BA_ "GenMsgCycleTime" BO_ 1141 100;
BA_ "VFrameFormat" BO_ 1141 14;
BA_ "sigSecLevel"  SG_ 1141 EPS_ModSts "";
BA_ "GenMsgCycleTime" BO_ 793 50;
BA_ "GenMsgCycleTimeFast" BO_ 793 20;
BA_ "GenMsgNrOfRepetition" BO_ 793 10;
BA_ "GenMsgDelayTime" BO_ 793 20;
BA_ "VFrameFormat" BO_ 793 14;
BA_ "sigSecLevel"  SG_ 793 SDM_319_CheckSum "";
BA_ "sigSecLevel"  SG_ 793 SDM_319_AliveCounter "";
BA_ "sigSecLevel"  SG_ 793 SDM_AirBagSysAlrmLampSts "";
BA_ "sigSecLevel"  SG_ 793 SDM_DrverSecuBltAlrmSts "";
BA_ "sigSecLevel"  SG_ 793 SDM_PassSecuBltAlrmSts "";
BA_ "GenSigSendType" SG_ 793 SDM_CllsnSig 5;
BA_ "sigSecLevel"  SG_ 793 SDM_CllsnSig "";
BA_ "sigSecLevel"  SG_ 793 SDM_FrntCllsn "";
BA_ "sigSecLevel"  SG_ 793 SDM_LeSideCllsn "";
BA_ "sigSecLevel"  SG_ 793 SDM_RiSideCllsn "";
BA_ "sigSecLevel"  SG_ 793 SDM_ReCllsn "";
BA_ "GenMsgCycleTime" BO_ 578 10;
BA_ "VFrameFormat" BO_ 578 14;
BA_ "sigSecLevel"  SG_ 578 YRS_242_CheckSum "";
BA_ "sigSecLevel"  SG_ 578 YRS_242_AliveCounter "";
BA_ "sigSecLevel"  SG_ 578 YRS_YawRateCalSts "";
BA_ "sigSecLevel"  SG_ 578 YRS_YawRateSnsrSts "";
BA_ "sigSecLevel"  SG_ 578 YRS_LatSnsrSts "";
BA_ "GenSigStartValue" SG_ 578 YRS_LatAcce 2000;
BA_ "sigSecLevel"  SG_ 578 YRS_LatAcce "";
BA_ "GenSigStartValue" SG_ 578 YRS_YawRate 18000;
BA_ "sigSecLevel"  SG_ 578 YRS_YawRate "";
BA_ "GenMsgCycleTime" BO_ 582 20;
BA_ "VFrameFormat" BO_ 582 14;
BA_ "sigSecLevel"  SG_ 582 YRS_246_CheckSum "";
BA_ "sigSecLevel"  SG_ 582 YRS_246_AliveCounter "";
BA_ "sigSecLevel"  SG_ 582 YRS_LgtSnsrSts "";
BA_ "GenSigStartValue" SG_ 582 YRS_LgtAcce 2000;
BA_ "sigSecLevel"  SG_ 582 YRS_LgtAcce "";
BA_ "GenMsgCycleTime" BO_ 778 20;
BA_ "VFrameFormat" BO_ 778 14;
BA_ "sigSecLevel"  SG_ 778 ESP_30A_CheckSum "";
BA_ "sigSecLevel"  SG_ 778 ESP_30A_AliveCounter "";
BA_ "GenSigStartValue" SG_ 778 ESP_LgtOffs 796;
BA_ "sigSecLevel"  SG_ 778 ESP_LgtOffs "";
BA_ "GenSigStartValue" SG_ 778 ESP_LatOffs 796;
BA_ "sigSecLevel"  SG_ 778 ESP_LatOffs "";
BA_ "GenSigStartValue" SG_ 778 ESP_YAWVOffs 2143;
BA_ "sigSecLevel"  SG_ 778 ESP_YAWVOffs "";
BA_ "GenMsgCycleTime" BO_ 821 50;
BA_ "VFrameFormat" BO_ 821 14;
BA_ "sigSecLevel"  SG_ 821 BCM_335_CheckSum "";
BA_ "sigSecLevel"  SG_ 821 BCM_335_AliveCounter "";
BA_ "sigSecLevel"  SG_ 821 BCM_ReFogLampSwtSts "";
BA_ "sigSecLevel"  SG_ 821 BCM_DangerAlrmLampSwtSts "";
BA_ "sigSecLevel"  SG_ 821 BCM_LeTrunLampOutpCmd "";
BA_ "sigSecLevel"  SG_ 821 BCM_RiTrunLampOutpCmd "";
BA_ "sigSecLevel"  SG_ 821 BCM_ReWiprOutpCmd "";
BA_ "sigSecLevel"  SG_ 821 BCM_HiBeamOutpCmd "";
BA_ "sigSecLevel"  SG_ 821 BCM_LoBeamOutpCmd "";
BA_ "GenMsgCycleTime" BO_ 835 50;
BA_ "VFrameFormat" BO_ 835 14;
BA_ "sigSecLevel"  SG_ 835 BCM_343_CheckSum "";
BA_ "sigSecLevel"  SG_ 835 BCM_343_AliveCounter "";
BA_ "sigSecLevel"  SG_ 835 BCM_FrntHoodLidSts "";
BA_ "sigSecLevel"  SG_ 835 BCM_LeFrntDoorSts "";
BA_ "sigSecLevel"  SG_ 835 BCM_RiFrntDoorSts "";
BA_ "sigSecLevel"  SG_ 835 BCM_RiReDoorSts "";
BA_ "sigSecLevel"  SG_ 835 BCM_LeReDoorSts "";
BA_ "GenMsgCycleTime" BO_ 883 100;
BA_ "VFrameFormat" BO_ 883 14;
BA_ "GenSigStartValue" SG_ 883 ECC_OutdT 48;
BA_ "sigSecLevel"  SG_ 883 ECC_OutdT "";
BA_ "sigSecLevel"  SG_ 883 ECC_OutdTVld "";
BA_ "GenMsgCycleTime" BO_ 1410 100;
BA_ "VFrameFormat" BO_ 1410 14;
BA_ "GenSigStartValue" SG_ 1410 ECC_InsdT 48;
BA_ "sigSecLevel"  SG_ 1410 ECC_InsdT "";
BA_ "GenMsgCycleTime" BO_ 1583 1000;
BA_ "VFrameFormat" BO_ 1583 14;
BA_ "sigSecLevel"  SG_ 1583 TBOX_CrtTi_Day "";
BA_ "sigSecLevel"  SG_ 1583 TBOX_CrtTi_Hr "";
BA_ "sigSecLevel"  SG_ 1583 TBOX_CrtTi_Mins "";
BA_ "sigSecLevel"  SG_ 1583 TBOX_CrtTi_Yr "";
BA_ "sigSecLevel"  SG_ 1583 TBOX_CrtTi_Mth "";
BA_ "sigSecLevel"  SG_ 1583 TBOX_CrtTi_Sec "";
BA_ "GenMsgCycleTime" BO_ 336 10;
BA_ "VFrameFormat" BO_ 336 14;
BA_ "sigSecLevel"  SG_ 336 MCU_F_150_CheckSum "";
BA_ "sigSecLevel"  SG_ 336 MCU_F_150_AliveCounter "";
BA_ "GenSigStartValue" SG_ 336 MCU_F_CrtSpd 32768;
BA_ "sigSecLevel"  SG_ 336 MCU_F_CrtSpd "";
BA_ "sigSecLevel"  SG_ 336 MCU_F_CrtSpdSigVld "";
BA_ "GenMsgCycleTime" BO_ 337 10;
BA_ "VFrameFormat" BO_ 337 14;
BA_ "sigSecLevel"  SG_ 337 MCU_R_151_CheckSum "";
BA_ "sigSecLevel"  SG_ 337 MCU_R_151_AliveCounter "";
BA_ "GenSigStartValue" SG_ 337 MCU_R_CrtSpd 32768;
BA_ "sigSecLevel"  SG_ 337 MCU_R_CrtSpd "";
BA_ "sigSecLevel"  SG_ 337 MCU_R_CrtSpdSigVld "";
BA_ "GenMsgCycleTime" BO_ 1137 100;
BA_ "VFrameFormat" BO_ 1137 14;
BA_ "sigSecLevel"  SG_ 1137 PLG_TrSwtStsIndcn "";
BA_ "GenMsgCycleTime" BO_ 784 20;
BA_ "VFrameFormat" BO_ 784 14;
BA_ "sigSecLevel"  SG_ 784 CIM_310_CheckSum "";
BA_ "sigSecLevel"  SG_ 784 CIM_310_AliveCounter "";
BA_ "sigSecLevel"  SG_ 784 CIM_TurnLampSwtSts "";
BA_ "sigSecLevel"  SG_ 784 CIM_HiBeamSwtSts "";
BA_ "sigSecLevel"  SG_ 784 CIM_FrntWshrSwtSts "";
BA_ "sigSecLevel"  SG_ 784 CIM_ReWshrSwtSts "";
BA_ "sigSecLevel"  SG_ 784 CIM_FrntWiprSwtSts "";
BA_ "sigSecLevel"  SG_ 784 CIM_Swt_ADAS "";
BA_ "sigSecLevel"  SG_ 784 CIM_Cncl_ADAS "";
BA_ "sigSecLevel"  SG_ 784 CIM_SpdRgln_ADAS "";
BA_ "sigSecLevel"  SG_ 784 CIM_DstWithCarFrntAdj "";
BA_ "sigSecLevel"  SG_ 784 CIM_SpdLim_ADAS "";
BA_ "sigSecLevel"  SG_ 784 CIM_SwtVld_ADAS "";
BA_ "sigSecLevel"  SG_ 784 CIM_SpdRglnVld_ADAS "";
BA_ "GenMsgCycleTime" BO_ 549 20;
BA_ "VFrameFormat" BO_ 549 14;
BA_ "sigSecLevel"  SG_ 549 VCU_225_CheckSum "";
BA_ "sigSecLevel"  SG_ 549 VCU_225_AliveCounter "";
BA_ "sigSecLevel"  SG_ 549 VCU_OverMod "";
BA_ "sigSecLevel"  SG_ 549 VCU_MotChkACCFltFbFlg "";
BA_ "sigSecLevel"  SG_ 549 VCU_VehTqFltSts "";
BA_ "GenSigStartValue" SG_ 549 VCU_VehMaxWhlTq 32768;
BA_ "sigSecLevel"  SG_ 549 VCU_VehMaxWhlTq "";
BA_ "GenMsgCycleTime" BO_ 532 10;
BA_ "VFrameFormat" BO_ 532 14;
BA_ "sigSecLevel"  SG_ 532 VCU_214_CheckSum "";
BA_ "sigSecLevel"  SG_ 532 VCU_214_AliveCounter "";
BA_ "sigSecLevel"  SG_ 532 VCU_RdyLamp "";
BA_ "sigSecLevel"  SG_ 532 VCU_GearSigVld "";
BA_ "sigSecLevel"  SG_ 532 VCU_GearSig "";
BA_ "sigSecLevel"  SG_ 532 VCU_DrvModSig "";
BA_ "GenMsgCycleTime" BO_ 1317 100;
BA_ "VFrameFormat" BO_ 1317 14;
BA_ "sigSecLevel"  SG_ 1317 EHU_525_CheckSum "";
BA_ "sigSecLevel"  SG_ 1317 EHU_525_AliveCounter "";
BA_ "sigSecLevel"  SG_ 1317 EHU_GPSLongi "";
BA_ "sigSecLevel"  SG_ 1317 EHU_GPSLati "";
BA_ "GenMsgCycleTime" BO_ 822 100;
BA_ "VFrameFormat" BO_ 822 14;
BA_ "sigSecLevel"  SG_ 822 EHU_336_Checksum "";
BA_ "sigSecLevel"  SG_ 822 EHU_336_AliveCounter "";
BA_ "GenSigStartValue" SG_ 822 EHU_SpdLimOffs 15;
BA_ "sigSecLevel"  SG_ 822 EHU_SpdLimOffs "";
BA_ "GenMsgCycleTime" BO_ 1318 100;
BA_ "VFrameFormat" BO_ 1318 14;
BA_ "sigSecLevel"  SG_ 1318 EHU_IntegtCrsSwt "";
BA_ "sigSecLevel"  SG_ 1318 EHU_IntegtCrsModSet "";
BA_ "sigSecLevel"  SG_ 1318 EHU_LaneSprtSwt "";
BA_ "sigSecLevel"  SG_ 1318 EHU_LaneSprtTypSet "";
BA_ "sigSecLevel"  SG_ 1318 EHU_FCWFCTASwt "";
BA_ "sigSecLevel"  SG_ 1318 EHU_AEBFCTBSwt "";
BA_ "sigSecLevel"  SG_ 1318 EHU_ESSSwt "";
BA_ "sigSecLevel"  SG_ 1318 EHU_LDWAlrmTypReq "";
BA_ "sigSecLevel"  SG_ 1318 EHU_ADASSnvtySet "";
BA_ "sigSecLevel"  SG_ 1318 EHU_HiwayExitAuxReq "";
BA_ "sigSecLevel"  SG_ 1318 EHU_HiwayExitAuxSwt "";
BA_ "GenSigStartValue" SG_ 1318 EHU_VoiceSpdRgln_ADAS 255;
BA_ "sigSecLevel"  SG_ 1318 EHU_VoiceSpdRgln_ADAS "";
BA_ "GenMsgCycleTime" BO_ 1329 100;
BA_ "VFrameFormat" BO_ 1329 14;
BA_ "sigSecLevel"  SG_ 1329 ICM_TotMilgVld_ODO "";
BA_ "sigSecLevel"  SG_ 1329 ICM_TotMilg_ODO "";
BA_ "sigSecLevel"  SG_ 1329 ICM_DispVehSpd "";
BA_ "sigSecLevel"  SG_ 1329 ICM_DispVehSpdUnit "";
BA_ "sigSecLevel"  SG_ 1329 ICM_ADASSigFlt "";
BA_ "sigSecLevel"  SG_ 1329 ICM_DispFlt "";
BA_ "GenMsgCycleTime" BO_ 1328 100;
BA_ "VFrameFormat" BO_ 1328 14;
BA_ "sigSecLevel"  SG_ 1328 EHU_NavCtryCod "";
BA_ "sigSecLevel"  SG_ 1328 EHU_NavRoadTyp "";
BA_ "sigSecLevel"  SG_ 1328 EHU_NavSpdLimUnit "";
BA_ "sigSecLevel"  SG_ 1328 EHU_NavSpdLimSts "";
BA_ "sigSecLevel"  SG_ 1328 EHU_NavSpdLim "";
BA_ "sigSecLevel"  SG_ 1328 EHU_NavSpdLimExitDst "";
BA_ "GenMsgCycleTime" BO_ 596 20;
BA_ "VFrameFormat" BO_ 596 14;
BA_ "sigSecLevel"  SG_ 596 ADAS_254_CheckSum "";
BA_ "sigSecLevel"  SG_ 596 ADAS_254_AliveCounter "";
BA_ "sigSecLevel"  SG_ 596 ADAS_TqReq_ACC "";
BA_ "sigSecLevel"  SG_ 596 ADAS_Sts_ACC "";
BA_ "GenSigStartValue" SG_ 596 ADAS_WhlTq_ACC 32768;
BA_ "sigSecLevel"  SG_ 596 ADAS_WhlTq_ACC "";
BA_ "sigSecLevel"  SG_ 596 ADAS_TarA_ACC "";
BA_ "sigSecLevel"  SG_ 596 ADAS_DecelToStopReq_ACC "";
BA_ "sigSecLevel"  SG_ 596 ADAS_TarAReq_ACC "";
BA_ "sigSecLevel"  SG_ 596 ADAS_DrvOffReq_ACC "";
BA_ "GenMsgCycleTime" BO_ 448 10;
BA_ "VFrameFormat" BO_ 448 14;
BA_ "sigSecLevel"  SG_ 448 ADAS_1C0_CheckSum "";
BA_ "sigSecLevel"  SG_ 448 ADAS_1C0_AliveCounter "";
BA_ "sigSecLevel"  SG_ 448 ADAS_LatMtnCtrlSts "";
BA_ "GenSigStartValue" SG_ 448 ADAS_SteerTqReq 800;
BA_ "sigSecLevel"  SG_ 448 ADAS_SteerTqReq "";
BA_ "sigSecLevel"  SG_ 448 ADAS_WarnVbrnReq "";
BA_ "sigSecLevel"  SG_ 448 ADAS_LatMtnTypExed "";
BA_ "sigSecLevel"  SG_ 448 ADAS_LeTrunLampReq "";
BA_ "sigSecLevel"  SG_ 448 ADAS_RiTrunLampReq "";
BA_ "GenMsgCycleTime" BO_ 812 50;
BA_ "VFrameFormat" BO_ 812 14;
BA_ "sigSecLevel"  SG_ 812 ADAS_Sts_LKA "";
BA_ "sigSecLevel"  SG_ 812 ADAS_Sts_TJAICA "";
BA_ "sigSecLevel"  SG_ 812 ADAS_FCWSnvty "";
BA_ "sigSecLevel"  SG_ 812 ADAS_ADASSnvtySetFb "";
BA_ "sigSecLevel"  SG_ 812 ADAS_SysWarnTyp "";
BA_ "sigSecLevel"  SG_ 812 ADAS_Sts_ELK_re "";
BA_ "sigSecLevel"  SG_ 812 ADAS_HandsOffTakeOverReq "";
BA_ "sigSecLevel"  SG_ 812 ADAS_IntvMod_ELK "";
BA_ "sigSecLevel"  SG_ 812 ADAS_IntvDir_ELK "";
BA_ "sigSecLevel"  SG_ 812 ADAS_Sts_RDP "";
BA_ "sigSecLevel"  SG_ 812 ADAS_Sts_LDW "";
BA_ "sigSecLevel"  SG_ 812 ADAS_AudioWarn "";
BA_ "sigSecLevel"  SG_ 812 ADAS_LatMtnColor "";
BA_ "sigSecLevel"  SG_ 812 ADAS_DispReq "";
BA_ "sigSecLevel"  SG_ 812 ADAS_Sts_ELK_oc "";
BA_ "sigSecLevel"  SG_ 812 ADAS_Sts_ELK_ot "";
BA_ "GenMsgCycleTime" BO_ 828 50;
BA_ "VFrameFormat" BO_ 828 14;
BA_ "sigSecLevel"  SG_ 828 ADAS_Warn_FCW "";
BA_ "sigSecLevel"  SG_ 828 ADAS_WarnTyp_FCWAEB "";
BA_ "sigSecLevel"  SG_ 828 ADAS_Sts_FCW "";
BA_ "sigSecLevel"  SG_ 828 ADAS_Sts_AEB "";
BA_ "GenMsgCycleTime" BO_ 830 50;
BA_ "VFrameFormat" BO_ 830 14;
BA_ "sigSecLevel"  SG_ 830 MRR_FrntSnsrFlt "";
BA_ "sigSecLevel"  SG_ 830 MRR_FrntSnsrBli "";
BA_ "GenMsgCycleTime" BO_ 838 50;
BA_ "VFrameFormat" BO_ 838 14;
BA_ "sigSecLevel"  SG_ 838 ADAS_FrntTar1X_ACC "";
BA_ "GenSigStartValue" SG_ 838 ADAS_FrntTar1Y_ACC 127;
BA_ "sigSecLevel"  SG_ 838 ADAS_FrntTar1Y_ACC "";
BA_ "sigSecLevel"  SG_ 838 ADAS_FrntTar2X_ACC "";
BA_ "GenSigStartValue" SG_ 838 ADAS_FrntTar2Y_ACC 127;
BA_ "sigSecLevel"  SG_ 838 ADAS_FrntTar2Y_ACC "";
BA_ "sigSecLevel"  SG_ 838 ADAS_LeFrntTarX_ACC "";
BA_ "GenSigStartValue" SG_ 838 ADAS_LeFrntTarY_ACC 127;
BA_ "sigSecLevel"  SG_ 838 ADAS_LeFrntTarY_ACC "";
BA_ "sigSecLevel"  SG_ 838 ADAS_RiFrntTarX_ACC "";
BA_ "GenSigStartValue" SG_ 838 ADAS_RiFrntTarY_ACC 127;
BA_ "sigSecLevel"  SG_ 838 ADAS_RiFrntTarY_ACC "";
BA_ "GenMsgCycleTime" BO_ 839 50;
BA_ "VFrameFormat" BO_ 839 14;
BA_ "sigSecLevel"  SG_ 839 ADAS_FrntTar1Typ_ACC "";
BA_ "sigSecLevel"  SG_ 839 ADAS_FrntTar2Typ_ACC "";
BA_ "sigSecLevel"  SG_ 839 ADAS_DispSpdUnit_ACC "";
BA_ "sigSecLevel"  SG_ 839 ADAS_LeFrntTarTyp_ACC "";
BA_ "sigSecLevel"  SG_ 839 ADAS_RiFrntTarTyp_ACC "";
BA_ "sigSecLevel"  SG_ 839 ADAS_OperTxt "";
BA_ "sigSecLevel"  SG_ 839 ADAS_TiGapSet_ACC "";
BA_ "sigSecLevel"  SG_ 839 ADAS_TakeOverReq_ACC "";
BA_ "sigSecLevel"  SG_ 839 ADAS_DispSpd_ACC "";
BA_ "sigSecLevel"  SG_ 839 ADAS_Sts_ACC_ICC "";
BA_ "sigSecLevel"  SG_ 839 ADAS_SpdLimUnit_ASL "";
BA_ "sigSecLevel"  SG_ 839 ADAS_SpdLim_ASL "";
BA_ "sigSecLevel"  SG_ 839 ADAS_SpdLimSts_ASL "";
BA_ "GenMsgCycleTime" BO_ 842 50;
BA_ "VFrameFormat" BO_ 842 14;
BA_ "sigSecLevel"  SG_ 842 ADAS_Sts_HWA "";
BA_ "sigSecLevel"  SG_ 842 ADAS_HiwayExitAuxSts "";
BA_ "sigSecLevel"  SG_ 842 ADAS_ActvBtnDispReq_HEA "";
BA_ "sigSecLevel"  SG_ 842 ADAS_Sts_ALC "";
BA_ "sigSecLevel"  SG_ 842 ADAS_HandsOffTakeOverReq_ALC "";
BA_ "sigSecLevel"  SG_ 842 ADAS_OverMod_ALC "";
BA_ "sigSecLevel"  SG_ 842 ADAS_ALCAudioWarnLe "";
BA_ "sigSecLevel"  SG_ 842 ADAS_LCReturnToLane "";
BA_ "sigSecLevel"  SG_ 842 ADAS_LeLaneOccupied "";
BA_ "sigSecLevel"  SG_ 842 ADAS_RiLaneOccupied "";
BA_ "sigSecLevel"  SG_ 842 ADAS_LeLCArrow "";
BA_ "sigSecLevel"  SG_ 842 ADAS_ALCAudioWarnRi "";
BA_ "sigSecLevel"  SG_ 842 ADAS_LeLaneOccupiedWarn "";
BA_ "sigSecLevel"  SG_ 842 ADAS_RiLaneOccupiedWarn "";
BA_ "sigSecLevel"  SG_ 842 ADAS_ALCTakeOverReq "";
BA_ "sigSecLevel"  SG_ 842 ADAS_LCSysFlt "";
BA_ "sigSecLevel"  SG_ 842 ADAS_TurnLampOff "";
BA_ "sigSecLevel"  SG_ 842 ADAS_CtrlrFlt "";
BA_ "sigSecLevel"  SG_ 842 ADAS_RiLCArrow "";
BA_ "sigSecLevel"  SG_ 842 ADAS_Sts_ESS "";
BA_ "sigSecLevel"  SG_ 842 ADAS_Warn_ESS "";
BA_ "sigSecLevel"  SG_ 842 ADAS_DrvrOccpyReq "";
BA_ "GenMsgCycleTime" BO_ 820 50;
BA_ "VFrameFormat" BO_ 820 14;
BA_ "sigSecLevel"  SG_ 820 MPC_FrntCamBli "";
BA_ "sigSecLevel"  SG_ 820 MPC_FrntCamFlt "";
BA_ "GenMsgCycleTime" BO_ 832 50;
BA_ "VFrameFormat" BO_ 832 14;
BA_ "GenSigStartValue" SG_ 832 ADAS_LaneCrvt 63;
BA_ "sigSecLevel"  SG_ 832 ADAS_LaneCrvt "";
BA_ "sigSecLevel"  SG_ 832 ADAS_LeLineTyp "";
BA_ "sigSecLevel"  SG_ 832 ADAS_RiLineTyp "";
BA_ "sigSecLevel"  SG_ 832 ADAS_LeLineColor "";
BA_ "sigSecLevel"  SG_ 832 ADAS_RiLineColor "";
BA_ "GenSigStartValue" SG_ 832 ADAS_LeLineDst 62;
BA_ "sigSecLevel"  SG_ 832 ADAS_LeLineDst "";
BA_ "GenSigStartValue" SG_ 832 ADAS_RiLineDst 62;
BA_ "sigSecLevel"  SG_ 832 ADAS_RiLineDst "";
BA_ "sigSecLevel"  SG_ 832 ADAS_LeLineFlash "";
BA_ "sigSecLevel"  SG_ 832 ADAS_RiLineFlash "";
BA_ "sigSecLevel"  SG_ 832 ADAS_ESSSwtFb "";
BA_ "sigSecLevel"  SG_ 832 ADAS_IntegtCrsSwtFb "";
BA_ "sigSecLevel"  SG_ 832 ADAS_IntegtCrsModSetFb "";
BA_ "sigSecLevel"  SG_ 832 ADAS_LaneSprtSwtFb "";
BA_ "sigSecLevel"  SG_ 832 ADAS_LaneSprtTypSetFb "";
BA_ "sigSecLevel"  SG_ 832 ADAS_FCWFCTASwtFb "";
BA_ "sigSecLevel"  SG_ 832 ADAS_AEBFCTBSwtFb "";
BA_ "sigSecLevel"  SG_ 832 ADAS_FltIndcr "";
BA_ "sigSecLevel"  SG_ 832 ADAS_VoiceSpdRglnFb "";
BA_ "sigSecLevel"  SG_ 832 ADAS_IntegtCrsFltTxt "";
BA_ "sigSecLevel"  SG_ 832 ADAS_LaneSprtFltTxt "";
BA_ "sigSecLevel"  SG_ 832 ADAS_FwdWarnFltTxt "";
BA_ "sigSecLevel"  SG_ 832 ADAS_IntecnFltTxt "";
BA_ "sigSecLevel"  SG_ 832 ADAS_ACCIconDisp "";
BA_ "GenMsgCycleTime" BO_ 824 50;
BA_ "VFrameFormat" BO_ 824 14;
BA_ "sigSecLevel"  SG_ 824 CMRR_RL_LeWarn_LCA "";
BA_ "sigSecLevel"  SG_ 824 CMRR_RL_SnsrFlt "";
BA_ "sigSecLevel"  SG_ 824 CMRR_RL_SnsrBli "";
BA_ "sigSecLevel"  SG_ 824 CMRR_RL_LeWarn_LCA_ELK "";
BA_ "sigSecLevel"  SG_ 824 CMRR_RL_SDASts "";
BA_ "sigSecLevel"  SG_ 824 CMRR_RL_SDAWarn "";
BA_ "GenMsgCycleTime" BO_ 606 20;
BA_ "VFrameFormat" BO_ 606 14;
BA_ "sigSecLevel"  SG_ 606 CMRR_FR_FrntLeSnsrFlt "";
BA_ "sigSecLevel"  SG_ 606 CMRR_FR_FrntLeSnsrBli "";
BA_ "sigSecLevel"  SG_ 606 CMRR_FR_SDASts "";
BA_ "sigSecLevel"  SG_ 606 CMRR_FR_SDAWarn "";
BA_ "GenMsgCycleTime" BO_ 604 20;
BA_ "VFrameFormat" BO_ 604 14;
BA_ "sigSecLevel"  SG_ 604 CMRR_FL_FrntLeSnsrFlt "";
BA_ "sigSecLevel"  SG_ 604 CMRR_FL_FrntLeSnsrBli "";
BA_ "sigSecLevel"  SG_ 604 CMRR_FL_SDASts "";
BA_ "sigSecLevel"  SG_ 604 CMRR_FL_SDAWarn "";
BA_ "GenMsgCycleTime" BO_ 826 50;
BA_ "VFrameFormat" BO_ 826 14;
BA_ "sigSecLevel"  SG_ 826 CMRR_RR_RiWarn_LCA "";
BA_ "sigSecLevel"  SG_ 826 CMRR_RR_SnsrFlt "";
BA_ "sigSecLevel"  SG_ 826 CMRR_RR_SnsrBli "";
BA_ "sigSecLevel"  SG_ 826 CMRR_RR_LCASwtFb "";
BA_ "sigSecLevel"  SG_ 826 CMRR_RR_RiWarn_LCA_ELK "";
BA_ "sigSecLevel"  SG_ 826 CMRR_RR_SDAWarn "";
BA_ "sigSecLevel"  SG_ 826 CMRR_RR_SDASts "";
BA_ "GenMsgCycleTime" BO_ 819 50;
BA_ "VFrameFormat" BO_ 819 14;
BA_ "sigSecLevel"  SG_ 819 PEPS_333_CheckSum "";
BA_ "sigSecLevel"  SG_ 819 PEPS_333_AliveCounter "";
BA_ "sigSecLevel"  SG_ 819 PEPS_PwrMod "";
BA_ "sigSecLevel"  SG_ 819 PEPS_PwrModVld "";
BA_ "GenMsgCycleTime" BO_ 1417 500;
BA_ "VFrameFormat" BO_ 1417 14;
BA_ "sigSecLevel"  SG_ 1417 TPMS_TirePosn "";
BA_ "sigSecLevel"  SG_ 1417 TPMS_SngTirePSts "";
BA_ "GenMsgCycleTime" BO_ 1319 100;
BA_ "VFrameFormat" BO_ 1319 14;
BA_ "GenSigStartValue" SG_ 1319 EHU_DrvrSts 4;
BA_ "sigSecLevel"  SG_ 1319 EHU_DrvrSts "";
BA_ "GenSigStartValue" SG_ 1319 EHU_DrvrOccpy 2;
BA_ "sigSecLevel"  SG_ 1319 EHU_DrvrOccpy "";
BA_ "GenMsgCycleTime" BO_ 432 20;
BA_ "VFrameFormat" BO_ 432 14;
BA_ "sigSecLevel"  SG_ 432 APA_1B0_CheckSum "";
BA_ "sigSecLevel"  SG_ 432 APA_1B0_AliveCounter "";
BA_ "sigSecLevel"  SG_ 432 APA_Sts "";
BA_ "GenMsgCycleTime" BO_ 658 20;
BA_ "VFrameFormat" BO_ 658 14;
BA_ "sigSecLevel"  SG_ 658 APA_292_CheckSum "";
BA_ "sigSecLevel"  SG_ 658 APA_292_AliveCounter "";
BA_ "sigSecLevel"  SG_ 658 APA_CrtPrkgTyp "";
BA_ "GenMsgCycleTime" BO_ 1368 100;
BA_ "VFrameFormat" BO_ 1368 14;
BA_ "sigSecLevel"  SG_ 1368 APA_558_CheckSum "";
BA_ "sigSecLevel"  SG_ 1368 APA_558_AliveCounter "";
BA_ "sigSecLevel"  SG_ 1368 APA_Sts_PAS "";
BA_ "GenMsgCycleTime" BO_ 672 20;
BA_ "VFrameFormat" BO_ 672 14;
BA_ "sigSecLevel"  SG_ 672 APA_FMEBSts "";
BA_ "sigSecLevel"  SG_ 672 APA_RMEBSts "";
BA_ "GenMsgCycleTime" BO_ 1300 100;
BA_ "VFrameFormat" BO_ 1300 14;
BA_ "sigSecLevel"  SG_ 1300 MFS_LeRollPress "";
BA_ "sigSecLevel"  SG_ 1300 MFS_RiRollPress "";
BA_ "GenMsgCycleTime" BO_ 592 20;
BA_ "VFrameFormat" BO_ 592 14;
BA_ "sigSecLevel"  SG_ 592 EHU_SegFuncRoadClass "";
BA_ "sigSecLevel"  SG_ 592 EHU_SegEffSpdLmtType "";
BA_ "GenMsgCycleTime" BO_ 593 20;
BA_ "VFrameFormat" BO_ 593 14;
BA_ "sigSecLevel"  SG_ 593 EHU_StubFuncRoadClass "";
BA_ "sigSecLevel"  SG_ 593 EHU_StubTurnAngl "";
BA_ "GenMsgCycleTime" BO_ 442 10;
BA_ "VFrameFormat" BO_ 442 14;
BA_ "sigSecLevel"  SG_ 442 VCU_1BA_CheckSum "";
BA_ "sigSecLevel"  SG_ 442 VCU_1BA_AliveCounter "";
BA_ "sigSecLevel"  SG_ 442 VCU_DrvrAPSPerc "";
BA_ "sigSecLevel"  SG_ 442 VCU_DrvrAPSPercVld "";
BA_ "sigSecLevel"  SG_ 442 VCU_WhlTqActVld "";
BA_ "GenSigStartValue" SG_ 442 VCU_WhlTqAct 32768;
BA_ "sigSecLevel"  SG_ 442 VCU_WhlTqAct "";
BA_ "GenMsgCycleTime" BO_ 440 20;
BA_ "VFrameFormat" BO_ 440 14;
BA_ "GenSigStartValue" SG_ 440 ESP_RoadSlop 1000;
BA_ "sigSecLevel"  SG_ 440 ESP_RoadSlop "";
BA_ "GenMsgCycleTime" BO_ 1625 1000;
BA_ "VFrameFormat" BO_ 1625 14;
BA_ "sigSecLevel"  SG_ 1625 ADAS_SwVersS "";
BA_ "sigSecLevel"  SG_ 1625 ADAS_PartVers "";
BA_ "sigSecLevel"  SG_ 1625 ADAS_HwVers "";
BA_ "sigSecLevel"  SG_ 1625 ADAS_SwVersM "";
BA_ "GenMsgCycleTime" BO_ 1153 100;
BA_ "VFrameFormat" BO_ 1153 14;
BA_ "sigSecLevel"  SG_ 1153 ADAS_ECUUnexpectedRst "";
BA_ "sigSecLevel"  SG_ 1153 ADAS_ChkBattVoltFlt "";
BA_ "sigSecLevel"  SG_ 1153 ADAS_1V25UnderOrOverVolt "";
BA_ "sigSecLevel"  SG_ 1153 ADAS_3V3UnderOrOverVolt "";
BA_ "sigSecLevel"  SG_ 1153 ADAS_5V0UnderOrOverVolt "";
BA_ "sigSecLevel"  SG_ 1153 ADAS_BusHwErr "";
BA_ "sigSecLevel"  SG_ 1153 ADAS_BusHwErr_MPC "";
BA_ "sigSecLevel"  SG_ 1153 ADAS_BusHwErr_MRR "";
BA_ "sigSecLevel"  SG_ 1153 ADAS_BusHwErr_CMRR_FL "";
BA_ "sigSecLevel"  SG_ 1153 ADAS_BusDiagHwErr_CMRR_FR "";
BA_ "sigSecLevel"  SG_ 1153 ADAS_ChkInvldSig_MPC "";
BA_ "sigSecLevel"  SG_ 1153 ADAS_ChkInvldSig_CMRR_RL "";
BA_ "sigSecLevel"  SG_ 1153 ADAS_ChkInvldSig_CMRR_FR "";
BA_ "sigSecLevel"  SG_ 1153 ADAS_ChkInvldSig_CMRR_FL "";
BA_ "sigSecLevel"  SG_ 1153 ADAS_ChkInvldSig_CMRR_RR "";
BA_ "sigSecLevel"  SG_ 1153 ADAS_ChkInvldSig_MRR "";
BA_ "sigSecLevel"  SG_ 1153 ADAS_ChkInvldSig_ESP "";
BA_ "sigSecLevel"  SG_ 1153 ADAS_ChkInvldSig_SDM "";
BA_ "sigSecLevel"  SG_ 1153 ADAS_ChkInvldSig_EPS "";
BA_ "sigSecLevel"  SG_ 1153 ADAS_ChkInvldSig_iBooster "";
BA_ "sigSecLevel"  SG_ 1153 ADAS_ChkInvldSig_YRS "";
BA_ "sigSecLevel"  SG_ 1153 ADAS_ChkInvldSig_BCM "";
BA_ "sigSecLevel"  SG_ 1153 ADAS_ChkInvldSig_ECC "";
BA_ "sigSecLevel"  SG_ 1153 ADAS_ChkInvldSig_TBOX "";
BA_ "sigSecLevel"  SG_ 1153 ADAS_ChkInvldSig_MCU_F "";
BA_ "sigSecLevel"  SG_ 1153 ADAS_ChkInvldSig_MCU_R "";
BA_ "sigSecLevel"  SG_ 1153 ADAS_ChkInvldSig_PLG "";
BA_ "sigSecLevel"  SG_ 1153 ADAS_ChkInvldSig_CIM "";
BA_ "sigSecLevel"  SG_ 1153 ADAS_ChkInvldSig_VCU "";
BA_ "sigSecLevel"  SG_ 1153 ADAS_ChkInvldSig_ICC "";
BA_ "sigSecLevel"  SG_ 1153 ADAS_ChkInvldSig_PEPS "";
BA_ "sigSecLevel"  SG_ 1153 ADAS_ChkInvldSig_TPMS "";
BA_ "sigSecLevel"  SG_ 1153 ADAS_ChkInvldSig_AVAP "";
BA_ "sigSecLevel"  SG_ 1153 ADAS_ComE2EFlt "";
BA_ "sigSecLevel"  SG_ 1153 ADAS_ComLostFlt_MPC "";
BA_ "sigSecLevel"  SG_ 1153 ADAS_ComLostFlt_CMRR_RL "";
BA_ "sigSecLevel"  SG_ 1153 ADAS_ComLostFlt_CMRR_FL "";
BA_ "sigSecLevel"  SG_ 1153 ADAS_ComLostFlt_CMRR_RR "";
BA_ "sigSecLevel"  SG_ 1153 ADAS_ComLostFlt_CMRR_FR "";
BA_ "sigSecLevel"  SG_ 1153 ADAS_ComLostFlt_MRR "";
BA_ "sigSecLevel"  SG_ 1153 ADAS_ComLostFlt_ESP "";
BA_ "sigSecLevel"  SG_ 1153 ADAS_ComLostFlt_SDM "";
BA_ "sigSecLevel"  SG_ 1153 ADAS_ComLostFlt_EPS "";
BA_ "sigSecLevel"  SG_ 1153 ADAS_ComLostFlt_iBooster "";
BA_ "sigSecLevel"  SG_ 1153 ADAS_ComLostFlt_YRS "";
BA_ "sigSecLevel"  SG_ 1153 ADAS_ComLostFlt_BCM "";
BA_ "sigSecLevel"  SG_ 1153 ADAS_ComLostFlt_ECC "";
BA_ "sigSecLevel"  SG_ 1153 ADAS_ComLostFlt_TBOX "";
BA_ "sigSecLevel"  SG_ 1153 ADAS_ComLostFlt_MCU_F "";
BA_ "sigSecLevel"  SG_ 1153 ADAS_ComLostFlt_MCU_R "";
BA_ "sigSecLevel"  SG_ 1153 ADAS_ComLostFlt_PLG "";
BA_ "sigSecLevel"  SG_ 1153 ADAS_ComLostFlt_CIM "";
BA_ "sigSecLevel"  SG_ 1153 ADAS_ComLostFlt_VCU "";
BA_ "sigSecLevel"  SG_ 1153 ADAS_ComLostFlt_ICC "";
BA_ "sigSecLevel"  SG_ 1153 ADAS_ComLostFlt_PEPS "";
BA_ "sigSecLevel"  SG_ 1153 ADAS_ComLostFlt_TPMS "";
BA_ "sigSecLevel"  SG_ 1153 ADAS_ComLostFlt_AVAP "";
BA_ "sigSecLevel"  SG_ 1153 ADAS_ChkPublicCANBusOff "";
BA_ "sigSecLevel"  SG_ 1153 ADAS_MstRAMTestErr "";
BA_ "sigSecLevel"  SG_ 1153 ADAS_MstNVRAMTestErr "";
BA_ "sigSecLevel"  SG_ 1153 ADAS_NVMChipErr "";
BA_ "sigSecLevel"  SG_ 1153 ADAS_NVMStructErr "";
BA_ "sigSecLevel"  SG_ 1153 ADAS_MstWdgErr "";
BA_ "sigSecLevel"  SG_ 1153 ADAS_MstSOPTErr "";
BA_ "GenMsgCycleTime" BO_ 1154 100;
BA_ "VFrameFormat" BO_ 1154 14;
BA_ "sigSecLevel"  SG_ 1154 ADAS_MstHwstartupErr "";
BA_ "sigSecLevel"  SG_ 1154 ADAS_MstHwCycTest "";
BA_ "sigSecLevel"  SG_ 1154 ADAS_EOLCalOutOfRng "";
BA_ "sigSecLevel"  SG_ 1154 ADAS_ECUTFlt "";
BA_ "sigSecLevel"  SG_ 1154 ADAS_PwrModFlt "";
BA_ "sigSecLevel"  SG_ 1154 ADAS_ComLostFlt_MFS "";
BA_ "sigSecLevel"  SG_ 1154 ADAS_PrivateCANComE2EFlt_MPC "";
BA_ "sigSecLevel"  SG_ 1154 ADAS_PrivateCANComE2EFlt_MRR "";
BA_ "sigSecLevel"  SG_ 1154 ADAS_PrivateCANComE2EFlt_CMRR_FL "";
BA_ "sigSecLevel"  SG_ 1154 ADAS_PrivateCANComE2EFlt_CMRR_FR "";
BA_ "sigSecLevel"  SG_ 1154 ADAS_PrivateCANComE2EFlt_CMRR_RL "";
BA_ "sigSecLevel"  SG_ 1154 ADAS_PrivateCANComE2EFlt_CMRR_RR "";
BA_ "sigSecLevel"  SG_ 1154 ADAS_PrivateCANComLostFlt_MPC "";
BA_ "sigSecLevel"  SG_ 1154 ADAS_PrivateCANComLostFlt_MRR "";
BA_ "sigSecLevel"  SG_ 1154 ADAS_PrivateCANComLost_CMRR_FL "";
BA_ "sigSecLevel"  SG_ 1154 ADAS_PrivateCANComLost_CMRR_FR "";
BA_ "sigSecLevel"  SG_ 1154 ADAS_PrivateCANComLost_CMRR_RL "";
BA_ "sigSecLevel"  SG_ 1154 ADAS_PrivateCANComLost_CMRR_RR "";
BA_ "sigSecLevel"  SG_ 1154 ADAS_PERChkIntFltInfo "";
BA_ "sigSecLevel"  SG_ 1154 ADAS_HWAActvFlg "";
BA_ "sigSecLevel"  SG_ 1154 ADAS_HWASucFlg "";
BA_ "GenMsgCycleTime" BO_ 1162 100;
BA_ "VFrameFormat" BO_ 1162 14;
BA_ "sigSecLevel"  SG_ 1162 ADAS_RDPActvFlg "";
BA_ "sigSecLevel"  SG_ 1162 ADAS_ELKActvFlg "";
BA_ "DiagState" BO_ 1966 1;
BA_ "DiagResponse" BO_ 1966 1;
BA_ "GenMsgSendType" BO_ 1966 1;
BA_ "VFrameFormat" BO_ 1966 14;
BA_ "DiagState" BO_ 1958 1;
BA_ "DiagResponse" BO_ 1958 1;
BA_ "GenMsgSendType" BO_ 1958 1;
BA_ "VFrameFormat" BO_ 1958 14;
BA_ "DiagState" BO_ 2015 1;
BA_ "DiagResponse" BO_ 2015 1;
BA_ "GenMsgSendType" BO_ 2015 1;
BA_ "VFrameFormat" BO_ 2015 14;
VAL_ 596 ADAS_TqReq_ACC 1 "Request 有要求" 0 "No Request 无要求" ;
VAL_ 596 ADAS_Sts_ACC 15 "Reserved" 14 "Reserved" 13 "Reserved" 12 "Reserved" 11 "Reserved" 10 "ACTIVE_INTERVAL" 9 "Irreversible_Failure" 8 "Reversible_Failure" 7 "Stand Wait" 6 "Stand Active" 5 "Override" 4 "Brake Only" 3 "Active_Control" 2 "Standby" 1 "Passive" 0 "Off" ;
VAL_ 596 ADAS_DecelToStopReq_ACC 1 "Request 有要求" 0 "No Request 无要求" ;
VAL_ 596 ADAS_TarAReq_ACC 1 "Request 有要求" 0 "No Request 无要求" ;
VAL_ 596 ADAS_DrvOffReq_ACC 1 "Request 有要求" 0 "No Request 无要求" ;
VAL_ 448 ADAS_LatMtnCtrlSts 1 "Active" 0 "Inactive" ;
VAL_ 448 ADAS_WarnVbrnReq 1 "Active" 0 "Inactive" ;
VAL_ 448 ADAS_LatMtnTypExed 7 "Reserved" 6 "Reserved" 5 "Reserved" 4 "Reserved" 3 "Reserved" 2 "Emergency" 1 "Comfort" 0 "Off" ;
VAL_ 448 ADAS_LeTrunLampReq 3 "Reserved" 2 "Request Off" 1 "Request On" 0 "No Request" ;
VAL_ 448 ADAS_RiTrunLampReq 3 "Reserved" 2 "Request Off" 1 "Request On" 0 "No Request" ;
VAL_ 812 ADAS_Sts_LKA 7 "Reserved" 6 "Reserved" 5 "Reserved" 4 "Fault" 3 "Active" 2 "Standby" 1 "Passive" 0 "Off" ;
VAL_ 812 ADAS_Sts_TJAICA 7 "Reserved" 6 "Reserved" 5 "Reserved" 4 "Fault" 3 "Active" 2 "Standby" 1 "Passive" 0 "Off" ;
VAL_ 812 ADAS_FCWSnvty 3 "High Sensitivity" 2 "Medium Sensitivity" 1 "Low Sensitivity" 0 "Default" ;
VAL_ 812 ADAS_ADASSnvtySetFb 3 "Reserved" 2 "High 正常模式" 1 "Low 新手模式" 0 "Default" ;
VAL_ 812 ADAS_SysWarnTyp 7 "Reserved" 6 "Reserved" 5 "Reserved" 4 "Reserved" 3 "震动模式" 2 "Invalid" 1 "声光震动报警模式" 0 "声光报警模式" ;
VAL_ 812 ADAS_Sts_ELK_re 7 "Reserved" 6 "Reserved" 5 "Reserved" 4 "Fault" 3 "Active" 2 "Standby" 1 "Passive" 0 "Off" ;
VAL_ 812 ADAS_HandsOffTakeOverReq 1 "Active" 0 "Inactive" ;
VAL_ 812 ADAS_IntvMod_ELK 3 "Oncoming" 2 "Overtaking" 1 "Road Edge" 0 "Off" ;
VAL_ 812 ADAS_IntvDir_ELK 3 "Reserved" 2 "Right" 1 "Left" 0 "Undefined" ;
VAL_ 812 ADAS_Sts_RDP 7 "Reserved" 6 "Reserved" 5 "Reserved" 4 "Fault" 3 "Active" 2 "Standby" 1 "Passive" 0 "Off" ;
VAL_ 812 ADAS_Sts_LDW 7 "Reserved" 6 "Reserved" 5 "Reserved" 4 "Fault" 3 "Active" 2 "Standby" 1 "Passive" 0 "Off" ;
VAL_ 812 ADAS_AudioWarn 1 "Active" 0 "Inactive" ;
VAL_ 812 ADAS_LatMtnColor 7 "Reserved" 6 "Reserved" 5 "黄色变大闪烁" 4 "Fault(No Display)" 3 "Active(Blue)" 2 "Standby(White)" 1 "Passive(No Display)" 0 "Off(No Display)" ;
VAL_ 812 ADAS_DispReq 3 "Reserved" 2 "Display" 1 "No Display" 0 "Default" ;
VAL_ 812 ADAS_Sts_ELK_oc 7 "Reserved" 6 "Reserved" 5 "Reserved" 4 "Fault" 3 "Active" 2 "Standby" 1 "Passive" 0 "Off" ;
VAL_ 812 ADAS_Sts_ELK_ot 7 "Reserved" 6 "Reserved" 5 "Reserved" 4 "Fault" 3 "Active" 2 "Standby" 1 "Passive" 0 "Off" ;
VAL_ 828 ADAS_Warn_FCW 3 "Acutewarning" 2 "Prewarning 预警告" 1 "Latent Warning" 0 "No Warning 无警告" ;
VAL_ 828 ADAS_WarnTyp_FCWAEB 7 "Reserved" 6 "Bus" 5 "Cyclist" 4 "Truck" 3 "Car" 2 "Pedestrian" 1 "Unknown" 0 "Reserved" ;
VAL_ 828 ADAS_Sts_FCW 7 "Reserved" 6 "Reserved" 5 "Reserved" 4 "Fault" 3 "Active" 2 "Standby" 1 "Reserved" 0 "Off" ;
VAL_ 828 ADAS_Sts_AEB 7 "Reserved" 6 "Reserved" 5 "Reserved" 4 "Fault" 3 "Active" 2 "Standby" 1 "Reserved" 0 "Off" ;
VAL_ 838 ADAS_FrntTar1X_ACC 255 "Invalid" ;
VAL_ 838 ADAS_FrntTar1Y_ACC 255 "Invalid" ;
VAL_ 838 ADAS_FrntTar2X_ACC 255 "Invalid" ;
VAL_ 838 ADAS_FrntTar2Y_ACC 255 "Invalid" ;
VAL_ 838 ADAS_LeFrntTarX_ACC 255 "Invalid" ;
VAL_ 838 ADAS_LeFrntTarY_ACC 255 "Invalid" ;
VAL_ 838 ADAS_RiFrntTarX_ACC 255 "Invalid" ;
VAL_ 838 ADAS_RiFrntTarY_ACC 255 "Invalid" ;
VAL_ 839 ADAS_FrntTar1Typ_ACC 7 "Reserved" 6 "Motor/Bicycle-following target" 5 "Truck-following target" 4 "Car-following target" 3 "Motor/Bicycle" 2 "Truck" 1 "Car" 0 "No Display" ;
VAL_ 839 ADAS_FrntTar2Typ_ACC 7 "Reserved" 6 "Motor/Bicycle-following target" 5 "Truck-following target" 4 "Car-following target" 3 "Motor/Bicycle" 2 "Truck" 1 "Car" 0 "No Display" ;
VAL_ 839 ADAS_DispSpdUnit_ACC 1 "MPH" 0 "KMH" ;
VAL_ 839 ADAS_LeFrntTarTyp_ACC 7 "Reserved" 6 "Motor/Bicycle-following target" 5 "Truck-following target" 4 "Car-following target" 3 "Motor/Bicycle" 2 "Truck" 1 "Car" 0 "No Display" ;
VAL_ 839 ADAS_RiFrntTarTyp_ACC 7 "Reserved" 6 "Motor/Bicycle-following target" 5 "Truck-following target" 4 "Car-following target" 3 "Motor/Bicycle" 2 "Truck" 1 "Car" 0 "No Display" ;
VAL_ 839 ADAS_OperTxt 15 "智能巡航系统失效" 14 "Reserved" 13 "Reserved" 12 "Reserved" 11 "Reserved" 10 "前车驶离，请起步" 9 "智能巡航系统退出" 8 "智能巡航系统无法激活" 7 "请打开esp后开启智能巡航" 6 "请松开电子驻车后开启智能巡航" 5 "请关后尾门后开启智能巡航" 4 "请关前舱盖后开启智能巡航" 3 "请关车门后开启智能巡航" 2 "请挂前进档后开启智能巡航" 1 "请系安全带后开启智能巡航" 0 "Default" ;
VAL_ 839 ADAS_TiGapSet_ACC 7 "Invalid" 6 "Reserved 预留" 5 "5 gear 5档" 4 "4 gear 4档" 3 "3 gear 3档" 2 "2 gear 2档" 1 "1 gear 1档" 0 "Inactive/Default" ;
VAL_ 839 ADAS_TakeOverReq_ACC 1 "Request" 0 "No request" ;
VAL_ 839 ADAS_DispSpd_ACC 255 "无显示" 254 "显示" 253 "显示" 252 "显示" 251 "显示" 250 "显示" 249 "显示" 248 "显示" 247 "显示" 246 "显示" 245 "显示" 244 "显示" 243 "显示" 242 "显示" 241 "显示" 240 "显示" 239 "显示" 238 "显示" 237 "显示" 236 "显示" 235 "显示" 234 "显示" 233 "显示" 232 "显示" 231 "显示" 230 "显示" 229 "显示" 228 "显示" 227 "显示" 226 "显示" 225 "显示" 224 "显示" 223 "显示" 222 "显示" 221 "显示" 220 "显示" 219 "显示" 218 "显示" 217 "显示" 216 "显示" 215 "显示" 214 "显示" 213 "显示" 212 "显示" 211 "显示" 210 "显示" 209 "显示" 208 "显示" 207 "显示" 206 "显示" 205 "显示" 204 "显示" 203 "显示" 202 "显示" 201 "显示" 200 "显示" 199 "显示" 198 "显示" 197 "显示" 196 "显示" 195 "显示" 194 "显示" 193 "显示" 192 "显示" 191 "显示" 190 "显示" 189 "显示" 188 "显示" 187 "显示" 186 "显示" 185 "显示" 184 "显示" 183 "显示" 182 "显示" 181 "显示" 180 "显示" 179 "显示" 178 "显示" 177 "显示" 176 "显示" 175 "显示" 174 "显示" 173 "显示" 172 "显示" 171 "显示" 170 "显示" 169 "显示" 168 "显示" 167 "显示" 166 "显示" 165 "显示" 164 "显示" 163 "显示" 162 "显示" 161 "显示" 160 "显示" 159 "显示" 158 "显示" 157 "显示" 156 "显示" 155 "显示" 154 "显示" 153 "显示" 152 "显示" 151 "显示" 150 "显示" 149 "显示" 148 "显示" 147 "显示" 146 "显示" 145 "显示" 144 "显示" 143 "显示" 142 "显示" 141 "显示" 140 "显示" 139 "显示" 138 "显示" 137 "显示" 136 "显示" 135 "显示" 134 "显示" 133 "显示" 132 "显示" 131 "显示" 130 "显示" 129 "显示" 128 "显示" 127 "显示" 126 "显示" 125 "显示" 124 "显示" 123 "显示" 122 "显示" 121 "显示" 120 "显示" 119 "显示" 118 "显示" 117 "显示" 116 "显示" 115 "显示" 114 "显示" 113 "显示" 112 "显示" 111 "显示" 110 "显示" 109 "显示" 108 "显示" 107 "显示" 106 "显示" 105 "显示" 104 "显示" 103 "显示" 102 "显示" 101 "显示" 100 "显示" 99 "显示" 98 "显示" 97 "显示" 96 "显示" 95 "显示" 94 "显示" 93 "显示" 92 "显示" 91 "显示" 90 "显示" 89 "显示" 88 "显示" 87 "显示" 86 "显示" 85 "显示" 84 "显示" 83 "显示" 82 "显示" 81 "显示" 80 "显示" 79 "显示" 78 "显示" 77 "显示" 76 "显示" 75 "显示" 74 "显示" 73 "显示" 72 "显示" 71 "显示" 70 "显示" 69 "显示" 68 "显示" 67 "显示" 66 "显示" 65 "显示" 64 "显示" 63 "显示" 62 "显示" 61 "显示" 60 "显示" 59 "显示" 58 "显示" 57 "显示" 56 "显示" 55 "显示" 54 "显示" 53 "显示" 52 "显示" 51 "显示" 50 "显示" 49 "显示" 48 "显示" 47 "显示" 46 "显示" 45 "显示" 44 "显示" 43 "显示" 42 "显示" 41 "显示" 40 "显示" 39 "显示" 38 "显示" 37 "显示" 36 "显示" 35 "显示" 34 "显示" 33 "显示" 32 "显示" 31 "显示" 30 "显示" 29 "显示" 28 "显示" 27 "显示" 26 "显示" 25 "显示" 24 "显示" 23 "显示" 22 "显示" 21 "显示" 20 "显示" 19 "显示" 18 "显示" 17 "显示" 16 "显示" 15 "显示" 14 "显示" 13 "显示" 12 "显示" 11 "显示" 10 "显示" 9 "显示" 8 "显示" 7 "显示" 6 "显示" 5 "显示" 4 "显示" 3 "显示" 2 "显示" 1 "显示" 0 "显示" ;
VAL_ 839 ADAS_Sts_ACC_ICC 15 "Reserved" 14 "Reserved" 13 "Reserved" 12 "Reserved" 11 "Reserved" 10 "ACTIVE_INTERVAL" 9 "IRREVERSIBLE_FAILURE" 8 "REVERSIBLE_FAILURE" 7 "Stand Wait" 6 "Stand Active" 5 "Override" 4 "Brake Only" 3 "Active_Control" 2 "Standby" 1 "Passive" 0 "Off" ;
VAL_ 839 ADAS_SpdLimUnit_ASL 3 "Reserved" 2 "MPH" 1 "KMH" 0 "Unknown" ;
VAL_ 839 ADAS_SpdLim_ASL 255 "无显示" ;
VAL_ 839 ADAS_SpdLimSts_ASL 7 "Reserved" 6 "Reserved" 5 "IREVERSIBLE_FAILURE" 4 "REVERSIBLE_FAILURE" 3 "OVERRIDE" 2 "ACTIVE" 1 "STANDBY" 0 "OFF" ;
VAL_ 842 ADAS_Sts_HWA 7 "Reserved" 6 "Reserved" 5 "Reserved" 4 "Fault" 3 "Active" 2 "Standby" 1 "Passive" 0 "Off" ;
VAL_ 842 ADAS_HiwayExitAuxSts 7 "Reserved" 6 "Reserved" 5 "Reserved" 4 "Fault" 3 "Active" 2 "Standby" 1 "Passive" 0 "Off" ;
VAL_ 842 ADAS_ActvBtnDispReq_HEA 3 "Reserved" 2 "Flash" 1 "Request" 0 "No Request" ;
VAL_ 842 ADAS_Sts_ALC 15 "Reserved" 14 "Reserved" 13 "Reserved" 12 "Reserved" 11 "Reserved" 10 "Reserved" 9 "Reserved" 8 "Blindness" 7 "Failure" 6 "Take over request to right" 5 "Take over request to left" 4 "Active to right" 3 "Active to left" 2 "Standby" 1 "Passive" 0 "Off" ;
VAL_ 842 ADAS_HandsOffTakeOverReq_ALC 1 "Active" 0 "Inactive" ;
VAL_ 842 ADAS_OverMod_ALC 1 "Driver Override 驾驶员覆盖" 0 "No Override 不覆盖" ;
VAL_ 842 ADAS_ALCAudioWarnLe 1 "Warning" 0 "No Warning" ;
VAL_ 842 ADAS_LCReturnToLane 3 "Reserved" 2 "Reserved" 1 "Display" 0 "No Display" ;
VAL_ 842 ADAS_LeLaneOccupied 1 "Not Active By Obj" 0 "No Obj" ;
VAL_ 842 ADAS_RiLaneOccupied 1 "Not Active By Obj" 0 "No Obj" ;
VAL_ 842 ADAS_LeLCArrow 3 "Reserved" 2 "Display Green" 1 "Display Gray" 0 "No Display" ;
VAL_ 842 ADAS_ALCAudioWarnRi 1 "Warning" 0 "No Warning" ;
VAL_ 842 ADAS_LeLaneOccupiedWarn 1 "Display" 0 "No Display" ;
VAL_ 842 ADAS_RiLaneOccupiedWarn 1 "Display" 0 "No Display" ;
VAL_ 842 ADAS_ALCTakeOverReq 1 "Active" 0 "Inactive" ;
VAL_ 842 ADAS_LCSysFlt 1 "Failure" 0 "No Failure" ;
VAL_ 842 ADAS_TurnLampOff 3 "Reserved" 2 "请关闭右转向灯" 1 "请关闭左转向灯" 0 "No Request" ;
VAL_ 842 ADAS_CtrlrFlt 3 "Reserved" 2 "Irrversible Failure" 1 "Reversible Failure" 0 "No Failure" ;
VAL_ 842 ADAS_RiLCArrow 3 "Reserved" 2 "Display Green" 1 "Display Gray" 0 "No Display" ;
VAL_ 842 ADAS_Sts_ESS 7 "Reserved" 6 "Reserved" 5 "Reserved" 4 "Fault" 3 "Active" 2 "Standby" 1 "Reserved" 0 "Off" ;
VAL_ 842 ADAS_Warn_ESS 3 "Reserved" 2 "Warning Right" 1 "Warning Left" 0 "No Warning" ;
VAL_ 842 ADAS_DrvrOccpyReq 1 "Request" 0 "No Request" ;
VAL_ 832 ADAS_LaneCrvt 127 "No Display" 63 "Straight Lane" ;
VAL_ 832 ADAS_LeLineTyp 3 "Reserved" 2 "Dashed Lane(Alc)" 1 "Solid Lane" 0 "Default" ;
VAL_ 832 ADAS_RiLineTyp 3 "Reserved" 2 "Dashed Lane(Alc)" 1 "Solid Lane" 0 "Default" ;
VAL_ 832 ADAS_LeLineColor 3 "Red" 2 "Blue(Alc)" 1 "White" 0 "Gray" ;
VAL_ 832 ADAS_RiLineColor 3 "Red" 2 "Blue(Alc)" 1 "White" 0 "Gray" ;
VAL_ 832 ADAS_LeLineDst 127 "Invalid" 126 "Invalid" 125 "Invalid" ;
VAL_ 832 ADAS_RiLineDst 127 "Invalid" 126 "Invalid" 125 "Invalid" ;
VAL_ 832 ADAS_LeLineFlash 3 "Reserved" 2 "Reserved" 1 "Flash" 0 "No Flash" ;
VAL_ 832 ADAS_RiLineFlash 3 "Reserved" 2 "Reserved" 1 "Flash" 0 "No Flash" ;
VAL_ 832 ADAS_ESSSwtFb 3 "Fault" 2 "Switch On 开关打开" 1 "Switch Off 开关关闭" 0 "Default 初始值" ;
VAL_ 832 ADAS_IntegtCrsSwtFb 3 "Fault" 2 "Switch On 开关打开" 1 "Switch Off 开关关闭" 0 "Default 初始值" ;
VAL_ 832 ADAS_IntegtCrsModSetFb 3 "HWA" 2 "TJA\ICA" 1 "ACC" 0 "Default 初始值" ;
VAL_ 832 ADAS_LaneSprtSwtFb 3 "Fault" 2 "Switch On 开关打开" 1 "Switch Off 开关关闭" 0 "Default 初始值" ;
VAL_ 832 ADAS_LaneSprtTypSetFb 3 "Reserved" 2 "LDW RDP ELK 纠偏警示" 1 "LDW 警示" 0 "Default 初始值" ;
VAL_ 832 ADAS_FCWFCTASwtFb 3 "Fault" 2 "Switch On 开关打开" 1 "Switch Off 开关关闭" 0 "Default 初始值" ;
VAL_ 832 ADAS_AEBFCTBSwtFb 3 "Fault" 2 "Switch On 开关打开" 1 "Switch Off 开关关闭" 0 "Default 初始值" ;
VAL_ 832 ADAS_FltIndcr 3 "Dynamic Calibration Running" 2 "Fault" 1 "No Fault" 0 "Default" ;
VAL_ 832 ADAS_VoiceSpdRglnFb 3 "Reserved" 2 "Reject" 1 "Ok" 0 "Default" ;
VAL_ 832 ADAS_IntegtCrsFltTxt 1 "智能巡航系统失败" 0 "Default" ;
VAL_ 832 ADAS_LaneSprtFltTxt 1 "车道辅助系统失败" 0 "Default" ;
VAL_ 832 ADAS_FwdWarnFltTxt 1 "前方预警保护系统失败" 0 "Default" ;
VAL_ 832 ADAS_IntecnFltTxt 1 "相关系统故障驾驶辅助系统失效" 0 "Default" ;
VAL_ 832 ADAS_ACCIconDisp 7 "Reserved" 6 "Reserved" 5 "Reserved" 4 "Reserved" 3 "Fault" 2 "Green" 1 "White" 0 "No Display" ;
VAL_ 1153 ADAS_ECUUnexpectedRst 1 "异常" 0 "正常" ;
VAL_ 1153 ADAS_ChkBattVoltFlt 1 "异常" 0 "正常" ;
VAL_ 1153 ADAS_1V25UnderOrOverVolt 1 "异常" 0 "正常" ;
VAL_ 1153 ADAS_3V3UnderOrOverVolt 1 "异常" 0 "正常" ;
VAL_ 1153 ADAS_5V0UnderOrOverVolt 1 "异常" 0 "正常" ;
VAL_ 1153 ADAS_BusHwErr 1 "异常" 0 "正常" ;
VAL_ 1153 ADAS_BusHwErr_MPC 1 "异常" 0 "正常" ;
VAL_ 1153 ADAS_BusHwErr_MRR 1 "异常" 0 "正常" ;
VAL_ 1153 ADAS_BusHwErr_CMRR_FL 1 "异常" 0 "正常" ;
VAL_ 1153 ADAS_BusDiagHwErr_CMRR_FR 1 "异常" 0 "正常" ;
VAL_ 1153 ADAS_ChkInvldSig_MPC 1 "异常" 0 "正常" ;
VAL_ 1153 ADAS_ChkInvldSig_CMRR_RL 1 "异常" 0 "正常" ;
VAL_ 1153 ADAS_ChkInvldSig_CMRR_FR 1 "异常" 0 "正常" ;
VAL_ 1153 ADAS_ChkInvldSig_CMRR_FL 1 "异常" 0 "正常" ;
VAL_ 1153 ADAS_ChkInvldSig_CMRR_RR 1 "异常" 0 "正常" ;
VAL_ 1153 ADAS_ChkInvldSig_MRR 1 "异常" 0 "正常" ;
VAL_ 1153 ADAS_ChkInvldSig_ESP 1 "异常" 0 "正常" ;
VAL_ 1153 ADAS_ChkInvldSig_SDM 1 "异常" 0 "正常" ;
VAL_ 1153 ADAS_ChkInvldSig_EPS 1 "异常" 0 "正常" ;
VAL_ 1153 ADAS_ChkInvldSig_iBooster 1 "异常" 0 "正常" ;
VAL_ 1153 ADAS_ChkInvldSig_YRS 1 "异常" 0 "正常" ;
VAL_ 1153 ADAS_ChkInvldSig_BCM 1 "异常" 0 "正常" ;
VAL_ 1153 ADAS_ChkInvldSig_ECC 1 "异常" 0 "正常" ;
VAL_ 1153 ADAS_ChkInvldSig_TBOX 1 "异常" 0 "正常" ;
VAL_ 1153 ADAS_ChkInvldSig_MCU_F 1 "异常" 0 "正常" ;
VAL_ 1153 ADAS_ChkInvldSig_MCU_R 1 "异常" 0 "正常" ;
VAL_ 1153 ADAS_ChkInvldSig_PLG 1 "异常" 0 "正常" ;
VAL_ 1153 ADAS_ChkInvldSig_CIM 1 "异常" 0 "正常" ;
VAL_ 1153 ADAS_ChkInvldSig_VCU 1 "异常" 0 "正常" ;
VAL_ 1153 ADAS_ChkInvldSig_ICC 1 "异常" 0 "正常" ;
VAL_ 1153 ADAS_ChkInvldSig_PEPS 1 "异常" 0 "正常" ;
VAL_ 1153 ADAS_ChkInvldSig_TPMS 1 "异常" 0 "正常" ;
VAL_ 1153 ADAS_ChkInvldSig_AVAP 1 "异常" 0 "正常" ;
VAL_ 1153 ADAS_ComE2EFlt 1 "异常" 0 "正常" ;
VAL_ 1153 ADAS_ComLostFlt_MPC 1 "异常" 0 "正常" ;
VAL_ 1153 ADAS_ComLostFlt_CMRR_RL 1 "异常" 0 "正常" ;
VAL_ 1153 ADAS_ComLostFlt_CMRR_FL 1 "异常" 0 "正常" ;
VAL_ 1153 ADAS_ComLostFlt_CMRR_RR 1 "异常" 0 "正常" ;
VAL_ 1153 ADAS_ComLostFlt_CMRR_FR 1 "异常" 0 "正常" ;
VAL_ 1153 ADAS_ComLostFlt_MRR 1 "异常" 0 "正常" ;
VAL_ 1153 ADAS_ComLostFlt_ESP 1 "异常" 0 "正常" ;
VAL_ 1153 ADAS_ComLostFlt_SDM 1 "异常" 0 "正常" ;
VAL_ 1153 ADAS_ComLostFlt_EPS 1 "异常" 0 "正常" ;
VAL_ 1153 ADAS_ComLostFlt_iBooster 1 "异常" 0 "正常" ;
VAL_ 1153 ADAS_ComLostFlt_YRS 1 "异常" 0 "正常" ;
VAL_ 1153 ADAS_ComLostFlt_BCM 1 "异常" 0 "正常" ;
VAL_ 1153 ADAS_ComLostFlt_ECC 1 "异常" 0 "正常" ;
VAL_ 1153 ADAS_ComLostFlt_TBOX 1 "异常" 0 "正常" ;
VAL_ 1153 ADAS_ComLostFlt_MCU_F 1 "异常" 0 "正常" ;
VAL_ 1153 ADAS_ComLostFlt_MCU_R 1 "异常" 0 "正常" ;
VAL_ 1153 ADAS_ComLostFlt_PLG 1 "异常" 0 "正常" ;
VAL_ 1153 ADAS_ComLostFlt_CIM 1 "异常" 0 "正常" ;
VAL_ 1153 ADAS_ComLostFlt_VCU 1 "异常" 0 "正常" ;
VAL_ 1153 ADAS_ComLostFlt_ICC 1 "异常" 0 "正常" ;
VAL_ 1153 ADAS_ComLostFlt_PEPS 1 "异常" 0 "正常" ;
VAL_ 1153 ADAS_ComLostFlt_TPMS 1 "异常" 0 "正常" ;
VAL_ 1153 ADAS_ComLostFlt_AVAP 1 "异常" 0 "正常" ;
VAL_ 1153 ADAS_ChkPublicCANBusOff 1 "异常" 0 "正常" ;
VAL_ 1153 ADAS_MstRAMTestErr 1 "异常" 0 "正常" ;
VAL_ 1153 ADAS_MstNVRAMTestErr 1 "异常" 0 "正常" ;
VAL_ 1153 ADAS_NVMChipErr 1 "异常" 0 "正常" ;
VAL_ 1153 ADAS_NVMStructErr 1 "异常" 0 "正常" ;
VAL_ 1153 ADAS_MstWdgErr 1 "异常" 0 "正常" ;
VAL_ 1153 ADAS_MstSOPTErr 1 "异常" 0 "正常" ;
VAL_ 1154 ADAS_MstHwstartupErr 1 "异常" 0 "正常" ;
VAL_ 1154 ADAS_MstHwCycTest 1 "异常" 0 "正常" ;
VAL_ 1154 ADAS_EOLCalOutOfRng 1 "异常" 0 "正常" ;
VAL_ 1154 ADAS_ECUTFlt 1 "异常" 0 "正常" ;
VAL_ 1154 ADAS_PwrModFlt 1 "异常" 0 "正常" ;
VAL_ 1154 ADAS_ComLostFlt_MFS 1 "异常" 0 "正常" ;
VAL_ 1154 ADAS_PrivateCANComE2EFlt_MPC 1 "异常" 0 "正常" ;
VAL_ 1154 ADAS_PrivateCANComE2EFlt_MRR 1 "异常" 0 "正常" ;
VAL_ 1154 ADAS_PrivateCANComE2EFlt_CMRR_FL 1 "异常" 0 "正常" ;
VAL_ 1154 ADAS_PrivateCANComE2EFlt_CMRR_FR 1 "异常" 0 "正常" ;
VAL_ 1154 ADAS_PrivateCANComE2EFlt_CMRR_RL 1 "异常" 0 "正常" ;
VAL_ 1154 ADAS_PrivateCANComE2EFlt_CMRR_RR 1 "异常" 0 "正常" ;
VAL_ 1154 ADAS_PrivateCANComLostFlt_MPC 1 "异常" 0 "正常" ;
VAL_ 1154 ADAS_PrivateCANComLostFlt_MRR 1 "异常" 0 "正常" ;
VAL_ 1154 ADAS_PrivateCANComLost_CMRR_FL 1 "异常" 0 "正常" ;
VAL_ 1154 ADAS_PrivateCANComLost_CMRR_FR 1 "异常" 0 "正常" ;
VAL_ 1154 ADAS_PrivateCANComLost_CMRR_RL 1 "异常" 0 "正常" ;
VAL_ 1154 ADAS_PrivateCANComLost_CMRR_RR 1 "异常" 0 "正常" ;
VAL_ 1154 ADAS_PERChkIntFltInfo 1 "异常" 0 "正常" ;
VAL_ 1154 ADAS_HWAActvFlg 1 "激活" 0 "未激活" ;
VAL_ 1154 ADAS_HWASucFlg 1 "完成" 0 "未完成" ;
VAL_ 1162 ADAS_RDPActvFlg 1 "激活" 0 "未激活" ;
VAL_ 1162 ADAS_ELKActvFlg 1 "激活" 0 "未激活" ;
VAL_ 792 ESP_VehSpdVld 3 "Reserved" 2 "Invalid" 1 "Valid" 0 "Initializing" ;
VAL_ 792 ESP_LampSwtOffIndcn 1 "Telltale Requested" 0 "No Telltale Requested" ;
VAL_ 792 ESP_FltIndcn_ABS 1 "Telltale Requested" 0 "No Telltale Requested" ;
VAL_ 792 ESP_FltIndcn_TCS 1 "Telltale Requested" 0 "No Telltale Requested" ;
VAL_ 792 ESP_CtrlSts_HDC 3 "Reserved" 2 "On Not Active Braking" 1 "On Active Braking" 0 "Off" ;
VAL_ 792 ESP_NoBrkP 1 "No Brk Force" 0 "Exist Brk Force" ;
VAL_ 609 ESP_ActvSig 1 "ESP Actually Operating" 0 "ESP Standby" ;
VAL_ 609 ESP_ActvSig_TCS 1 "TCS Actually Operating" 0 "TCS Standby" ;
VAL_ 609 ESP_ActvSig_EBD 1 "EBD Active" 0 "EBD Not Active" ;
VAL_ 609 ESP_ActvSig_DTC 1 "DTC Active" 0 "DTC Not Active" ;
VAL_ 609 ESP_Actvndcn_CDD 1 "Active" 0 "Not Active" ;
VAL_ 609 ESP_FltIndcn_CDD 1 "Not Available" 0 "Available" ;
VAL_ 609 ESP_ActvIndcn_ABA 1 "Active" 0 "Not Active" ;
VAL_ 609 ESP_FltIndcn_ABA 1 "Not Available" 0 "Available" ;
VAL_ 609 ESP_ActvIndcn_ABP 1 "Active" 0 "Not Active" ;
VAL_ 609 ESP_FltIndcn_ABP 1 "Not Available" 0 "Available" ;
VAL_ 609 ESP_ActvIndcn_AEB 1 "Active" 0 "Not Active" ;
VAL_ 609 ESP_FltIndcn_AEB 1 "Not Available" 0 "Available" ;
VAL_ 609 ESP_ActvIndcn_AWB 1 "Active" 0 "Not Active" ;
VAL_ 609 ESP_FltIndcn_AWB 1 "Not Available" 0 "Available" ;
VAL_ 609 ESP_VehStandstillIndcn 3 "Reserved" 2 "Invalid" 1 "Standstill" 0 "Not Standstill" ;
VAL_ 609 ESP_BrkOverTIndcn 1 "Temp Too High" 0 "Not High" ;
VAL_ 773 ESP_WhlSpdVld_RF 3 "Reserved" 2 "Invalid" 1 "Valid" 0 "Initializing" ;
VAL_ 773 ESP_WhlMovgDir_RF 7 "Reserved" 6 "Reserved" 5 "Reserved" 4 "Invalid" 3 "Stop" 2 "Backward" 1 "Forward" 0 "Init" ;
VAL_ 773 ESP_WhlMovgDir_LF 7 "Reserved" 6 "Reserved" 5 "Reserved" 4 "Invalid" 3 "Stop" 2 "Backward" 1 "Forward" 0 "Init" ;
VAL_ 773 ESP_WhlSpdVld_LF 3 "Reserved" 2 "Invalid" 1 "Valid" 0 "Initializing" ;
VAL_ 774 ESP_WhlSpdVld_RR 3 "Reserved" 2 "Invalid" 1 "Valid" 0 "Initializing" ;
VAL_ 774 ESP_WhlMovgDir_RR 7 "Reserved" 6 "Reserved" 5 "Reserved" 4 "Invalid" 3 "Stop" 2 "Backward" 1 "Forward" 0 "Init" ;
VAL_ 774 ESP_WhlMovgDir_RL 7 "Reserved" 6 "Reserved" 5 "Reserved" 4 "Invalid" 3 "Stop" 2 "Backward" 1 "Forward" 0 "Init" ;
VAL_ 774 ESP_WhlSpdVld_RL 3 "Reserved" 2 "Invalid" 1 "Valid" 0 "Initializing" ;
VAL_ 818 ESP_BrkLiReq 1 "Illuminate" 0 "Not Illuminate" ;
VAL_ 616 ESP_SysSts_EPB 7 "Reserved" 6 "Reserved" 5 "Reserved" 4 "Locking 卡钳正处于夹紧过程中" 3 "Releasing 卡钳正处于释放过程中" 2 "Closed 卡钳处于夹紧状态" 1 "Released 卡钳处于释放状态" 0 "Undefined 未定义" ;
VAL_ 616 ESP_FltIndcn_EPB 3 "Reserved" 2 "In Diagnosis" 1 "Not Available" 0 "Available" ;
VAL_ 616 ESP_YawRateStabnAvl 1 "Full" 0 "None" ;
VAL_ 616 ESP_EPBSwtichPosition 3 "Reserved" 2 "Apply" 1 "Release" 0 "Neutral" ;
VAL_ 288 ESP_ActvSig_ABS 1 "ABS Actually Operating" 0 "ABS Standby" ;
VAL_ 288 ESP_VmcVseYawRateAvlCpby 7 "Reserved" 6 "Reserved" 5 "Reserved" 4 "AvlCpbyHi 高质量" 3 "AvlCpbyMid 中质量" 2 "AvlCpbyLo 低质量" 1 "Fault 故障" 0 "NotAvl 初始化" ;
VAL_ 288 ESP_MstCylPVld 3 "Reserved" 2 "Invalid" 1 "Valid" 0 "Initializing" ;
VAL_ 288 ESP_VmcVseSasAvlCpby 7 "Reserved" 6 "Reserved" 5 "Reserved" 4 "AvlCpbyHi 高质量" 3 "AvlCpbyMid 中质量" 2 "AvlCpbyLo 低质量" 1 "Fault 故障" 0 "NotAvl 初始化" ;
VAL_ 288 ESP_MstCylPOffsVld 3 "Reserved" 2 "Invalid" 1 "Valid" 0 "Initializing" ;
VAL_ 290 ESP_VmcVseLgtPrimSrvAvlCpby 7 "Reserved" 6 "Reserved" 5 "Reserved" 4 "AvlCpbyHi 高质量" 3 "AvlCpbyMid 中质量" 2 "AvlCpbyLo 低质量" 1 "Fault 故障" 0 "NotAvl 初始化" ;
VAL_ 290 ESP_VmcVseSasOffset 65535 "Invalid" ;
VAL_ 625 iBooster_BrkPedlAppldFlg 1 "Brake Pedal Applied" 0 "Brake Pedal Not Applied" ;
VAL_ 625 iBooster_BrkPedlAppldVld 3 "Reserved" 2 "Invalid" 1 "Valid" 0 "Initializing" ;
VAL_ 450 EPS_SteerWhlAgSig 65535 "Invalid" ;
VAL_ 450 EPS_SteerAgSnsrCalSts 1 "已标定" 0 "未标定" ;
VAL_ 450 EPS_SteerWhlAgSigVld 3 "Reserved" 2 "Invalid" 1 "Valid" 0 "Initializing" ;
VAL_ 450 EPS_SteerWhlRotSpdVld 3 "Reserved" 2 "Invalid" 1 "Valid" 0 "Initializing" ;
VAL_ 450 EPS_WarnVbrnSts 1 "Active" 0 "Not Active" ;
VAL_ 450 EPS_SteerWhlVbrnAlrmAvl 3 "Reserved" 2 "Failure 失败" 1 "Not Available 可用" 0 "Available" ;
VAL_ 452 EPS_DrvrSteerTqDir 1 "Negative 顺时针" 0 "Postive 逆时针" ;
VAL_ 452 EPS_DrvrSteerTqVld 3 "Reserved" 2 "Invalid" 1 "Valid" 0 "Initializing" ;
VAL_ 452 EPS_EmgyCtrlSts 3 "Reserved  保留" 2 "Failure   失败" 1 "Control Not Available" 0 "Control Available 可用" ;
VAL_ 452 EPS_EPSAvl 3 "Reserved  保留" 2 "Failure   失败" 1 "Available可用" 0 "Not Available" ;
VAL_ 452 EPS_SteerSnsrSts 1 "Failure" 0 "Not Failure" ;
VAL_ 452 EPS_LatMtnCtrlSts 1 "Active" 0 "Not Active" ;
VAL_ 452 EPS_PinionAg 65535 "Invalid" 65534 "Initializing" ;
VAL_ 1141 EPS_ModSts 3 "Reserved" 2 "Comfort" 1 "Sport" 0 "Reserved" ;
VAL_ 793 SDM_AirBagSysAlrmLampSts 3 "Reserved" 2 "Lamp On" 1 "Lamp Flash" 0 "Lamp Off" ;
VAL_ 793 SDM_DrverSecuBltAlrmSts 3 "Reserved" 2 "Lamp On(Safety Belt Not Tied)" 1 "Fault(Reserved)" 0 "Lamp Off(Safety Belt Tied)" ;
VAL_ 793 SDM_PassSecuBltAlrmSts 3 "Reserved" 2 "Lamp On(Safety Belt Not Tied)" 1 "Fault(Reserved)" 0 "Lamp Off(Safety Belt Tied)" ;
VAL_ 793 SDM_CllsnSig 1 "Crash" 0 "No Crash" ;
VAL_ 793 SDM_FrntCllsn 1 "发生正面碰撞" 0 "未发生正面碰撞" ;
VAL_ 793 SDM_LeSideCllsn 1 "发生左侧面碰撞" 0 "未发生左侧面碰撞" ;
VAL_ 793 SDM_RiSideCllsn 1 "发生右侧面碰撞" 0 "未发生右侧面碰撞" ;
VAL_ 793 SDM_ReCllsn 1 "发生后面碰撞" 0 "未发生后面碰撞" ;
VAL_ 578 YRS_YawRateCalSts 1 "Sensor Calibrated" 0 "Sensor Not Calibrated" ;
VAL_ 578 YRS_YawRateSnsrSts 3 "Reserved" 2 "Invalid" 1 "Valid" 0 "Initializing" ;
VAL_ 578 YRS_LatSnsrSts 3 "Reserved" 2 "Invalid" 1 "Valid" 0 "Initializing" ;
VAL_ 582 YRS_LgtSnsrSts 3 "Reserved" 2 "Invalid" 1 "Valid" 0 "Initializing" ;
VAL_ 821 BCM_ReFogLampSwtSts 1 "Active" 0 "Inactive" ;
VAL_ 821 BCM_DangerAlrmLampSwtSts 1 "On" 0 "Off" ;
VAL_ 821 BCM_LeTrunLampOutpCmd 1 "On" 0 "Off" ;
VAL_ 821 BCM_RiTrunLampOutpCmd 1 "On" 0 "Off" ;
VAL_ 821 BCM_ReWiprOutpCmd 1 "On" 0 "Off" ;
VAL_ 821 BCM_HiBeamOutpCmd 1 "On" 0 "Off" ;
VAL_ 821 BCM_LoBeamOutpCmd 1 "On" 0 "Off" ;
VAL_ 835 BCM_FrntHoodLidSts 1 "Open" 0 "Closed" ;
VAL_ 835 BCM_LeFrntDoorSts 1 "Open" 0 "Closed" ;
VAL_ 835 BCM_RiFrntDoorSts 1 "Open" 0 "Closed" ;
VAL_ 835 BCM_RiReDoorSts 1 "Open" 0 "Closed" ;
VAL_ 835 BCM_LeReDoorSts 1 "Open" 0 "Closed" ;
VAL_ 883 ECC_OutdT 255 "Invalid" ;
VAL_ 883 ECC_OutdTVld 3 "Reserved" 2 "Invalid" 1 "Valid" 0 "Initializing" ;
VAL_ 1410 ECC_InsdT 255 "Invalid" ;
VAL_ 1583 TBOX_CrtTi_Day 30 "Day31" 0 "Day1" ;
VAL_ 1583 TBOX_CrtTi_Hr 23 "Hour 23" 0 "Hour 0" ;
VAL_ 1583 TBOX_CrtTi_Mins 59 "Mintue 59" 0 "Mintue 0" ;
VAL_ 1583 TBOX_CrtTi_Yr 255 "Year2270" 0 "Year 2015" ;
VAL_ 1583 TBOX_CrtTi_Mth 11 "December" 0 "January" ;
VAL_ 1583 TBOX_CrtTi_Sec 59 "Second 59" 0 "Second 0" ;
VAL_ 336 MCU_F_CrtSpd 65535 "Invalid" ;
VAL_ 336 MCU_F_CrtSpdSigVld 3 "Reserved" 2 "Invalid" 1 "Valid" 0 "Initializing" ;
VAL_ 337 MCU_R_CrtSpd 65535 "Invalid" ;
VAL_ 337 MCU_R_CrtSpdSigVld 3 "Reserved" 2 "Invalid" 1 "Valid" 0 "Initializing" ;
VAL_ 1137 PLG_TrSwtStsIndcn 7 "Reserved" 6 "Reserved" 5 "Reserved" 4 "Trunk Closing" 3 "Trunk Opening" 2 "Trunk Halt" 1 "Trunk Open Fully" 0 "Trunk Closed" ;
VAL_ 784 CIM_TurnLampSwtSts 3 "Invalid" 2 "Turn Right 右转向状态" 1 "Turn Left 左转向状态" 0 "Default 默认状态" ;
VAL_ 784 CIM_HiBeamSwtSts 3 "Invalid" 2 "Toggle 远光灯位置" 1 "Flash 超车灯打开" 0 "Neutral 中间位置" ;
VAL_ 784 CIM_FrntWshrSwtSts 3 "Invalid" 2 "Reserved" 1 "On 前洗涤打开" 0 "Off 前洗涤关闭" ;
VAL_ 784 CIM_ReWshrSwtSts 3 "Invalid" 2 "Reserved" 1 "On 后洗涤打开" 0 "Off 后洗涤关闭" ;
VAL_ 784 CIM_FrntWiprSwtSts 7 "Invalid" 6 "Reserved" 5 "Reserved" 4 "High 连续高速刮动" 3 "Low 连续低速刮动" 2 "AutoHigh 雨刮自动(高灵敏度)" 1 "AutoLow 雨刮自动(低灵敏度)" 0 "Off 默认值" ;
VAL_ 784 CIM_Swt_ADAS 3 "Invalid" 2 "Double Pressed 双拨" 1 "Pressed One 单拨" 0 "Not Pressed 默认位置" ;
VAL_ 784 CIM_Cncl_ADAS 3 "Invalid" 2 "Reserved" 1 "Pressed向后拨动" 0 "Not Pressed默认位置" ;
VAL_ 784 CIM_SpdRgln_ADAS 7 "Invalid" 6 "Reserved" 5 "Reserved" 4 "Speed-5车速-5" 3 "Speed-1车速-1" 2 "Speed+5 车速+5" 1 "Speed +1车速+1" 0 "Inactive/Default" ;
VAL_ 784 CIM_DstWithCarFrntAdj 7 "Invalid" 6 "Reserved 预留" 5 "5 Gear 5档" 4 "4 Gear 4档" 3 "3 Gear 3档" 2 "2 Gear 2档" 1 "1 Gear 1档" 0 "Inactive/Default" ;
VAL_ 784 CIM_SpdLim_ADAS 3 "Invalid" 2 "Reserved" 1 "Pressed 按键按下" 0 "Not Pressed 按键未按下" ;
VAL_ 784 CIM_SwtVld_ADAS 3 "Reserved" 2 "Invalid" 1 "Valid" 0 "Initializing" ;
VAL_ 784 CIM_SpdRglnVld_ADAS 3 "Reserved" 2 "Invalid" 1 "Valid" 0 "Initializing" ;
VAL_ 549 VCU_OverMod 1 "Driver Override 驾驶员覆盖" 0 "No Override 不覆盖" ;
VAL_ 549 VCU_MotChkACCFltFbFlg 3 "Reserved" 2 "Irreversible Error(Reserved) 错误不可逆" 1 "Reversible Error 错误可逆" 0 "No Error 无错误" ;
VAL_ 549 VCU_VehTqFltSts 1 "Failure" 0 "No Failure" ;
VAL_ 532 VCU_RdyLamp 1 "已准备好" 0 "未准备好" ;
VAL_ 532 VCU_GearSigVld 3 "Reserved" 2 "Invalid" 1 "Valid" 0 "Initializing" ;
VAL_ 532 VCU_GearSig 15 "Reserved" 14 "Reserved" 13 "Reserved" 12 "Reserved" 11 "Reserved" 10 "Reserved" 9 "Reserved" 8 "Reserved" 7 "S挡" 6 "E挡" 5 "Reserved" 4 "D挡" 3 "R挡" 2 "N挡" 1 "P挡" 0 "Undefined 初始值" ;
VAL_ 532 VCU_DrvModSig 7 "E-Pedal模式" 6 "沙地模式" 5 "泥地模式" 4 "雪地模式" 3 "经济模式" 2 "舒适模式" 1 "运动模式" 0 "初始值" ;
VAL_ 1317 EHU_GPSLongi 359991 "Invalid" ;
VAL_ 1317 EHU_GPSLati 180000 "Invalid" ;
VAL_ 822 EHU_SpdLimOffs 15 "Invalid" ;
VAL_ 1318 EHU_IntegtCrsSwt 3 "Fault" 2 "Switch On 开关打开" 1 "Switch Off 开关关闭" 0 "Default 初始值" ;
VAL_ 1318 EHU_IntegtCrsModSet 3 "HWA" 2 "TJA\ICA" 1 "ACC" 0 "Default 初始值" ;
VAL_ 1318 EHU_LaneSprtSwt 3 "Fault" 2 "Switch On 开关打开" 1 "Switch Off 开关关闭" 0 "Default 初始值" ;
VAL_ 1318 EHU_LaneSprtTypSet 3 "Reserved" 2 "LDW RDP ELK 纠偏警示" 1 "LDW 警示" 0 "Default 初始值" ;
VAL_ 1318 EHU_FCWFCTASwt 3 "Fault" 2 "Switch On 开关打开" 1 "Switch Off 开关关闭" 0 "Default 初始值" ;
VAL_ 1318 EHU_AEBFCTBSwt 3 "Fault" 2 "Switch On 开关打开" 1 "Switch Off 开关关闭" 0 "Default 初始值" ;
VAL_ 1318 EHU_ESSSwt 3 "Fault" 2 "Switch On 开关打开" 1 "Switch Off 开关关闭" 0 "Default 初始值" ;
VAL_ 1318 EHU_LDWAlrmTypReq 3 "震动" 2 "声光震动报警" 1 "声光报警" 0 "Default 初始值" ;
VAL_ 1318 EHU_ADASSnvtySet 3 "Fault" 2 "High 正常模式" 1 "Low 新手模式" 0 "Default 初始值" ;
VAL_ 1318 EHU_HiwayExitAuxReq 1 "Active" 0 "Not Active" ;
VAL_ 1318 EHU_HiwayExitAuxSwt 3 "Reserved" 2 "Switch On 开关打开" 1 "Switch Off 开关关闭" 0 "Default 初始值" ;
VAL_ 1318 EHU_VoiceSpdRgln_ADAS 255 "Invalid" ;
VAL_ 1329 ICM_TotMilgVld_ODO 1 "Value Unreliable" 0 "Value OK" ;
VAL_ 1329 ICM_DispVehSpdUnit 1 "MPH" 0 "KMH" ;
VAL_ 1329 ICM_ADASSigFlt 3 "Reserved" 2 "Irrversible Failure" 1 "Reversible Failure" 0 "No Failure" ;
VAL_ 1329 ICM_DispFlt 1 "Error 有错误" 0 "No Error 无错误" ;
VAL_ 1328 EHU_NavSpdLimUnit 3 "Reserved" 2 "KMH" 1 "MPH" 0 "Unknown" ;
VAL_ 1328 EHU_NavSpdLimSts 3 "SL_Plural" 2 "SL_Nolimit" 1 "SL_Exists" 0 "SL_Unknown" ;
VAL_ 1328 EHU_NavSpdLim 63 "Reserved" 62 "Reserved" 61 "Reserved" 60 "Reserved" 59 "Reserved" 58 "Reserved" 57 "Reserved" 56 "Reserved" 55 "Reserved" 54 "Reserved" 53 "Reserved" 52 "Reserved" 51 "Reserved" 50 "Reserved" 49 "Reserved" 48 "Reserved" 47 "Reserved" 46 "Reserved" 45 "Reserved" 44 "Reserved" 43 "Reserved" 42 "Reserved" 41 "Reserved" 40 "Reserved" 39 "Reserved" 38 "Reserved" 37 "Reserved" 36 "Reserved" 35 "Reserved" 34 "Reserved" 33 "Reserved" 32 "Reserved" 31 "Reserved" 30 "Reserved" 29 "Reserved" 28 "Reserved" 27 "Reserved" 26 "SPL 130" 5 "SPL 25" 4 "SPL 20" 3 "SPL 15" 2 "SPL 10" 1 "SPL 5" 0 "No Display" ;
VAL_ 830 MRR_FrntSnsrFlt 3 "Reserved" 2 "Irrversible Failure" 1 "Reversible Failure" 0 "No Failure" ;
VAL_ 830 MRR_FrntSnsrBli 3 "Reserved" 2 "Reserved" 1 "Blind" 0 "No Blind" ;
VAL_ 820 MPC_FrntCamBli 3 "Reserved" 2 "Reserved" 1 "Blind" 0 "No Blind" ;
VAL_ 820 MPC_FrntCamFlt 3 "Reserved" 2 "Irrversible Failure" 1 "Reversible Failure" 0 "No Failure" ;
VAL_ 824 CMRR_RL_LeWarn_LCA 3 "Reserved" 2 "Warning Level 2" 1 "Warning Level 1" 0 "No Warning" ;
VAL_ 824 CMRR_RL_SnsrFlt 3 "Reserved" 2 "Irrversible Failure" 1 "Reversible Failure" 0 "No Failure" ;
VAL_ 824 CMRR_RL_SnsrBli 3 "Reserved" 2 "Reserved" 1 "Blind" 0 "No Blind" ;
VAL_ 824 CMRR_RL_LeWarn_LCA_ELK 3 "Reserved" 2 "Warning Level 2" 1 "Warning Level 1" 0 "No Warning" ;
VAL_ 824 CMRR_RL_SDASts 3 "Dynamic calibration running" 2 "Fault" 1 "No Fault" 0 "Default" ;
VAL_ 824 CMRR_RL_SDAWarn 1 "Active" 0 "Inactive" ;
VAL_ 606 CMRR_FR_FrntLeSnsrFlt 3 "Reserved" 2 "Irrversible Failure" 1 "Reversible Failure" 0 "No Failure" ;
VAL_ 606 CMRR_FR_FrntLeSnsrBli 3 "Reserved" 2 "Reserved" 1 "Blind" 0 "No Blind" ;
VAL_ 606 CMRR_FR_SDASts 3 "Dynamic calibration running" 2 "Fault" 1 "No Fault" 0 "Default" ;
VAL_ 606 CMRR_FR_SDAWarn 1 "Active" 0 "Inactive" ;
VAL_ 604 CMRR_FL_FrntLeSnsrFlt 3 "Reserved" 2 "Irrversible Failure" 1 "Reversible Failure" 0 "No Failure" ;
VAL_ 604 CMRR_FL_FrntLeSnsrBli 3 "Reserved" 2 "Reserved" 1 "Blind" 0 "No Blind" ;
VAL_ 604 CMRR_FL_SDASts 3 "Dynamic calibration running" 2 "Fault" 1 "No Fault" 0 "Default" ;
VAL_ 604 CMRR_FL_SDAWarn 1 "Active" 0 "Inactive" ;
VAL_ 826 CMRR_RR_RiWarn_LCA 3 "Reserved" 2 "Warning Level 2" 1 "Warning Level 1" 0 "No Warning" ;
VAL_ 826 CMRR_RR_SnsrFlt 3 "Reserved" 2 "Irrversible Failure" 1 "Reversible Failure" 0 "No Failure" ;
VAL_ 826 CMRR_RR_SnsrBli 3 "Reserved" 2 "Reserved" 1 "Blind" 0 "No Blind" ;
VAL_ 826 CMRR_RR_LCASwtFb 3 "Fault" 2 "Switch On开关打开" 1 "Switch Off 开关关闭" 0 "Default 初始值" ;
VAL_ 826 CMRR_RR_RiWarn_LCA_ELK 3 "Reserved" 2 "Warning Level 2" 1 "Warning Level 1" 0 "No Warning" ;
VAL_ 826 CMRR_RR_SDAWarn 1 "Active" 0 "Inactive" ;
VAL_ 826 CMRR_RR_SDASts 3 "Dynamic calibration running" 2 "Fault" 1 "No Fault" 0 "Default" ;
VAL_ 819 PEPS_PwrMod 7 "Reserved" 6 "Reserved" 5 "Crank Off (Reserved)" 4 "Run" 3 "Crank Pending(动力防盗认证过程中)" 2 "IGN On" 1 "ACC (Reserved)" 0 "Off" ;
VAL_ 819 PEPS_PwrModVld 3 "Reserved" 2 "Invalid" 1 "Valid" 0 "Initializing" ;
VAL_ 1417 TPMS_TirePosn 7 "Reserved" 6 "Reserved" 5 "Reserved" 4 "右后轮胎" 3 "左后轮胎" 2 "右前轮胎" 1 "左前轮胎" 0 "No Any Sensor" ;
VAL_ 1417 TPMS_SngTirePSts 3 "Reserved" 2 "低压" 1 "过压" 0 "正常" ;
VAL_ 1319 EHU_DrvrSts 7 "Reserved" 6 "Reserved" 5 "Reserved" 4 "No  Detection" 3 "无法识别" 2 "分心状态" 1 "疲劳状态" 0 "正常状态" ;
VAL_ 1319 EHU_DrvrOccpy 3 "Reserved" 2 "No Detection" 1 "Drive Not In Seat" 0 "Driver In Seat" ;
VAL_ 432 APA_Sts 15 "Reserved" 14 "Reserved" 13 "Reserved" 12 "Reserved" 11 "Reserved" 10 "Reserved" 9 "Failured" 8 "Ended/Cancel" 7 "Finishing" 6 "Paused" 5 "Manoeuvering" 4 "Confirming" 3 "Selecting" 2 "Active Scanning" 1 "Background Scanning" 0 "Not Active" ;
VAL_ 658 APA_CrtPrkgTyp 3 "Reserved" 2 "Remote" 1 "Automated" 0 "None" ;
VAL_ 1368 APA_Sts_PAS 3 "Failed" 2 "Active" 1 "Enable" 0 "Disable" ;
VAL_ 672 APA_FMEBSts 15 "Reserved" 14 "Reserved" 13 "Reserved" 12 "Reserved" 11 "Reserved" 10 "Reserved" 9 "Error" 8 "Finished Without Override" 7 "Finished With Override" 6 "Secure" 5 "Standstill" 4 "AEB Active" 3 "PreFill" 2 "Ready" 1 "Inactive" 0 "OFF" ;
VAL_ 672 APA_RMEBSts 15 "Reserved" 14 "Reserved" 13 "Reserved" 12 "Reserved" 11 "Reserved" 10 "Reserved" 9 "Error" 8 "Finished Without Override" 7 "Finished With Override" 6 "Secure" 5 "Standstill" 4 "AEB Active" 3 "PreFill" 2 "Ready" 1 "Inactive" 0 "Off" ;
VAL_ 1300 MFS_LeRollPress 3 "长按(按键时间≥10s)" 2 "Long Press" 1 "Pressed" 0 "No Pressed" ;
VAL_ 1300 MFS_RiRollPress 3 "Reserved" 2 "Long Press" 1 "Pressed" 0 "No Pressed" ;
VAL_ 592 EHU_SegFuncRoadClass 7 "普通道路；县乡村内部道路；小路" 6 "次要道路；乡道" 5 "城市主干路；县道" 4 "省道" 3 "国道" 2 "城市快速路" 1 "高速道路" 0 "Unknown" ;
VAL_ 592 EHU_SegEffSpdLmtType 7 "unknown" 6 "Explicit - Snow" 5 "Expl+R[8]Cicit - Rain" 4 "Explicit - Time Of Day" 3 "Explicit - By Day" 2 "Explicit - By Night" 1 "Explicit - On Traffic Sign" 0 "Implicit(For Instance,Default Speed Limit In The Cities)" ;
VAL_ 593 EHU_StubFuncRoadClass 7 "other roads" ;
VAL_ 593 EHU_StubTurnAngl 255 "Invalid" 254 "Unknown" 253 "1.417 Degrees left (358.583 Degrees Right)" 252 "Left From Path Direction" 251 "Left From Path Direction" 250 "Left From Path Direction" 249 "Left From Path Direction" 248 "Left From Path Direction" 247 "Left From Path Direction" 246 "Left From Path Direction" 245 "Left From Path Direction" 244 "Left From Path Direction" 243 "Left From Path Direction" 242 "Left From Path Direction" 241 "Left From Path Direction" 240 "Left From Path Direction" 239 "Left From Path Direction" 238 "Left From Path Direction" 237 "Left From Path Direction" 236 "Left From Path Direction" 235 "Left From Path Direction" 234 "Left From Path Direction" 233 "Left From Path Direction" 232 "Left From Path Direction" 231 "Left From Path Direction" 230 "Left From Path Direction" 229 "Left From Path Direction" 228 "Left From Path Direction" 227 "Left From Path Direction" 226 "Left From Path Direction" 225 "Left From Path Direction" 224 "Left From Path Direction" 223 "Left From Path Direction" 222 "Left From Path Direction" 221 "Left From Path Direction" 220 "Left From Path Direction" 219 "Left From Path Direction" 218 "Left From Path Direction" 217 "Left From Path Direction" 216 "Left From Path Direction" 215 "Left From Path Direction" 214 "Left From Path Direction" 213 "Left From Path Direction" 212 "Left From Path Direction" 211 "Left From Path Direction" 210 "Left From Path Direction" 209 "Left From Path Direction" 208 "Left From Path Direction" 207 "Left From Path Direction" 206 "Left From Path Direction" 205 "Left From Path Direction" 204 "Left From Path Direction" 203 "Left From Path Direction" 202 "Left From Path Direction" 201 "Left From Path Direction" 200 "Left From Path Direction" 199 "Left From Path Direction" 198 "Left From Path Direction" 197 "Left From Path Direction" 196 "Left From Path Direction" 195 "Left From Path Direction" 194 "Left From Path Direction" 193 "Left From Path Direction" 192 "Left From Path Direction" 191 "Left From Path Direction" 190 "Left From Path Direction" 189 "Left From Path Direction" 188 "Left From Path Direction" 187 "Left From Path Direction" 186 "Left From Path Direction" 185 "Left From Path Direction" 184 "Left From Path Direction" 183 "Left From Path Direction" 182 "Left From Path Direction" 181 "Left From Path Direction" 180 "Left From Path Direction" 179 "Left From Path Direction" 178 "Left From Path Direction" 177 "Left From Path Direction" 176 "Left From Path Direction" 175 "Left From Path Direction" 174 "Left From Path Direction" 173 "Left From Path Direction" 172 "Left From Path Direction" 171 "Left From Path Direction" 170 "Left From Path Direction" 169 "Left From Path Direction" 168 "Left From Path Direction" 167 "Left From Path Direction" 166 "Left From Path Direction" 165 "Left From Path Direction" 164 "Left From Path Direction" 163 "Left From Path Direction" 162 "Left From Path Direction" 161 "Left From Path Direction" 160 "Left From Path Direction" 159 "Left From Path Direction" 158 "Left From Path Direction" 157 "Left From Path Direction" 156 "Left From Path Direction" 155 "Left From Path Direction" 154 "Left From Path Direction" 153 "Left From Path Direction" 152 "Left From Path Direction" 151 "Left From Path Direction" 150 "Left From Path Direction" 149 "Left From Path Direction" 148 "Left From Path Direction" 147 "Left From Path Direction" 146 "Left From Path Direction" 145 "Left From Path Direction" 144 "Left From Path Direction" 143 "Left From Path Direction" 142 "Left From Path Direction" 141 "Left From Path Direction" 140 "Left From Path Direction" 139 "Left From Path Direction" 138 "Left From Path Direction" 137 "Left From Path Direction" 136 "Left From Path Direction" 135 "Left From Path Direction" 134 "Left From Path Direction" 133 "Left From Path Direction" 132 "Left From Path Direction" 131 "Left From Path Direction" 130 "Left From Path Direction" 129 "Left From Path Direction" 128 "178.583 Degrees Left (181.417 Degrees Right)+R[6]C" 127 "Opposite Direction" 126 "178.583 Degrees Right" 125 "Right From Path Direction" 124 "Right From Path Direction" 123 "Right From Path Direction" 122 "Right From Path Direction" 121 "Right From Path Direction" 120 "Right From Path Direction" 119 "Right From Path Direction" 118 "Right From Path Direction" 117 "Right From Path Direction" 116 "Right From Path Direction" 115 "Right From Path Direction" 114 "Right From Path Direction" 113 "Right From Path Direction" 112 "Right From Path Direction" 111 "Right From Path Direction" 110 "Right From Path Direction" 109 "Right From Path Direction" 108 "Right From Path Direction" 107 "Right From Path Direction" 106 "Right From Path Direction" 105 "Right From Path Direction" 104 "Right From Path Direction" 103 "Right From Path Direction" 102 "Right From Path Direction" 101 "Right From Path Direction" 100 "Right From Path Direction" 99 "Right From Path Direction" 98 "Right From Path Direction" 97 "Right From Path Direction" 96 "Right From Path Direction" 95 "Right From Path Direction" 94 "Right From Path Direction" 93 "Right From Path Direction" 92 "Right From Path Direction" 91 "Right From Path Direction" 90 "Right From Path Direction" 89 "Right From Path Direction" 88 "Right From Path Direction" 87 "Right From Path Direction" 86 "Right From Path Direction" 85 "Right From Path Direction" 84 "Right From Path Direction" 83 "Right From Path Direction" 82 "Right From Path Direction" 81 "Right From Path Direction" 80 "Right From Path Direction" 79 "Right From Path Direction" 78 "Right From Path Direction" 77 "Right From Path Direction" 76 "Right From Path Direction" 75 "Right From Path Direction" 74 "Right From Path Direction" 73 "Right From Path Direction" 72 "Right From Path Direction" 71 "Right From Path Direction" 70 "Right From Path Direction" 69 "Right From Path Direction" 68 "Right From Path Direction" 67 "Right From Path Direction" 66 "Right From Path Direction" 65 "Right From Path Direction" 64 "Right From Path Direction" 63 "Right From Path Direction" 62 "Right From Path Direction" 61 "Right From Path Direction" 60 "Right From Path Direction" 59 "Right From Path Direction" 58 "Right From Path Direction" 57 "Right From Path Direction" 56 "Right From Path Direction" 55 "Right From Path Direction" 54 "Right From Path Direction" 53 "Right From Path Direction" 52 "Right From Path Direction" 51 "Right From Path Direction" 50 "Right From Path Direction" 49 "Right From Path Direction" 48 "Right From Path Direction" 47 "Right From Path Direction" 46 "Right From Path Direction" 45 "Right From Path Direction" 44 "Right From Path Direction" 43 "Right From Path Direction" 42 "Right From Path Direction" 41 "Right From Path Direction" 40 "Right From Path Direction" 39 "Right From Path Direction" 38 "Right From Path Direction" 37 "Right From Path Direction" 36 "Right From Path Direction" 35 "Right From Path Direction" 34 "Right From Path Direction" 33 "Right From Path Direction" 32 "Right From Path Direction" 31 "Right From Path Direction" 30 "Right From Path Direction" 29 "Right From Path Direction" 28 "Right From Path Direction" 27 "Right From Path Direction" 26 "Right From Path Direction" 25 "Right From Path Direction" 24 "Right From Path Direction" 23 "Right From Path Direction" 22 "Right From Path Direction" 21 "Right From Path Direction" 20 "Right From Path Direction" 19 "Right From Path Direction" 18 "Right From Path Direction" 17 "Right From Path Direction" 16 "Right From Path Direction" 15 "Right From Path Direction" 14 "Right From Path Direction" 13 "Right From Path Direction" 12 "Right From Path Direction" 11 "Right From Path Direction" 10 "Right From Path Direction" 9 "Right From Path Direction" 8 "Right From Path Direction" 7 "Right From Path Direction" 6 "Right From Path Direction" 5 "Right From Path Direction" 4 "Right From Path Direction" 3 "Right From Path Direction" 2 "Right From Path Direction" 1 "1.417 Degrees Right" 0 "In Path Direction" ;
VAL_ 442 VCU_DrvrAPSPercVld 3 "Reserved" 2 "Invalid" 1 "Valid" 0 "Initializing" ;
VAL_ 442 VCU_WhlTqActVld 3 "Reserved" 2 "Invalid" 1 "Valid" 0 "Initializing" ;
